VERSION ""

NS_ :

BS_:

BU_: HSCU BCM RINE BRUSA DCDC HVAC DECM BCM_HS HCSU ACCM_HS VICM_HS

BO_ 1120 BCM_Faults: 8 BCM
 SG_ bcm_dtc_081 m41 : 23|24@0+ (1,0) [0|16777215] "DTC ID"  HSCU
 SG_ bcm_dtc_082 m41 : 47|24@0+ (1,0) [0|16777215] "DTC ID"  HSCU
 SG_ bcm_dtc_083 m42 : 23|24@0+ (1,0) [0|16777215] "DTC ID"  HSCU
 SG_ bcm_dtc_084 m42 : 47|24@0+ (1,0) [0|16777215] "DTC ID"  HSCU
 SG_ bcm_dtc_085 m43 : 23|24@0+ (1,0) [0|16777215] "DTC ID"  HSCU
 SG_ bcm_dtc_086 m43 : 47|24@0+ (1,0) [0|16777215] "DTC ID"  HSCU
 SG_ bcm_dtc_087 m44 : 23|24@0+ (1,0) [0|16777215] "DTC ID"  HSCU
 SG_ bcm_dtc_088 m44 : 47|24@0+ (1,0) [0|16777215] "DTC ID"  HSCU
 SG_ bcm_dtc_089 m45 : 23|24@0+ (1,0) [0|16777215] "DTC ID"  HSCU
 SG_ bcm_dtc_090 m45 : 47|24@0+ (1,0) [0|16777215] "DTC ID"  HSCU
 SG_ bcm_dtc_091 m46 : 23|24@0+ (1,0) [0|16777215] "DTC ID"  HSCU
 SG_ bcm_dtc_092 m46 : 47|24@0+ (1,0) [0|16777215] "DTC ID"  HSCU
 SG_ bcm_dtc_093 m47 : 23|24@0+ (1,0) [0|16777215] "DTC ID"  HSCU
 SG_ bcm_dtc_094 m47 : 47|24@0+ (1,0) [0|16777215] "DTC ID"  HSCU
 SG_ bcm_dtc_095 m48 : 23|24@0+ (1,0) [0|16777215] "DTC ID"  HSCU
 SG_ bcm_dtc_096 m48 : 47|24@0+ (1,0) [0|16777215] "DTC ID"  HSCU
 SG_ bcm_dtc_097 m49 : 23|24@0+ (1,0) [0|16777215] "DTC ID"  HSCU
 SG_ bcm_dtc_098 m49 : 47|24@0+ (1,0) [0|16777215] "DTC ID"  HSCU
 SG_ bcm_dtc_099 m50 : 23|24@0+ (1,0) [0|16777215] "DTC ID"  HSCU
 SG_ bcm_dtc_100 m50 : 47|24@0+ (1,0) [0|16777215] "DTC ID"  HSCU
 SG_ bcm_dtc_statusMask m0 : 15|8@0+ (1,0) [0|255] "ISO14229 statusOfDTC"  HSCU
 SG_ bcm_dtc_page M : 7|8@0+ (1,0) [0|255] "page number"  HSCU

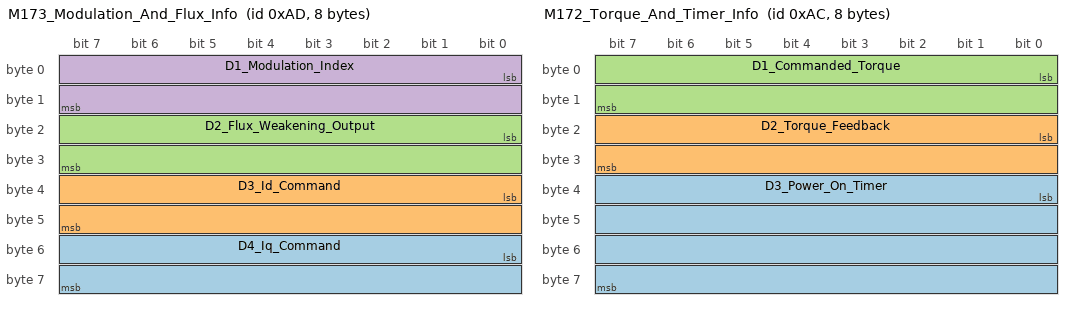
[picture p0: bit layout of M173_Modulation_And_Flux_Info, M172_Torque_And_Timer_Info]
BO_ 173 M173_Modulation_And_Flux_Info: 8 RINE
 SG_ D4_Iq_Command : 48|16@1- (0.1,0) [-3276.8|3276.7] "A" Vector__XXX
 SG_ D3_Id_Command : 32|16@1- (0.1,0) [-3276.8|3276.7] "A" Vector__XXX
 SG_ D2_Flux_Weakening_Output : 16|16@1- (0.1,0) [-3276.8|3276.7] "A" Vector__XXX
 SG_ D1_Modulation_Index : 0|16@1+ (0.01,0) [0|0] "" Vector__XXX

BO_ 172 M172_Torque_And_Timer_Info: 8 RINE
 SG_ D3_Power_On_Timer : 32|32@1+ (0.003,0) [0|4294970000] "Sec" Vector__XXX
 SG_ D2_Torque_Feedback : 16|16@1- (0.1,0) [-3276.8|3276.7] "Nm" Vector__XXX
 SG_ D1_Commanded_Torque : 0|16@1- (0.1,0) [-3276.8|3276.7] "Nm" Vector__XXX

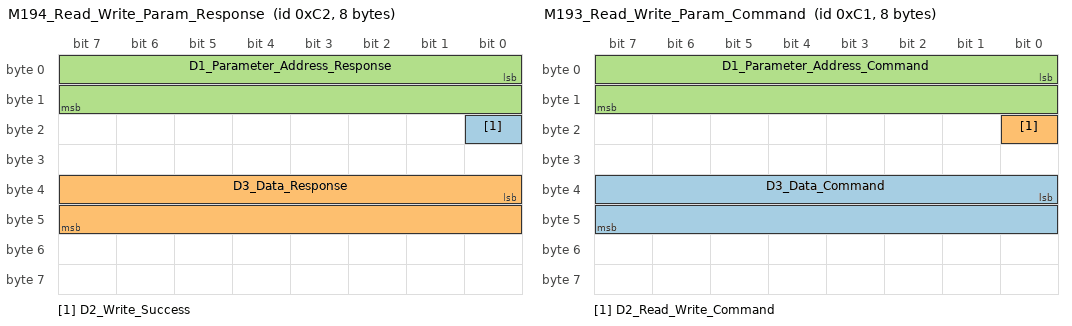
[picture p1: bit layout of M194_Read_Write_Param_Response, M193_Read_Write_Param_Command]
BO_ 194 M194_Read_Write_Param_Response: 8 RINE
 SG_ D2_Write_Success : 16|1@1+ (1,0) [0|1] "" Vector__XXX
 SG_ D3_Data_Response : 32|16@1- (1,0) [-32768|32767] "" Vector__XXX
 SG_ D1_Parameter_Address_Response : 0|16@1+ (1,0) [0|65535] "" Vector__XXX

BO_ 193 M193_Read_Write_Param_Command: 8 HSCU
 SG_ D3_Data_Command : 32|16@1- (1,0) [-32768|32767] "" Vector__XXX
 SG_ D2_Read_Write_Command : 16|1@1+ (1,0) [0|1] "" Vector__XXX
 SG_ D1_Parameter_Address_Command : 0|16@1+ (1,0) [0|65535] "" Vector__XXX

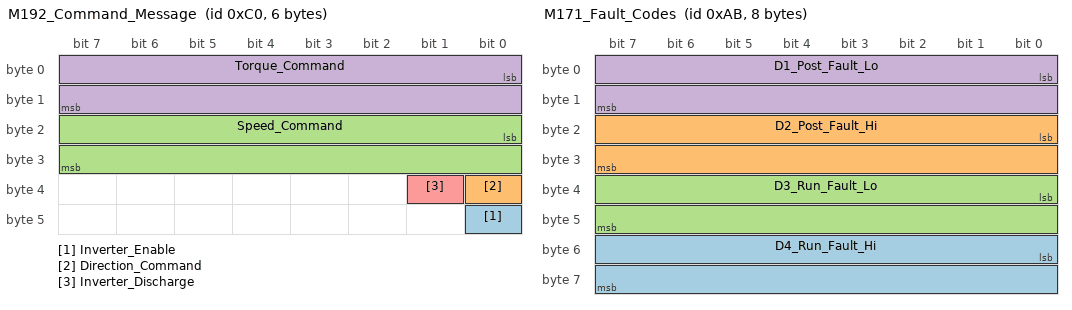
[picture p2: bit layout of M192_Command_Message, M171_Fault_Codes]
BO_ 192 M192_Command_Message: 6 HSCU
 SG_ Inverter_Enable : 40|1@1+ (1,0) [0|1] "Bit" Vector__XXX
 SG_ Direction_Command : 32|1@1+ (1,0) [0|1] "Bit" Vector__XXX
 SG_ Speed_Command : 16|16@1- (1,0) [-32768|32767] "rpm" Vector__XXX
 SG_ Torque_Command : 0|16@1- (0.1,0) [-3276.8|3276.7] "Nm" Vector__XXX
 SG_ Inverter_Discharge : 33|1@1+ (1,0) [0|1] "Bit" Vector__XXX

BO_ 171 M171_Fault_Codes: 8 RINE
 SG_ D4_Run_Fault_Hi : 48|16@1+ (1,0) [0|65535] "" Vector__XXX
 SG_ D2_Post_Fault_Hi : 16|16@1+ (1,0) [0|65535] "" Vector__XXX
 SG_ D3_Run_Fault_Lo : 32|16@1+ (1,0) [0|65535] "" Vector__XXX
 SG_ D1_Post_Fault_Lo : 0|16@1+ (1,0) [0|65535] "" Vector__XXX

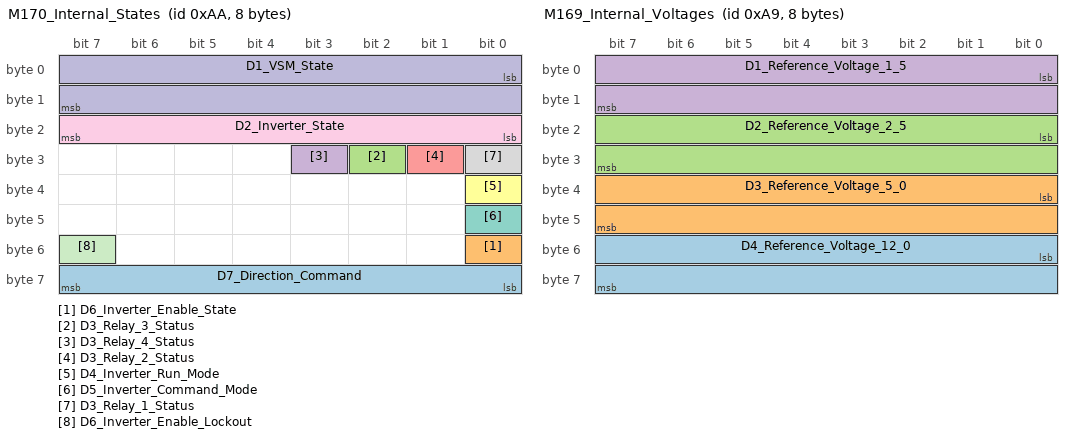
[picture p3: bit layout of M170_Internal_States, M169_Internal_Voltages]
BO_ 170 M170_Internal_States: 8 RINE
 SG_ D7_Direction_Command : 56|8@1+ (1,0) [0|1] "" Vector__XXX
 SG_ D6_Inverter_Enable_State : 48|1@1+ (1,0) [0|1] "" Vector__XXX
 SG_ D3_Relay_3_Status : 26|1@1+ (1,0) [0|1] "" Vector__XXX
 SG_ D3_Relay_4_Status : 27|1@1+ (1,0) [0|1] "" Vector__XXX
 SG_ D3_Relay_2_Status : 25|1@1+ (1,0) [0|1] "" Vector__XXX
 SG_ D4_Inverter_Run_Mode : 32|1@1+ (1,0) [0|1] "" Vector__XXX
 SG_ D5_Inverter_Command_Mode : 40|1@1+ (1,0) [0|1] "" Vector__XXX
 SG_ D3_Relay_1_Status : 24|1@1+ (1,0) [0|1] "" Vector__XXX
 SG_ D2_Inverter_State : 16|8@1+ (1,0) [0|255] "" Vector__XXX
 SG_ D1_VSM_State : 0|16@1+ (1,0) [0|15] "" Vector__XXX
 SG_ D6_Inverter_Enable_Lockout : 55|1@1+ (1,0) [0|1] "" Vector__XXX

BO_ 169 M169_Internal_Voltages: 8 RINE
 SG_ D4_Reference_Voltage_12_0 : 48|16@1- (0.01,0) [-327.68|327.67] "V" Vector__XXX
 SG_ D3_Reference_Voltage_5_0 : 32|16@1- (0.01,0) [-327.68|327.67] "V" Vector__XXX
 SG_ D2_Reference_Voltage_2_5 : 16|16@1- (0.01,0) [-327.68|327.67] "V" Vector__XXX
 SG_ D1_Reference_Voltage_1_5 : 0|16@1- (0.01,0) [-327.68|327.67] "V" Vector__XXX

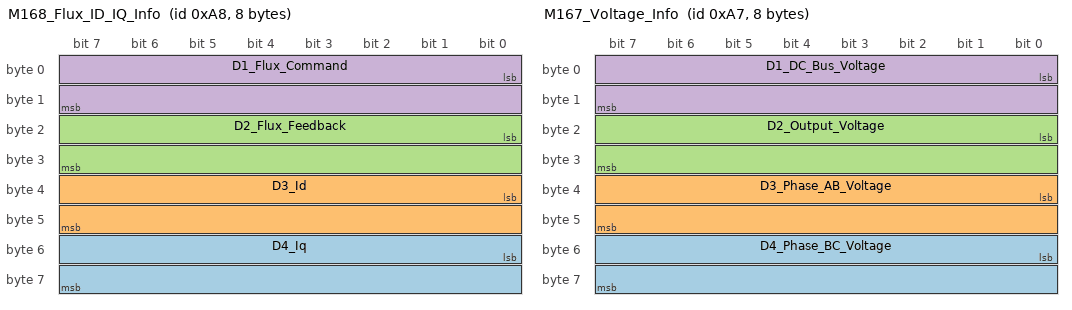
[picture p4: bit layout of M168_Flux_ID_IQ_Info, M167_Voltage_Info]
BO_ 168 M168_Flux_ID_IQ_Info: 8 RINE
 SG_ D4_Iq : 48|16@1- (0.1,0) [-3276.8|3276.7] "A" Vector__XXX
 SG_ D3_Id : 32|16@1- (0.1,0) [-3276.8|3276.7] "A" Vector__XXX
 SG_ D2_Flux_Feedback : 16|16@1- (0.001,0) [-32.768|32.767] "Wb" Vector__XXX
 SG_ D1_Flux_Command : 0|16@1- (0.001,0) [-32.768|32.767] "Wb" Vector__XXX

BO_ 167 M167_Voltage_Info: 8 RINE
 SG_ D4_Phase_BC_Voltage : 48|16@1- (0.1,0) [-3276.8|3276.7] "V" Vector__XXX
 SG_ D3_Phase_AB_Voltage : 32|16@1- (0.1,0) [-3276.8|3276.7] "V" Vector__XXX
 SG_ D2_Output_Voltage : 16|16@1- (0.1,0) [-3276.8|3276.7] "V" Vector__XXX
 SG_ D1_DC_Bus_Voltage : 0|16@1- (0.1,0) [-3276.8|3276.7] "V" Vector__XXX

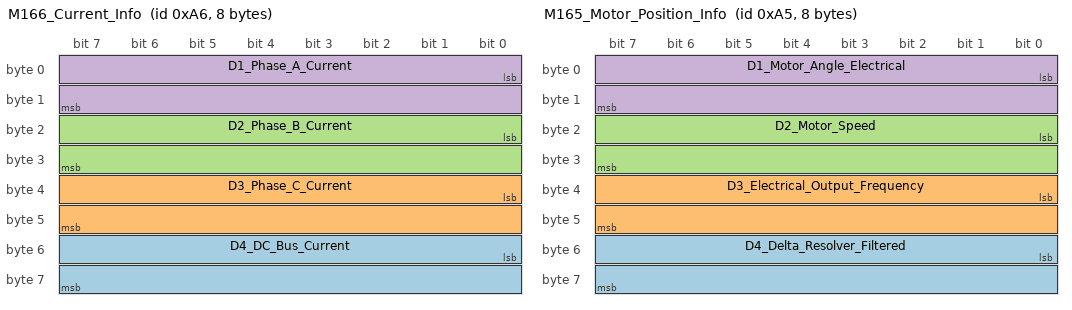
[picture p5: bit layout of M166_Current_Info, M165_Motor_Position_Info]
BO_ 166 M166_Current_Info: 8 RINE
 SG_ D4_DC_Bus_Current : 48|16@1- (0.1,0) [-3276.8|3276.7] "A" Vector__XXX
 SG_ D3_Phase_C_Current : 32|16@1- (0.1,0) [-3276.8|3276.7] "A" Vector__XXX
 SG_ D2_Phase_B_Current : 16|16@1- (0.1,0) [-3276.8|3276.7] "A" Vector__XXX
 SG_ D1_Phase_A_Current : 0|16@1- (0.1,0) [-3276.8|3276.7] "A" Vector__XXX

BO_ 165 M165_Motor_Position_Info: 8 RINE
 SG_ D4_Delta_Resolver_Filtered : 48|16@1- (0.1,0) [-3276.8|3276.7] "deg" Vector__XXX
 SG_ D3_Electrical_Output_Frequency : 32|16@1- (0.1,0) [-3276.8|3276.7] "hz" Vector__XXX
 SG_ D2_Motor_Speed : 16|16@1- (1,0) [-32768|32767] "rpm" Vector__XXX
 SG_ D1_Motor_Angle_Electrical : 0|16@1+ (0.1,0) [0|6553.5] "deg" Vector__XXX

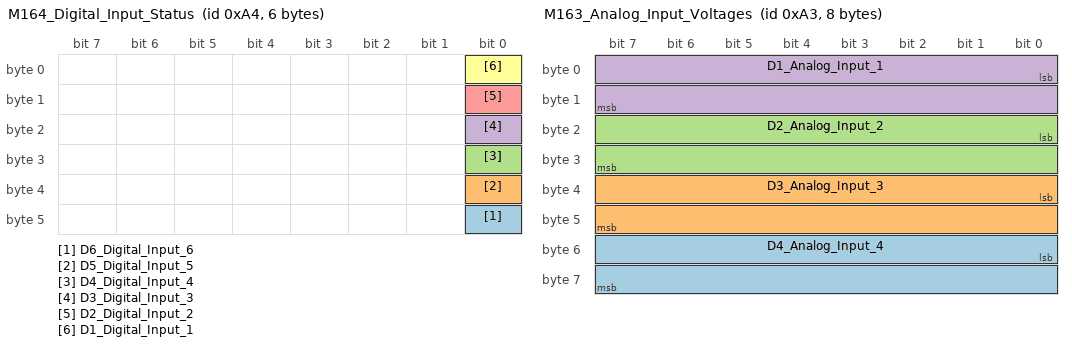
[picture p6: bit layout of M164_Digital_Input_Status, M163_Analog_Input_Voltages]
BO_ 164 M164_Digital_Input_Status: 6 RINE
 SG_ D6_Digital_Input_6 : 40|1@1+ (1,0) [0|1] "boolean" Vector__XXX
 SG_ D5_Digital_Input_5 : 32|1@1+ (1,0) [0|1] "boolean" Vector__XXX
 SG_ D4_Digital_Input_4 : 24|1@1+ (1,0) [0|1] "boolean" Vector__XXX
 SG_ D3_Digital_Input_3 : 16|1@1+ (1,0) [0|1] "boolean" Vector__XXX
 SG_ D2_Digital_Input_2 : 8|1@1+ (1,0) [0|1] "boolean" Vector__XXX
 SG_ D1_Digital_Input_1 : 0|1@1+ (1,0) [0|1] "boolean" Vector__XXX

BO_ 163 M163_Analog_Input_Voltages: 8 RINE
 SG_ D4_Analog_Input_4 : 48|16@1- (0.01,0) [-327.68|327.67] "V" Vector__XXX
 SG_ D3_Analog_Input_3 : 32|16@1- (0.01,0) [-327.68|327.67] "V" Vector__XXX
 SG_ D2_Analog_Input_2 : 16|16@1- (0.01,0) [-327.68|327.67] "V" Vector__XXX
 SG_ D1_Analog_Input_1 : 0|16@1- (0.01,0) [-327.68|327.67] "V" Vector__XXX

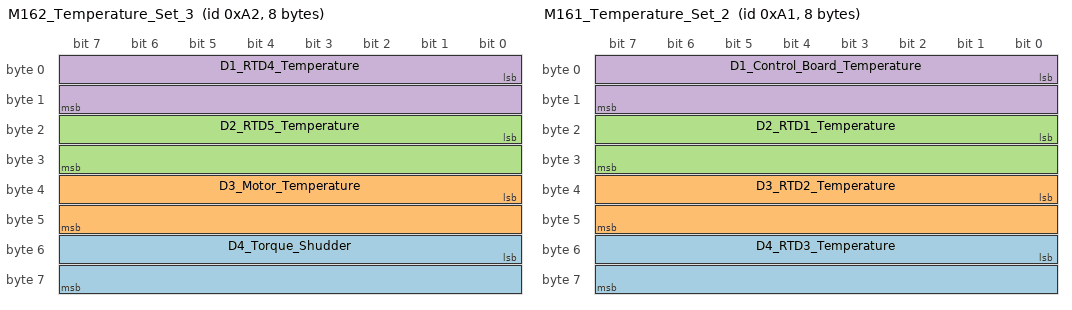
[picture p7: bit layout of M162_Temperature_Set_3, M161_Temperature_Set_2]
BO_ 162 M162_Temperature_Set_3: 8 RINE
 SG_ D4_Torque_Shudder : 48|16@1- (0.1,0) [-3276.8|3276.7] "Nm" Vector__XXX
 SG_ D3_Motor_Temperature : 32|16@1- (0.1,0) [-3276.8|3276.7] "degC" Vector__XXX
 SG_ D2_RTD5_Temperature : 16|16@1- (0.1,0) [-3276.8|3276.7] "degC" Vector__XXX
 SG_ D1_RTD4_Temperature : 0|16@1- (0.1,0) [-3276.8|3276.7] "degC" Vector__XXX

BO_ 161 M161_Temperature_Set_2: 8 RINE
 SG_ D4_RTD3_Temperature : 48|16@1- (0.1,0) [-3276.8|3276.7] "degC" Vector__XXX
 SG_ D3_RTD2_Temperature : 32|16@1- (0.1,0) [-3276.8|3276.7] "degC" Vector__XXX
 SG_ D2_RTD1_Temperature : 16|16@1- (0.1,0) [-3276.8|3276.7] "degC" Vector__XXX
 SG_ D1_Control_Board_Temperature : 0|16@1- (0.1,0) [-3276.8|3276.7] "degC" Vector__XXX

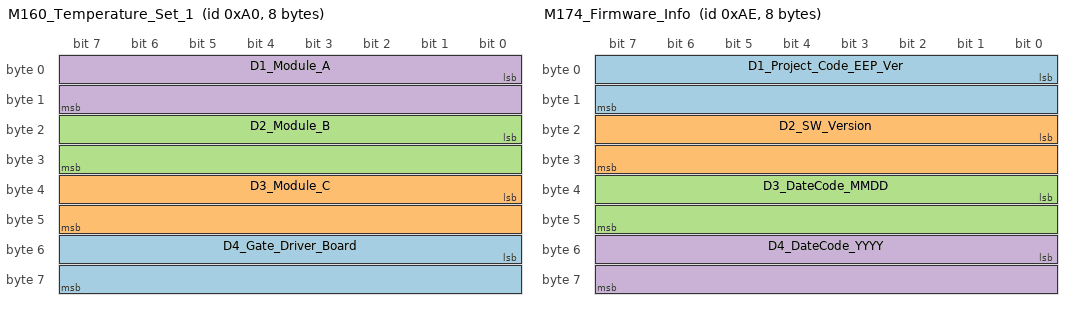
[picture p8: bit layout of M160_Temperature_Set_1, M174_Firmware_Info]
BO_ 160 M160_Temperature_Set_1: 8 RINE
 SG_ D4_Gate_Driver_Board : 48|16@1- (0.1,0) [-3276.8|3276.7] "degC" Vector__XXX
 SG_ D3_Module_C : 32|16@1- (0.1,0) [-3276.8|3276.7] "degC" Vector__XXX
 SG_ D2_Module_B : 16|16@1- (0.1,0) [-3276.8|3276.7] "degC" Vector__XXX
 SG_ D1_Module_A : 0|16@1- (0.1,0) [-3276.8|3276.7] "degC" Vector__XXX

BO_ 174 M174_Firmware_Info: 8 RINE
 SG_ D1_Project_Code_EEP_Ver : 0|16@1+ (1,0) [0|65535] "" Vector__XXX
 SG_ D2_SW_Version : 16|16@1+ (1,0) [0|65535] "" Vector__XXX
 SG_ D3_DateCode_MMDD : 32|16@1+ (1,0) [0|65535] "" Vector__XXX
 SG_ D4_DateCode_YYYY : 48|16@1+ (1,0) [0|65535] "" Vector__XXX

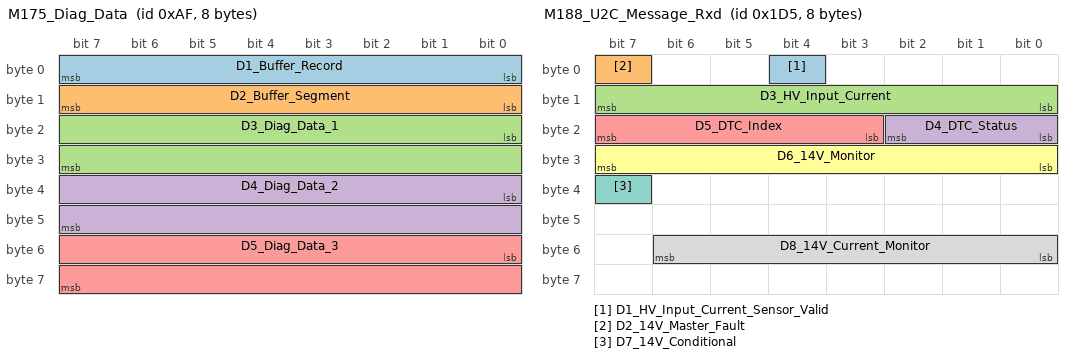
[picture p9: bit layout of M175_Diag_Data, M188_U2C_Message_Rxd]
BO_ 175 M175_Diag_Data: 8 RINE
 SG_ D1_Buffer_Record : 0|8@1+ (1,0) [0|160] "" Vector__XXX
 SG_ D2_Buffer_Segment : 8|8@1+ (1,0) [0|5] "" Vector__XXX
 SG_ D3_Diag_Data_1 : 16|16@1- (1,0) [0|65535] "" Vector__XXX
 SG_ D4_Diag_Data_2 : 32|16@1- (1,0) [0|65535] "" Vector__XXX
 SG_ D5_Diag_Data_3 : 48|16@1- (1,0) [0|65535] "" Vector__XXX

BO_ 471 M187_U2C_Command_Txd: 8 RINE
 SG_ D1_ID_Byte : 0|8@1+ (1,0) [0|255] "" Vector__XXX
 SG_ D2_Setpoint_Calc : 8|8@1+ (1,0) [0|255] "" Vector__XXX

BO_ 469 M188_U2C_Message_Rxd: 8 HSCU
 SG_ D1_HV_Input_Current_Sensor_Valid : 4|1@1+ (1,0) [0|1] "" Vector__XXX
 SG_ D2_14V_Master_Fault : 7|1@1+ (1,0) [0|1] "" Vector__XXX
 SG_ D3_HV_Input_Current : 8|8@1+ (1,0) [0|255] "" Vector__XXX
 SG_ D4_DTC_Status : 16|3@1+ (1,0) [0|7] "" Vector__XXX
 SG_ D5_DTC_Index : 19|5@1+ (1,0) [0|31] "" Vector__XXX
 SG_ D6_14V_Monitor : 24|8@1+ (1,0) [0|255] "" Vector__XXX
 SG_ D7_14V_Conditional : 39|1@1+ (1,0) [0|1] "" Vector__XXX
 SG_ D8_14V_Current_Monitor : 48|7@1+ (1,0) [0|127] "" Vector__XXX

BO_ 1556 NLG5_ERR: 5 BRUSA
 SG_ NLG5_W_PL_MV : 39|1@0+ (1,0) [0|1] ""  HSCU
 SG_ NLG5_W_PL_IT : 37|1@0+ (1,0) [0|1] ""  HSCU
 SG_ NLG5_W_PL_BV : 38|1@0+ (1,0) [0|1] ""  HSCU
 SG_ NLG5_W_C_VOR : 36|1@0+ (1,0) [0|1] ""  HSCU
 SG_ NLG5_E_WDT : 19|1@0+ (1,0) [0|1] ""  HSCU
 SG_ NLG5_E_T_TR : 11|1@0+ (1,0) [0|1] ""  HSCU
 SG_ NLG5_E_T_POW : 13|1@0+ (1,0) [0|1] ""  HSCU
 SG_ NLG5_E_T_EXT3 : 8|1@0+ (1,0) [0|1] ""  HSCU
 SG_ NLG5_E_T_EXT2 : 9|1@0+ (1,0) [0|1] ""  HSCU
 SG_ NLG5_E_T_EXT1 : 10|1@0+ (1,0) [0|1] ""  HSCU
 SG_ NLG5_E_T_DIO : 12|1@0+ (1,0) [0|1] ""  HSCU
 SG_ NLG5_E_T_C : 14|1@0+ (1,0) [0|1] ""  HSCU
 SG_ NLG5_E_SDT_CT : 26|1@0+ (1,0) [0|1] ""  HSCU
 SG_ NLG5_E_SDT_BV : 28|1@0+ (1,0) [0|1] ""  HSCU
 SG_ NLG5_E_SDT_BT : 29|1@0+ (1,0) [0|1] ""  HSCU
 SG_ NLG5_E_SDT_AH : 27|1@0+ (1,0) [0|1] ""  HSCU
 SG_ NLG5_E_SC : 4|1@0+ (1,0) [0|1] ""  HSCU
 SG_ NLG5_E_P_OM : 3|1@0+ (1,0) [0|1] ""  HSCU
 SG_ NLG5_E_P_MV : 2|1@0+ (1,0) [0|1] ""  HSCU
 SG_ NLG5_E_OOV : 7|1@0+ (1,0) [0|1] ""  HSCU
 SG_ NLG5_E_OF : 1|1@0+ (1,0) [0|1] ""  HSCU
 SG_ NLG5_E_NV_CRC : 22|1@0+ (1,0) [0|1] ""  HSCU
 SG_ NLG5_E_MOV_II : 5|1@0+ (1,0) [0|1] ""  HSCU
 SG_ NLG5_E_MOV_I : 6|1@0+ (1,0) [0|1] ""  HSCU
 SG_ NLG5_E_MF : 0|1@0+ (1,0) [0|1] ""  HSCU
 SG_ NLG5_E_INIT : 18|1@0+ (1,0) [0|1] ""  HSCU
 SG_ NLG5_E_F_CRC : 23|1@0+ (1,0) [0|1] ""  HSCU
 SG_ NLG5_E_ES_CRC : 21|1@0+ (1,0) [0|1] ""  HSCU
 SG_ NLG5_E_EP_CRC : 20|1@0+ (1,0) [0|1] ""  HSCU
 SG_ NLG5_E_C_TX : 31|1@0+ (1,0) [0|1] ""  HSCU
 SG_ NLG5_E_C_TO : 17|1@0+ (1,0) [0|1] ""  HSCU
 SG_ NLG5_E_C_RX : 30|1@0+ (1,0) [0|1] ""  HSCU
 SG_ NLG5_E_C_OFF : 16|1@0+ (1,0) [0|1] ""  HSCU
 SG_ NLG5_E_B_P : 15|1@0+ (1,0) [0|1] ""  HSCU

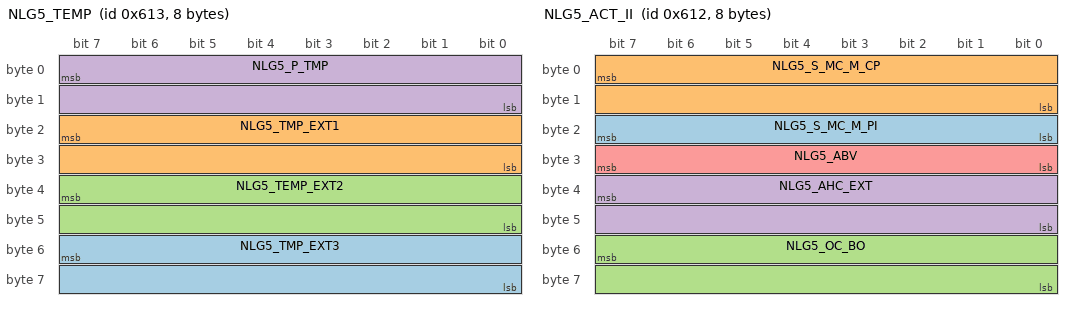
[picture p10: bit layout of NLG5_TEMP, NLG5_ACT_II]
BO_ 1555 NLG5_TEMP: 8 BRUSA
 SG_ NLG5_TMP_EXT3 : 55|16@0- (0.1,0) [-40|300] "°C"  HSCU
 SG_ NLG5_TMP_EXT1 : 23|16@0- (0.1,0) [-40|300] "°C"  HSCU
 SG_ NLG5_TEMP_EXT2 : 39|16@0- (0.1,0) [-40|300] "°C"  HSCU
 SG_ NLG5_P_TMP : 7|16@0- (0.1,0) [-40|300] "°C"  HSCU

BO_ 1554 NLG5_ACT_II: 8 BRUSA
 SG_ NLG5_S_MC_M_PI : 23|8@0+ (0.1,0) [0|20] "A"  HSCU
 SG_ NLG5_S_MC_M_CP : 7|16@0+ (0.1,0) [0|100] "A"  HSCU
 SG_ NLG5_OC_BO : 55|16@0+ (0.01,0) [0|50] "A"  HSCU
 SG_ NLG5_AHC_EXT : 39|16@0- (0.01,0) [-327.68|327.67] "Ah"  HSCU
 SG_ NLG5_ABV : 31|8@0+ (0.1,0) [0|25] "V"  HSCU

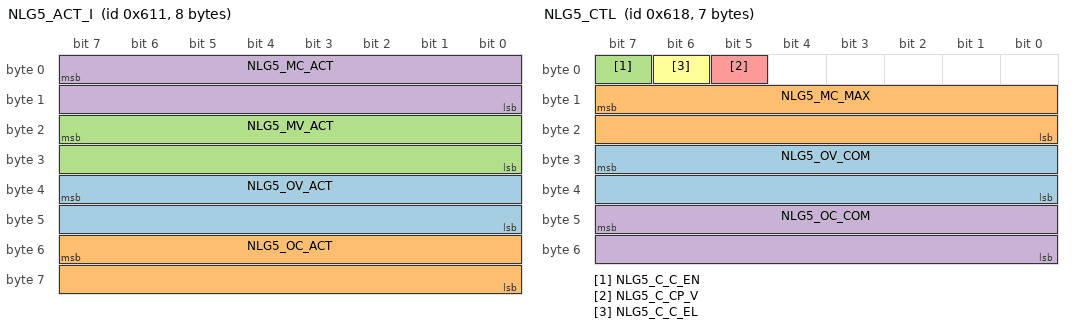
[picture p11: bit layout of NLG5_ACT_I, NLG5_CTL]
BO_ 1553 NLG5_ACT_I: 8 BRUSA
 SG_ NLG5_OV_ACT : 39|16@0+ (0.1,0) [0|1000] "V"  HSCU
 SG_ NLG5_OC_ACT : 55|16@0- (0.01,0) [0|150] "A"  HSCU
 SG_ NLG5_MV_ACT : 23|16@0+ (0.1,0) [0|500] "V"  HSCU
 SG_ NLG5_MC_ACT : 7|16@0+ (0.01,0) [0|50] "A"  HSCU

BO_ 1552 NLG5_ST: 4 BRUSA
 SG_ NLG5_S_WAR : 5|1@0+ (1,0) [0|1] ""  HSCU
 SG_ NLG5_S_UM_II : 1|1@0+ (1,0) [0|1] ""  HSCU
 SG_ NLG5_S_UM_I : 2|1@0+ (1,0) [0|1] ""  HSCU
 SG_ NLG5_S_HE : 7|1@0+ (1,0) [0|1] ""  HSCU
 SG_ NLG5_S_L_T_TR : 17|1@0+ (1,0) [0|1] ""  HSCU
 SG_ NLG5_S_L_T_POW : 19|1@0+ (1,0) [0|1] ""  HSCU
 SG_ NLG5_S_L_T_DIO : 18|1@0+ (1,0) [0|1] ""  HSCU
 SG_ NLG5_S_L_T_CPRIM : 20|1@0+ (1,0) [0|1] ""  HSCU
 SG_ NLG5_S_L_T_BATT : 16|1@0+ (1,0) [0|1] ""  HSCU
 SG_ NLG5_S_L_PMAX : 8|1@0+ (1,0) [0|1] ""  HSCU
 SG_ NLG5_S_L_PI : 10|1@0+ (1,0) [0|1] ""  HSCU
 SG_ NLG5_S_L_OV : 13|1@0+ (1,0) [0|1] ""  HSCU
 SG_ NLG5_S_L_OC_MAX : 22|1@0+ (1,0) [0|1] ""  HSCU
 SG_ NLG5_S_L_OC : 12|1@0+ (1,0) [0|1] ""  HSCU
 SG_ NLG5_S_L_MO_MAX : 21|1@0+ (1,0) [0|1] ""  HSCU
 SG_ NLG5_S_L_MC_MAX : 23|1@0+ (1,0) [0|1] ""  HSCU
 SG_ NLG5_S_L_MC : 11|1@0+ (1,0) [0|1] ""  HSCU
 SG_ NLG5_S_L_CP : 9|1@0+ (1,0) [0|1] ""  HSCU
 SG_ NLG5_S_FAN : 4|1@0+ (1,0) [0|1] ""  HSCU
 SG_ NLG5_S_EUM : 3|1@0+ (1,0) [0|1] ""  HSCU
 SG_ NLG5_S_ERR : 6|1@0+ (1,0) [0|1] ""  HSCU
 SG_ NLG5_S_CP_DT : 0|1@0+ (1,0) [0|1] ""  HSCU
 SG_ NLG5_S_BPD_II : 14|1@0+ (1,0) [0|1] ""  HSCU
 SG_ NLG5_S_BPD_I : 15|1@0+ (1,0) [0|1] ""  HSCU

BO_ 1560 NLG5_CTL: 7 HSCU
 SG_ NLG5_OV_COM : 31|16@0+ (0.1,0) [0|1000] "V"  BRUSA
 SG_ NLG5_MC_MAX : 15|16@0+ (0.1,0) [0|50] "A"  BRUSA
 SG_ NLG5_C_C_EN : 7|1@0+ (1,0) [0|1] ""  BRUSA
 SG_ NLG5_OC_COM : 47|16@0+ (0.1,0) [0|150] "A"  BRUSA
 SG_ NLG5_C_CP_V : 5|1@0+ (1,0) [0|1] ""  BRUSA
 SG_ NLG5_C_C_EL : 6|1@0+ (1,0) [0|1] ""  BRUSA

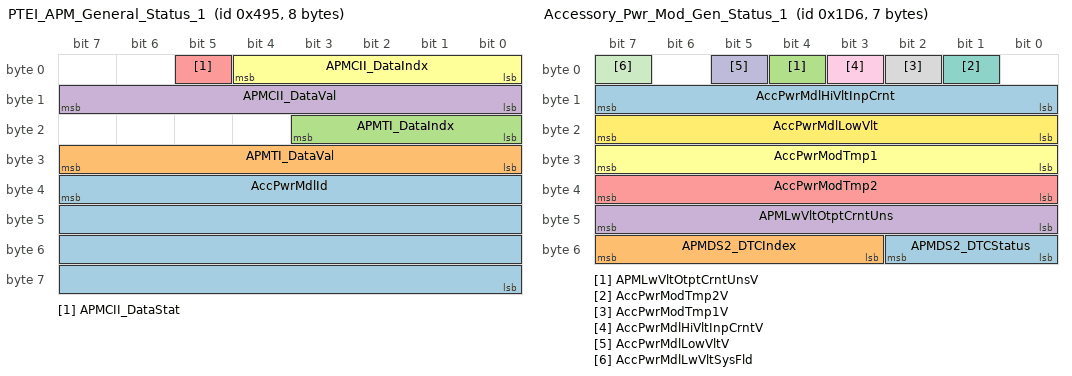
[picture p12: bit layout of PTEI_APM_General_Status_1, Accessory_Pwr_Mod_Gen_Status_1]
BO_ 1173 PTEI_APM_General_Status_1: 8 DCDC
 SG_ AccPwrMdlId : 39|32@0+ (1,0) [0|4294967295] "" Vector__XXX
 SG_ APMTI_DataVal : 31|8@0+ (1,0) [0|1] "" Vector__XXX
 SG_ APMTI_DataIndx : 19|4@0+ (1,0) [0|15] "" Vector__XXX
 SG_ APMCII_DataVal : 15|8@0+ (1,0) [0|255] "" Vector__XXX
 SG_ APMCII_DataStat : 5|1@0+ (1,0) [0|0] "" Vector__XXX
 SG_ APMCII_DataIndx : 4|5@0+ (1,0) [0|0] "" Vector__XXX

BO_ 1351 UUDT_Resp_From_APM_PE: 8 DCDC
 SG_ DgnInf : 7|64@0+ (1,0) [0|1.844674407371E+019] "" Vector__XXX

BO_ 1607 USDT_Resp_From_APM_PE: 8 DCDC
 SG_ DgnInf : 7|64@0+ (1,0) [0|1.844674407371E+019] "" Vector__XXX

BO_ 470 Accessory_Pwr_Mod_Gen_Status_1: 7 DCDC
 SG_ APMDS2_DTCStatus : 50|3@0+ (1,0) [0|7] ""  HSCU
 SG_ APMDS2_DTCIndex : 55|5@0+ (1,0) [0|31] ""  HSCU
 SG_ APMLwVltOtptCrntUnsV : 4|1@0+ (1,0) [0|0] ""  HSCU
 SG_ APMLwVltOtptCrntUns : 47|8@0+ (1,0) [0|255] "A"  HSCU
 SG_ AccPwrModTmp2 : 39|8@0+ (1,-40) [-40|215] "deg C"  HSCU
 SG_ AccPwrModTmp1 : 31|8@0+ (1,-40) [-40|215] "deg C"  HSCU
 SG_ AccPwrModTmp2V : 1|1@0+ (1,0) [0|1] ""  HSCU
 SG_ AccPwrModTmp1V : 2|1@0+ (1,0) [0|1] ""  HSCU
 SG_ AccPwrMdlHiVltInpCrntV : 3|1@0+ (1,0) [0|1] ""  HSCU
 SG_ AccPwrMdlLowVltV : 5|1@0+ (1,0) [0|1] ""  HSCU
 SG_ AccPwrMdlLwVltSysFld : 7|1@0+ (1,0) [0|1] ""  HSCU
 SG_ AccPwrMdlLowVlt : 23|8@0+ (0.0784314,0) [0|20.000007] "volts"  HSCU
 SG_ AccPwrMdlHiVltInpCrnt : 15|8@0+ (0.125,-5) [-5|26.875] "A"  HSCU

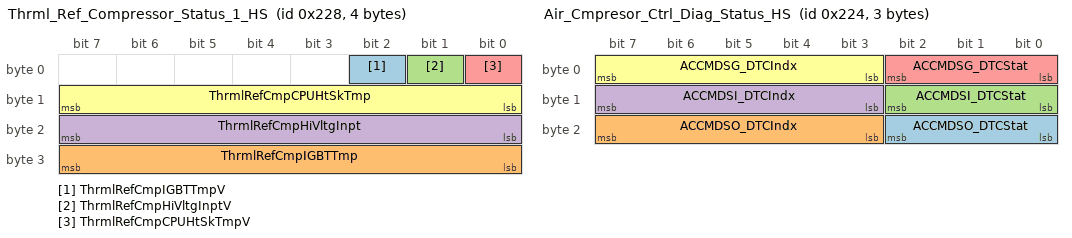
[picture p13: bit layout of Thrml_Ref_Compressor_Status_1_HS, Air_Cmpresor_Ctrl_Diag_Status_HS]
BO_ 552 Thrml_Ref_Compressor_Status_1_HS: 4 HVAC
 SG_ ThrmlRefCmpIGBTTmpV : 2|1@0+ (1,0) [0|0] "" Vector__XXX
 SG_ ThrmlRefCmpIGBTTmp : 31|8@0+ (1,-40) [-40|215] "deg C" Vector__XXX
 SG_ ThrmlRefCmpHiVltgInptV : 1|1@0+ (1,0) [0|0] "" Vector__XXX
 SG_ ThrmlRefCmpHiVltgInpt : 23|8@0+ (4,0) [0|1020] "V" Vector__XXX
 SG_ ThrmlRefCmpCPUHtSkTmpV : 0|1@0+ (1,0) [0|0] "" Vector__XXX
 SG_ ThrmlRefCmpCPUHtSkTmp : 15|8@0+ (1,-40) [-40|215] "deg C" Vector__XXX

BO_ 548 Air_Cmpresor_Ctrl_Diag_Status_HS: 3 HVAC
 SG_ ACCMDSO_DTCStat : 18|3@0+ (1,0) [0|0] "" Vector__XXX
 SG_ ACCMDSO_DTCIndx : 23|5@0+ (1,0) [0|31] "" Vector__XXX
 SG_ ACCMDSI_DTCStat : 10|3@0+ (1,0) [0|0] "" Vector__XXX
 SG_ ACCMDSI_DTCIndx : 15|5@0+ (1,0) [0|31] "" Vector__XXX
 SG_ ACCMDSG_DTCStat : 2|3@0+ (1,0) [0|0] "" Vector__XXX
 SG_ ACCMDSG_DTCIndx : 7|5@0+ (1,0) [0|31] "" Vector__XXX

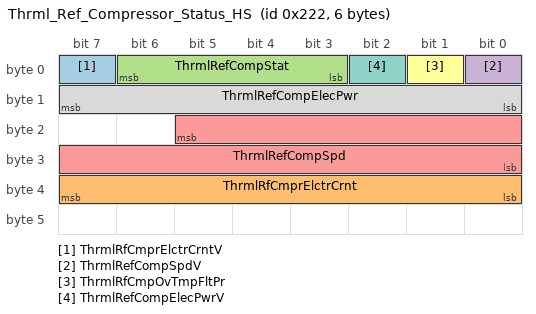
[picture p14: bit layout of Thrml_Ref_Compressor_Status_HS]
BO_ 546 Thrml_Ref_Compressor_Status_HS: 6 HVAC
 SG_ ThrmlRfCmprElctrCrntV : 7|1@0+ (1,0) [0|0] "" Vector__XXX
 SG_ ThrmlRfCmprElctrCrnt : 39|8@0+ (0.2,0) [0|51] "A" Vector__XXX
 SG_ ThrmlRefCompStat : 6|4@0+ (1,0) [0|0] "" Vector__XXX
 SG_ ThrmlRefCompSpdV : 0|1@0+ (1,0) [0|0] "" Vector__XXX
 SG_ ThrmlRefCompSpd : 21|14@0+ (1,0) [0|16383] "rpm" Vector__XXX
 SG_ ThrmlRfCmpOvTmpFltPr : 1|1@0+ (1,0) [0|1] "" Vector__XXX
 SG_ ThrmlRefCompElecPwrV : 2|1@0+ (1,0) [0|0] "" Vector__XXX
 SG_ ThrmlRefCompElecPwr : 15|8@0+ (0.04,0) [0|10.2] "kW" Vector__XXX

BO_ 1372 UUDT_Resp_From_ACCM_HS: 8 HVAC
 SG_ DgnInf_HS55C : 7|64@0+ (1,0) [0|1.844674407371E+019] "" Vector__XXX

BO_ 1628 USDT_Resp_From_ACCM_HS: 8 HVAC
 SG_ DgnInf : 7|64@0+ (1,0) [0|1.844674407371E+019] "" Vector__XXX

CM_ SG_ 173 D4_Iq_Command "The commanded Q-axis current";
CM_ SG_ 173 D3_Id_Command "The commanded D-axis current";
CM_ SG_ 173 D2_Flux_Weakening_Output "This is the current output of the flux regulator.";
CM_ SG_ 173 D1_Modulation_Index "This is the modulation index. The scale factor is x100. To get the actual modulation index divide the value by 100.";
CM_ SG_ 172 D3_Power_On_Timer "Updated every 3 msec. This will roll over in approximately 150 days!";
CM_ SG_ 172 D2_Torque_Feedback "Estimated motor torque feedback";
CM_ SG_ 172 D1_Commanded_Torque "The commanded Torque";
CM_ BO_ 194 "To write a parameter use message 0x0C1 with byte #2 set to 1 (write). 
To read a parameter use message 0x0C1 with byte #2 to set 0 (read). ";
CM_ SG_ 194 D2_Write_Success "0=Write failure, 1=Success";
CM_ SG_ 194 D3_Data_Response "All EEPROM data is 16 bits and is contained in bytes 4 and 5. Bytes 6 and 7 should be ignored.";
CM_ SG_ 194 D1_Parameter_Address_Response "Valid EEPROM Parameter CAN addresses are between 100 and 499.";
CM_ BO_ 193 "To write a parameter use message 0x0C1 with byte #2 set to 1 (write). 
To read a parameter use message 0x0C1 with byte #2 to set 0 (read). ";
CM_ SG_ 193 D3_Data_Command "All EEPROM data is 16 bits and is contained in bytes 4 and 5.";
CM_ SG_ 193 D2_Read_Write_Command "0=Read, 1=Write";
CM_ SG_ 193 D1_Parameter_Address_Command "Valid EEPROM Parameter CAN addresses are between 100 and 499.";
CM_ BO_ 192 "The command message is used to transmit data to the controller. This message is sent from a user supplied external controller to the PMxxx controller.";
CM_ SG_ 192 Inverter_Enable "0=Inverter OFF, 1 = Inverter ON";
CM_ SG_ 192 Direction_Command "0=CW, 1=CCW as veiwed from the shaft end of the motor";
CM_ SG_ 192 Speed_Command "Speed commandused when in speed mode";
CM_ SG_ 192 Torque_Command "Torque command when in torque mode";
CM_ SG_ 192 Inverter_Discharge "0=Discharge Disable,
=Discharge Enable";
CM_ SG_ 171 D4_Run_Fault_Hi "Each bit represents a fault. Please refer to PM100 Users Manual for details.";
CM_ SG_ 171 D2_Post_Fault_Hi "Each bit represents a fault. Please refer to PM100 Users Manual for details.";
CM_ SG_ 171 D3_Run_Fault_Lo "Each bit represents a fault. Please refer to PM100 Users Manual for details.";
CM_ SG_ 171 D1_Post_Fault_Lo "Each bit represents a fault. Please refer to PM100 Users Manual for details.";
CM_ SG_ 170 D7_Direction_Command "1 = Forward
0 = 'Reverse' if inverter enabled  & 'Stopped' if inverter is disabled";
CM_ SG_ 170 D6_Inverter_Enable_State "0=Inverter Disabled, 
1=Inverter Enabled";
CM_ SG_ 170 D3_Relay_3_Status "0=OFF, 1=ON";
CM_ SG_ 170 D3_Relay_4_Status "0=OFF, 1=ON";
CM_ SG_ 170 D3_Relay_2_Status "0=OFF, 1=ON";
CM_ SG_ 170 D4_Inverter_Run_Mode "0=Torque Mode, 1=Speed Mode";
CM_ SG_ 170 D5_Inverter_Command_Mode "0=CAN mode, 1=VSM mode";
CM_ SG_ 170 D3_Relay_1_Status "0=OFF, 1=ON";
CM_ SG_ 170 D2_Inverter_State "Different states for the inverter state machine";
CM_ SG_ 170 D1_VSM_State "Different states for the vehicle state machine";
CM_ SG_ 170 D6_Inverter_Enable_Lockout "0=Lockout Disabled, 1=Lockout Enabled";
CM_ SG_ 168 D2_Flux_Feedback "The estimated flux";
CM_ SG_ 168 D1_Flux_Command "The commanded flux";
CM_ SG_ 167 D4_Phase_BC_Voltage "Measured value of the voltage between Phase B and Phase C";
CM_ SG_ 167 D3_Phase_AB_Voltage "Measured value of the voltage betwen phase A and Phase B";
CM_ SG_ 167 D2_Output_Voltage "The calculated value of the output voltage, in peak line-neutral volts";
CM_ SG_ 167 D1_DC_Bus_Voltage "The actual measured value of the DC bus voltage";
CM_ SG_ 166 D4_DC_Bus_Current "The Calculated DC Bus Current";
CM_ SG_ 166 D3_Phase_C_Current "The measured value of Phase C current";
CM_ SG_ 166 D2_Phase_B_Current "The measured value of Phase B current";
CM_ SG_ 166 D1_Phase_A_Current "The measured value of Phase A current";
CM_ SG_ 165 D4_Delta_Resolver_Filtered "Used in calibration of resolver angle adjustment.";
CM_ SG_ 165 D3_Electrical_Output_Frequency "The actual electrical frequency of the inverter";
CM_ SG_ 165 D2_Motor_Speed "The measured speed of the motor";
CM_ SG_ 165 D1_Motor_Angle_Electrical "The Electrical Angle of the motor as read by the encoder or resolver";
CM_ SG_ 164 D6_Digital_Input_6 "Status of Digital Input #6";
CM_ SG_ 164 D5_Digital_Input_5 "Status of Digital Input #5";
CM_ SG_ 164 D4_Digital_Input_4 "Status of Digital Input #4";
CM_ SG_ 164 D3_Digital_Input_3 "Status of Digital Input #3";
CM_ SG_ 164 D2_Digital_Input_2 "Status of Digital Input #2";
CM_ SG_ 164 D1_Digital_Input_1 "Status of Digital Input #1";
CM_ SG_ 163 D4_Analog_Input_4 "Voltage on Analog Input #4";
CM_ SG_ 163 D3_Analog_Input_3 "Voltage on Analog Input #3";
CM_ SG_ 163 D2_Analog_Input_2 "Voltage on Analog Input #2";
CM_ SG_ 163 D1_Analog_Input_1 "Voltage on Analog Input #1";
CM_ SG_ 162 D4_Torque_Shudder "Shudder compensation value of torque";
CM_ SG_ 162 D3_Motor_Temperature "Motor Temperature Sensor";
CM_ SG_ 162 D2_RTD5_Temperature "RTD 5 (PT1000) Temperature";
CM_ SG_ 162 D1_RTD4_Temperature "RTD 4 (PT1000) Temperature";
CM_ SG_ 161 D4_RTD3_Temperature "RTD input 3 (PT1000) Temperature";
CM_ SG_ 161 D3_RTD2_Temperature "RTD input 2 (PT1000) Temperature";
CM_ SG_ 161 D2_RTD1_Temperature "RTD input 1 (PT1000) Temperature";
CM_ SG_ 161 D1_Control_Board_Temperature "Control Board Temperature";
CM_ SG_ 160 D4_Gate_Driver_Board "Gate Driver Board Temperature";
CM_ SG_ 160 D3_Module_C "IGBT Module C Temperature";
CM_ SG_ 160 D2_Module_B "IGBT Module B Temperature";
CM_ SG_ 160 D1_Module_A "IGBT Module A Temperature";
CM_ SG_ 1556 NLG5_W_PL_MV "Output power limited by low mains voltage";
CM_ SG_ 1556 NLG5_W_PL_IT "Output power limited by charger internal overtemperature";
CM_ SG_ 1556 NLG5_W_PL_BV "Output power limited by low battery voltage";
CM_ SG_ 1556 NLG5_W_C_VOR "Commanded value is out of specified range; max or min applicable value is assumed instead";
CM_ SG_ 1556 NLG5_E_WDT "Internal Watchdog Timeout";
CM_ SG_ 1556 NLG5_E_T_TR "Temperature sensor for transformer defective";
CM_ SG_ 1556 NLG5_E_T_POW "Temperature sensor for prim power stage defective";
CM_ SG_ 1556 NLG5_E_T_EXT3 "Ext. temperature sensor 3 defective (if enabled)";
CM_ SG_ 1556 NLG5_E_T_EXT2 "Ext. temperature sensor 2 defective (if enabled)";
CM_ SG_ 1556 NLG5_E_T_EXT1 "Ext. temperature sensor 1 defective (if enabled)";
CM_ SG_ 1556 NLG5_E_T_DIO "Temperature sensor for diodes defective";
CM_ SG_ 1556 NLG5_E_T_C "Temperature sensor for prim capacitor defective";
CM_ SG_ 1556 NLG5_E_SDT_CT "Emergency Shutdown Threshold 'Charging Time' is exceeded; see ChargeStar help section 'protective features';  error can only be cleared by cycling power ON-OFF-ON";
CM_ SG_ 1556 NLG5_E_SDT_BV "Emergency Shutdown Threshold 'Battery Voltage' is exceeded; see ChargeStar help section 'protective features';  error can only be cleared by cycling power ON-OFF-ON";
CM_ SG_ 1556 NLG5_E_SDT_BT "Emergency Shutdown Threshold 'Battery Temperature' is exceeded; see ChargeStar help section 'protective features';  error can only be cleared by cycling power ON-OFF-ON";
CM_ SG_ 1556 NLG5_E_SDT_AH "Emergency Shutdown Threshold 'Amp Hours' is exceeded; see ChargeStar help section 'protective features';  error can only be cleared by cycling power ON-OFF-ON";
CM_ SG_ 1556 NLG5_E_SC "power stage short circuit condition detected; error can only be cleared by cycling power ON-OFF-ON";
CM_ SG_ 1556 NLG5_E_P_OM "plausibility battery output voltage measurement wrong";
CM_ SG_ 1556 NLG5_E_P_MV "plausibility mains voltage measurement wrong";
CM_ SG_ 1556 NLG5_E_OOV "battery output overvoltage; error can only be cleared by cycling power ON-OFF-ON 
";
CM_ SG_ 1556 NLG5_E_OF "output fuse defective";
CM_ SG_ 1556 NLG5_E_NV_CRC "NVSRAM check sum failure; contains most of the scaling & calibration values, CAN ID's and  charging profile etc.";
CM_ SG_ 1556 NLG5_E_MOV_II "Mains overvoltage 2 detected";
CM_ SG_ 1556 NLG5_E_MOV_I "Mains overvoltage 1 detected";
CM_ SG_ 1556 NLG5_E_MF "Mains fuse defective";
CM_ SG_ 1556 NLG5_E_INIT "Initialization error";
CM_ SG_ 1556 NLG5_E_F_CRC "Flash memory checksum failure";
CM_ SG_ 1556 NLG5_E_ES_CRC "Sys EEPROM checksum failure";
CM_ SG_ 1556 NLG5_E_EP_CRC "Pow EEPROM checksum failure";
CM_ SG_ 1556 NLG5_E_C_TX "CAN transmit buffer >127";
CM_ SG_ 1556 NLG5_E_C_TO "CAN timeout, no control message received for >300ms";
CM_ SG_ 1556 NLG5_E_C_RX "CAN receiver buffer >127";
CM_ SG_ 1556 NLG5_E_C_OFF "CAN off, transmit buffer >255";
CM_ SG_ 1556 NLG5_E_B_P "wrong battery polarity;  error can only be cleared by cycling power ON-OFF-ON";
CM_ SG_ 1555 NLG5_TMP_EXT3 "Value of external battery temperature sensor #3 (if connected and enabled)";
CM_ SG_ 1555 NLG5_TMP_EXT1 "Value of external battery temperature sensor #1 (if connected and enabled)";
CM_ SG_ 1555 NLG5_TEMP_EXT2 "Value of external battery temperature sensor #2 (if connected and enabled)";
CM_ SG_ 1555 NLG5_P_TMP "Power stage temperature";
CM_ SG_ 1554 NLG5_S_MC_M_PI "Value of mains current limit, commanded by the 'power indicator' (PI) analog input signal";
CM_ SG_ 1554 NLG5_S_MC_M_CP "Value of mains current limit, commanded by the control pilot (SAE J1772) signal";
CM_ SG_ 1554 NLG5_OC_BO "output current of the booster (if one is present and active)";
CM_ SG_ 1554 NLG5_AHC_EXT "Charge balance obtained via  Ext. Ah counter connected to DI1 / DI2";
CM_ SG_ 1554 NLG5_ABV "Aux battery voltage";
CM_ SG_ 1553 NLG5_OV_ACT "Actual battery output voltage";
CM_ SG_ 1553 NLG5_OC_ACT "output current to the battery";
CM_ SG_ 1553 NLG5_MV_ACT "Actual mains voltage";
CM_ SG_ 1553 NLG5_MC_ACT "Actual mains current";
CM_ SG_ 1552 NLG5_S_WAR "Warning condition on, i.e. charging power limited due to any limiting condition; red LED is blinking";
CM_ SG_ 1552 NLG5_S_UM_II "US mains level 2 (240VAC / 60Hz) detected";
CM_ SG_ 1552 NLG5_S_UM_I "US mains level 1 (120VAC / 60Hz) detected";
CM_ SG_ 1552 NLG5_S_HE "Indicates if hardware enabled, i.e. a hi or lo signal is fed to the 'Power On' pin (pin3 of control connector)";
CM_ SG_ 1552 NLG5_S_L_T_TR "Output power limited by temperature of transformer";
CM_ SG_ 1552 NLG5_S_L_T_POW "Output power limited by temperature of power stage";
CM_ SG_ 1552 NLG5_S_L_T_DIO "Output power limited by temperature of diodes";
CM_ SG_ 1552 NLG5_S_L_T_CPRIM "Output power limited by temperature of primary capacitors";
CM_ SG_ 1552 NLG5_S_L_T_BATT "Output power limited by battery temperature";
CM_ SG_ 1552 NLG5_S_L_PMAX "Output power limited by maximum power capability of NLG5";
CM_ SG_ 1552 NLG5_S_L_PI "Output power limited by analog input 'power indicator' (PI) limit";
CM_ SG_ 1552 NLG5_S_L_OV "Output power limited by battery output voltage limit";
CM_ SG_ 1552 NLG5_S_L_OC_MAX "Output power limited by maximum output current capability of NLG5";
CM_ SG_ 1552 NLG5_S_L_OC "Output power limited by battery output current limit";
CM_ SG_ 1552 NLG5_S_L_MO_MAX "Output power limited by maximum output voltage capability of NLG5";
CM_ SG_ 1552 NLG5_S_L_MC_MAX "Output power limited by maximum mains current capability of NLG5";
CM_ SG_ 1552 NLG5_S_L_MC "Output power limited by mains current limit";
CM_ SG_ 1552 NLG5_S_L_CP "Output power limited by control pilot signal (SAE J1772)";
CM_ SG_ 1552 NLG5_S_FAN "Charger cooling fan is active";
CM_ SG_ 1552 NLG5_S_EUM "European mains input detected (230V, 50Hz)";
CM_ SG_ 1552 NLG5_S_ERR "An error has been detected, red LED is ON, no power is output";
CM_ SG_ 1552 NLG5_S_CP_DT "Control pilot signal (SAE J1772) detected ";
CM_ SG_ 1552 NLG5_S_BPD_II "Bypass detection bit 2; 00: no bypass, 01: DC bypass detected, 10:AC bypass in phase, 11: AC bypass not in phase";
CM_ SG_ 1552 NLG5_S_BPD_I "Bypass detection bit 1; 00: no bypass, 01: DC bypass detected, 10:AC bypass in phase, 11: AC bypass not in phase";
CM_ SG_ 1560 NLG5_OV_COM "Desired voltage to be output to the battery. Must always contain a valid value in order to keep on charging.";
CM_ SG_ 1560 NLG5_MC_MAX "Maximum current to be drawn from the mains outlet, usually 16A. Must always contain a valid value in order to keep on charging.";
CM_ SG_ 1560 NLG5_C_C_EN "Must be ON to enable power stage of the charger";
CM_ SG_ 1560 NLG5_OC_COM "Desired battery current. Must always contain a valid value in order to keep on charging.";
CM_ SG_ 1560 NLG5_C_CP_V "special signal to tell a charging station equipped with the Control Pilot interface (SAE J1772) to switch on the facility's ventilation (in order to get rid of battery gases like hydrogen, e.g.)";
CM_ SG_ 1560 NLG5_C_C_EL "cycle this value 0-1-0 to clear all latched charger errors ";
BA_DEF_ SG_  "GenSigStartValue" INT 0 0;
BA_DEF_ BO_  "GenMsgCycleTime" INT 0 1000;
BA_DEF_ SG_  "SystemSignalLongSymbol" STRING ;
BA_DEF_DEF_  "GenSigStartValue" 0;
BA_DEF_DEF_  "GenMsgCycleTime" 100;
BA_DEF_DEF_  "SystemSignalLongSymbol" "";
BA_ "GenMsgCycleTime" BO_ 172 10;
BA_ "GenMsgCycleTime" BO_ 194 10;
BA_ "GenMsgCycleTime" BO_ 193 10;
BA_ "GenMsgCycleTime" BO_ 192 5;
BA_ "GenMsgCycleTime" BO_ 168 10;
BA_ "GenMsgCycleTime" BO_ 167 10;
BA_ "GenMsgCycleTime" BO_ 166 10;
BA_ "GenMsgCycleTime" BO_ 165 10;
BA_ "GenMsgCycleTime" BO_ 164 10;
BA_ "GenMsgCycleTime" BO_ 163 10;
BA_ "GenMsgCycleTime" BO_ 1556 1000;
BA_ "GenMsgCycleTime" BO_ 1555 1000;
BA_ "GenMsgCycleTime" BO_ 1173 1000;
BA_ "GenMsgCycleTime" BO_ 1351 0;
BA_ "GenMsgCycleTime" BO_ 1607 0;
BA_ "GenMsgCycleTime" BO_ 470 25;
BA_ "SystemSignalLongSymbol" SG_ 469 D1_HV_Input_Current_Sensor_Valid "D1_HV_Input_Current_Sensor_Validity";
VAL_ 1120 bcm_dtc_081 0 " - " 11276288 "DTC_VEPO" 11276289 "DTC_HSC_MISSING" 11460608 "DTC_NVM_SOC" 11460609 "DTC_NVM_KOT" 11460610 "DTC_NVM_DTC" 11460611 "DTC_NVM_SOC_CORRECTION" 11460612 "DTC_NVM_APP_SCRATCHPAD" 11517962 "DTC_LOOPTIME_TASK_A" 11517963 "DTC_LOOPTIME_TASK_B" 11517964 "DTC_LOOPTIME_TASK_C" 11517965 "DTC_LOOPTIME_TASK_D" 11517966 "DTC_LOOPTIME_TASK_E" 11517967 "DTC_LOOPTIME_TASK_F" 11323904 "DTC_INTERLOCK_A_FAILED_LOW" 11323905 "DTC_INTERLOCK_A_FAILED_HIGH" 11324160 "DTC_INTERLOCK_B_FAILED_LOW" 11324161 "DTC_INTERLOCK_B_FAILED_HIGH" 15728640 "DTC_EPO" 16498688 "DTC_BRUSA_MISSING" 16498689 "DTC_BRUSA_IDC" 16498690 "DTC_BRUSA_REQ_VS_CMD" 16433152 "DTC_AKERWADE_MISSING" 16433153 "DTC_AKERWADE_IDC" 16433154 "DTC_AKERWADE_REQ_VS_CMD" 16564224 "DTC_CHGLEAR_MISSING" 16564225 "DTC_CHGLEAR_IDC" 16564226 "DTC_CHGLEAR_REQ_VS_CMD" 16522240 "DTC_CSM_MISSING" 16522752 "DTC_CSM_VBAT" 16522753 "DTC_CSM_VPOS" 16522754 "DTC_CSM_VNEG" 16522755 "DTC_CSM_CPOS" 16522756 "DTC_CSM_CNEG" 16522757 "DTC_CSM_APOS" 16522758 "DTC_CSM_ANEG" 16522759 "DTC_CSM_FUSE_HI" 16522760 "DTC_CSM_FUSE_LO" 16521728 "DTC_CSM_ASIC" 16521729 "DTC_CSM_AILO" 16521730 "DTC_CSM_AIHI" 16520957 "DTC_LEAKAGE_DETECT_FAULT" 16522444 "DTC_REALTIMECLOCK_FAULT" 16520945 "DTC_CSM_LEAK_FAIL_CALC" 16520946 "DTC_CSM_LEAK_FAIL_HW" 16520947 "DTC_CSM_LEAK_EXT_SHORT" 16520948 "DTC_CSM_LEAK_MID_PACK_SHORT" 16520949 "DTC_CSM_LEAK_ERROR" 16520950 "DTC_CSM_LEAK_UNKNOWN" 16523008 "DTC_CSM_VER_MISMATCH" 16523009 "DTC_CSM_DTC_SET" 16523010 "DTC_CSM_CAL_FAULT" 16560128 "DTC_IBAT_MISMATCH" 16576512 "DTC_DIS_MAX_I2T" 16576513 "DTC_CHG_MAX_I2T" 16576768 "DTC_DIS_WARNING_I2T" 16576769 "DTC_CHG_WARNING_I2T" 11296784 "DTC_SAEJ1772_PROX_DECT_OOR_HI" 11296785 "DTC_SAEJ1772_PROX_DECT_OOR_LO" 11296800 "DTC_SAEJ1772_PILOT_PWM_OOR_HI" 11296801 "DTC_SAEJ1772_PILOT_PWM_OOR_LO" 11296802 "DTC_SAEJ1772_PILOT_PWM_DIG_COMM" 11296803 "DTC_SAEJ1772_PILOT_PWM_IR_ERR" 16175360 "DTC_FGD1_NO_SENSOR" 16175361 "DTC_FGD1_OOR_HI" 16175362 "DTC_FGD1_OOR_LO" 16175363 "DTC_FGD1_FAULT" 16175616 "DTC_FGD2_NO_SENSOR" 16175617 "DTC_FGD2_OOR_HI" 16175618 "DTC_FGD2_OOR_LO" 16175619 "DTC_FGD2_FAULT" 16171008 "DTC_CONT_OPEN" 16171009 "DTC_CONT_CLOSE" 16171010 "DTC_CONT_OPEN_CURRENT" 16171264 "DTC_CONT_CLOSE_ON_RESET" 16171265 "DTC_CONT_CLOSE_SIG_FAILED" 16171520 "DTC_PRECHARGE_TIMEOUT" 16171777 "DTC_CONT_MPOS_WELD_AT_SU" 16171778 "DTC_CONT_MNEG_WELD_AT_SU" 16171780 "DTC_CONT_CPOS_WELD_AT_SU" 16171781 "DTC_CONT_CNEG_WELD_AT_SU" 16171782 "DTC_CONT_ANEG_WELD_AT_SU" 16171783 "DTC_CONT_APOS_WELD_AT_SU" 16172033 "DTC_CONT_MPOS_WELD_AT_SD" 16172034 "DTC_CONT_MNEG_WELD_AT_SD" 16172036 "DTC_CONT_CPOS_WELD_AT_SD" 16172037 "DTC_CONT_CNEG_WELD_AT_SD" 16172038 "DTC_CONT_ANEG_WELD_AT_SD" 16172039 "DTC_CONT_APOS_WELD_AT_SD" 16172289 "DTC_CONT_MPOS_OPEN" 16172290 "DTC_CONT_MNEG_OPEN" 16172291 "DTC_CONT_MPRE_OPEN" 16172292 "DTC_CONT_CPOS_OPEN" 16172293 "DTC_CONT_CNEG_OPEN" 16172294 "DTC_CONT_APOS_OPEN" 16172295 "DTC_CONT_ANEG_OPEN" 16172545 "DTC_CONT_MPOS_VDIF" 16172546 "DTC_CONT_MNEG_VDIF" 16172548 "DTC_CONT_CPOS_VDIF" 16172549 "DTC_CONT_CNEG_VDIF" 16172550 "DTC_CONT_APOS_VDIF" 16172551 "DTC_CONT_ANEG_VDIF" 16174848 "DTC_HVIL" 16174849 "DTC_LVBAT_LO" 16174850 "DTC_LVBAT_HI" 16174851 "DTC_LVBAT_ERR" 16523520 "DTC_LEMLO_OOR_HI" 16523521 "DTC_LEMLO_OOR_LO" 16523522 "DTC_LEMLO_FAULT" 16523776 "DTC_LEMHI_OOR_HI" 16523777 "DTC_LEMHI_OOR_LO" 16523778 "DTC_LEMHI_FAULT" 16496320 "DTC_MBB_TOO_FEW" 16496321 "DTC_MBB_TOO_MANY" 16496352 "DTC_CELL_VMAX_ERR" 16496353 "DTC_CELL_VMIN_ERR" 16496354 "DTC_CELL_VMAX" 16496362 "DTC_CELL_VMAX_SEVERE" 16496355 "DTC_CELL_VMIN" 16496363 "DTC_CELL_VMIN_SEVERE" 16496356 "DTC_MOD_VOLTAGE_COMPARE" 16496336 "DTC_CELL_T_ERR" 16496337 "DTC_CELL_TMAX1" 16496338 "DTC_CELL_TMAX2" 16496339 "DTC_CELL_TMIN" 16497665 "DTC_MBB_01_MISSING" 16497666 "DTC_MBB_02_MISSING" 16497667 "DTC_MBB_03_MISSING" 16497668 "DTC_MBB_04_MISSING" 16497669 "DTC_MBB_05_MISSING" 16497670 "DTC_MBB_06_MISSING" 16497671 "DTC_MBB_07_MISSING" 16497672 "DTC_MBB_08_MISSING" 16497673 "DTC_MBB_09_MISSING" 16497680 "DTC_MBB_10_MISSING" 16497681 "DTC_MBB_11_MISSING" 16497682 "DTC_MBB_12_MISSING" 16497683 "DTC_MBB_13_MISSING" 16497684 "DTC_MBB_14_MISSING" 16497685 "DTC_MBB_15_MISSING" 16497686 "DTC_MBB_16_MISSING" 16497687 "DTC_MBB_17_MISSING" 16497688 "DTC_MBB_18_MISSING" 16497689 "DTC_MBB_19_MISSING" 16497696 "DTC_MBB_20_MISSING" 16497697 "DTC_MBB_21_MISSING" 16497698 "DTC_MBB_22_MISSING" 16497699 "DTC_MBB_23_MISSING" 16497700 "DTC_MBB_24_MISSING" 16498177 "DTC_MBB_01_VFAULT" 16498178 "DTC_MBB_02_VFAULT" 16498179 "DTC_MBB_03_VFAULT" 16498180 "DTC_MBB_04_VFAULT" 16498181 "DTC_MBB_05_VFAULT" 16498182 "DTC_MBB_06_VFAULT" 16498183 "DTC_MBB_07_VFAULT" 16498184 "DTC_MBB_08_VFAULT" 16498185 "DTC_MBB_09_VFAULT" 16498192 "DTC_MBB_10_VFAULT" 16498193 "DTC_MBB_11_VFAULT" 16498194 "DTC_MBB_12_VFAULT" 16498195 "DTC_MBB_13_VFAULT" 16498196 "DTC_MBB_14_VFAULT" 16498197 "DTC_MBB_15_VFAULT" 16498198 "DTC_MBB_16_VFAULT" 16498199 "DTC_MBB_17_VFAULT" 16498200 "DTC_MBB_18_VFAULT" 16498201 "DTC_MBB_19_VFAULT" 16498208 "DTC_MBB_20_VFAULT" 16498209 "DTC_MBB_21_VFAULT" 16498210 "DTC_MBB_22_VFAULT" 16498211 "DTC_MBB_23_VFAULT" 16498212 "DTC_MBB_24_VFAULT" 16497921 "DTC_MBB_01_TFAULT" 16497922 "DTC_MBB_02_TFAULT" 16497923 "DTC_MBB_03_TFAULT" 16497924 "DTC_MBB_04_TFAULT" 16497925 "DTC_MBB_05_TFAULT" 16497926 "DTC_MBB_06_TFAULT" 16497927 "DTC_MBB_07_TFAULT" 16497928 "DTC_MBB_08_TFAULT" 16497929 "DTC_MBB_09_TFAULT" 16497936 "DTC_MBB_10_TFAULT" 16497937 "DTC_MBB_11_TFAULT" 16497938 "DTC_MBB_12_TFAULT" 16497939 "DTC_MBB_13_TFAULT" 16497940 "DTC_MBB_14_TFAULT" 16497941 "DTC_MBB_15_TFAULT" 16497942 "DTC_MBB_16_TFAULT" 16497943 "DTC_MBB_17_TFAULT" 16497944 "DTC_MBB_18_TFAULT" 16497945 "DTC_MBB_19_TFAULT" 16497952 "DTC_MBB_20_TFAULT" 16497953 "DTC_MBB_21_TFAULT" 16497954 "DTC_MBB_22_TFAULT" 16497955 "DTC_MBB_23_TFAULT" 16497956 "DTC_MBB_24_TFAULT" 15785984 "DTC_PRECHARGE_ENERGY" 15785985 "DTC_PRT_FAILED" 15785986 "DTC_PRT_OVERTEMP" 15785987 "DTC_PRT_PROHIBIT" 16556032 "DTC_COOLANT_TEMP_OOR_HI" 16556033 "DTC_COOLANT_TEMP_OOR_LO" 16252928 "DTC_KEY_OFF_TIME_ERROR" 16506880 "DTC_VBAT_MISMATCH" 16506881 "DTC_VBAT_VMAX" 16506882 "DTC_VBAT_VMIN" 16506883 "DTC_PACK_FUSE" 15798544 "DTC_LLS1_OOR_HI" 15798545 "DTC_LLS1_OOR_LO" 15798546 "DTC_LLS1_FAULT" 15798816 "DTC_LLS2_OOR_HI" 15798817 "DTC_LLS2_OOR_LO" 15798818 "DTC_LLS2_FAULT" 14479360 "DTC_CFL_HEARTBEAT" 14479361 "DTC_CFL_FAULT" 14479362 "DTC_CFL_FAULT_LATCH" 13635584 "DTC_CONT_A_FAILED_HI" 13635585 "DTC_CONT_A_FAILED_LO" 13635586 "DTC_CONT_B_FAILED_HI" 13635587 "DTC_CONT_B_FAILED_LO" 13635588 "DTC_CONT_C_FAILED_HI" 13635589 "DTC_CONT_C_FAILED_LO" 13635590 "DTC_CONT_D_FAILED_HI" 13635591 "DTC_CONT_D_FAILED_LO" 13635592 "DTC_CONT_E_FAILED_HI" 13635593 "DTC_CONT_E_FAILED_LO" 13635594 "DTC_CONT_F_FAILED_HI" 13635595 "DTC_CONT_F_FAILED_LO" 13635596 "DTC_CONT_G_FAILED_HI" 13635597 "DTC_CONT_G_FAILED_LO" 13635598 "DTC_LSD_A_FAILED_HI" 13635599 "DTC_LSD_A_FAILED_LO" 13635600 "DTC_LSD_B_FAILED_HI" 13635601 "DTC_LSD_B_FAILED_LO" 13635602 "DTC_LSD_C_FAILED_HI" 13635603 "DTC_LSD_C_FAILED_LO" 13635606 "DTC_CONT_PWR_FAILED_HI" 13635607 "DTC_CONT_PWR_FAILED_LO" 13635608 "DTC_LSD_PUMP_FAILED_HI" 13635609 "DTC_LSD_PUMP_FAILED_LO" 13635610 "DTC_CHG_A_ENABLE_FAILED_HI" 13635611 "DTC_CHG_A_ENABLE_FAILED_LO" 13635612 "DTC_CHG_B_ENABLE_FAILED_HI" 13635613 "DTC_CHG_B_ENABLE_FAILED_LO" 13635614 "DTC_SW14V_PWR_FAILED_HI" 13635615 "DTC_SW14V_PWR_FAILED_LO" 13635620 "DTC_HSD_A_FAILED_HI" 13635621 "DTC_HSD_A_FAILED_LO" 13635622 "DTC_HSD_B_FAILED_HI" 13635623 "DTC_HSD_B_FAILED_LO" 13692968 "DTC_CONT_HPWR_FAILED_HI" 13692969 "DTC_CONT_HPWR_FAILED_LO" 13692970 "DTC_CONT_HPWR_OOR_HI" 13692971 "DTC_CONT_HPWR_OOR_LO" 13635616 "DTC_5V_PWR_OOR_HI" 13635617 "DTC_5V_PWR_OOR_LO" 14606336 "DTC_NVM_WRITE_TO" 14606337 "DTC_NVM_READ_TO" 14614528 "DTC_SPI_DIG_POT_FAULT" ;
VAL_ 1120 bcm_dtc_082 0 " - " 11276288 "DTC_VEPO" 11276289 "DTC_HSC_MISSING" 11460608 "DTC_NVM_SOC" 11460609 "DTC_NVM_KOT" 11460610 "DTC_NVM_DTC" 11460611 "DTC_NVM_SOC_CORRECTION" 11460612 "DTC_NVM_APP_SCRATCHPAD" 11517962 "DTC_LOOPTIME_TASK_A" 11517963 "DTC_LOOPTIME_TASK_B" 11517964 "DTC_LOOPTIME_TASK_C" 11517965 "DTC_LOOPTIME_TASK_D" 11517966 "DTC_LOOPTIME_TASK_E" 11517967 "DTC_LOOPTIME_TASK_F" 11323904 "DTC_INTERLOCK_A_FAILED_LOW" 11323905 "DTC_INTERLOCK_A_FAILED_HIGH" 11324160 "DTC_INTERLOCK_B_FAILED_LOW" 11324161 "DTC_INTERLOCK_B_FAILED_HIGH" 15728640 "DTC_EPO" 16498688 "DTC_BRUSA_MISSING" 16498689 "DTC_BRUSA_IDC" 16498690 "DTC_BRUSA_REQ_VS_CMD" 16433152 "DTC_AKERWADE_MISSING" 16433153 "DTC_AKERWADE_IDC" 16433154 "DTC_AKERWADE_REQ_VS_CMD" 16564224 "DTC_CHGLEAR_MISSING" 16564225 "DTC_CHGLEAR_IDC" 16564226 "DTC_CHGLEAR_REQ_VS_CMD" 16522240 "DTC_CSM_MISSING" 16522752 "DTC_CSM_VBAT" 16522753 "DTC_CSM_VPOS" 16522754 "DTC_CSM_VNEG" 16522755 "DTC_CSM_CPOS" 16522756 "DTC_CSM_CNEG" 16522757 "DTC_CSM_APOS" 16522758 "DTC_CSM_ANEG" 16522759 "DTC_CSM_FUSE_HI" 16522760 "DTC_CSM_FUSE_LO" 16521728 "DTC_CSM_ASIC" 16521729 "DTC_CSM_AILO" 16521730 "DTC_CSM_AIHI" 16520957 "DTC_LEAKAGE_DETECT_FAULT" 16522444 "DTC_REALTIMECLOCK_FAULT" 16520945 "DTC_CSM_LEAK_FAIL_CALC" 16520946 "DTC_CSM_LEAK_FAIL_HW" 16520947 "DTC_CSM_LEAK_EXT_SHORT" 16520948 "DTC_CSM_LEAK_MID_PACK_SHORT" 16520949 "DTC_CSM_LEAK_ERROR" 16520950 "DTC_CSM_LEAK_UNKNOWN" 16523008 "DTC_CSM_VER_MISMATCH" 16523009 "DTC_CSM_DTC_SET" 16523010 "DTC_CSM_CAL_FAULT" 16560128 "DTC_IBAT_MISMATCH" 16576512 "DTC_DIS_MAX_I2T" 16576513 "DTC_CHG_MAX_I2T" 16576768 "DTC_DIS_WARNING_I2T" 16576769 "DTC_CHG_WARNING_I2T" 11296784 "DTC_SAEJ1772_PROX_DECT_OOR_HI" 11296785 "DTC_SAEJ1772_PROX_DECT_OOR_LO" 11296800 "DTC_SAEJ1772_PILOT_PWM_OOR_HI" 11296801 "DTC_SAEJ1772_PILOT_PWM_OOR_LO" 11296802 "DTC_SAEJ1772_PILOT_PWM_DIG_COMM" 11296803 "DTC_SAEJ1772_PILOT_PWM_IR_ERR" 16175360 "DTC_FGD1_NO_SENSOR" 16175361 "DTC_FGD1_OOR_HI" 16175362 "DTC_FGD1_OOR_LO" 16175363 "DTC_FGD1_FAULT" 16175616 "DTC_FGD2_NO_SENSOR" 16175617 "DTC_FGD2_OOR_HI" 16175618 "DTC_FGD2_OOR_LO" 16175619 "DTC_FGD2_FAULT" 16171008 "DTC_CONT_OPEN" 16171009 "DTC_CONT_CLOSE" 16171010 "DTC_CONT_OPEN_CURRENT" 16171264 "DTC_CONT_CLOSE_ON_RESET" 16171265 "DTC_CONT_CLOSE_SIG_FAILED" 16171520 "DTC_PRECHARGE_TIMEOUT" 16171777 "DTC_CONT_MPOS_WELD_AT_SU" 16171778 "DTC_CONT_MNEG_WELD_AT_SU" 16171780 "DTC_CONT_CPOS_WELD_AT_SU" 16171781 "DTC_CONT_CNEG_WELD_AT_SU" 16171782 "DTC_CONT_ANEG_WELD_AT_SU" 16171783 "DTC_CONT_APOS_WELD_AT_SU" 16172033 "DTC_CONT_MPOS_WELD_AT_SD" 16172034 "DTC_CONT_MNEG_WELD_AT_SD" 16172036 "DTC_CONT_CPOS_WELD_AT_SD" 16172037 "DTC_CONT_CNEG_WELD_AT_SD" 16172038 "DTC_CONT_ANEG_WELD_AT_SD" 16172039 "DTC_CONT_APOS_WELD_AT_SD" 16172289 "DTC_CONT_MPOS_OPEN" 16172290 "DTC_CONT_MNEG_OPEN" 16172291 "DTC_CONT_MPRE_OPEN" 16172292 "DTC_CONT_CPOS_OPEN" 16172293 "DTC_CONT_CNEG_OPEN" 16172294 "DTC_CONT_APOS_OPEN" 16172295 "DTC_CONT_ANEG_OPEN" 16172545 "DTC_CONT_MPOS_VDIF" 16172546 "DTC_CONT_MNEG_VDIF" 16172548 "DTC_CONT_CPOS_VDIF" 16172549 "DTC_CONT_CNEG_VDIF" 16172550 "DTC_CONT_APOS_VDIF" 16172551 "DTC_CONT_ANEG_VDIF" 16174848 "DTC_HVIL" 16174849 "DTC_LVBAT_LO" 16174850 "DTC_LVBAT_HI" 16174851 "DTC_LVBAT_ERR" 16523520 "DTC_LEMLO_OOR_HI" 16523521 "DTC_LEMLO_OOR_LO" 16523522 "DTC_LEMLO_FAULT" 16523776 "DTC_LEMHI_OOR_HI" 16523777 "DTC_LEMHI_OOR_LO" 16523778 "DTC_LEMHI_FAULT" 16496320 "DTC_MBB_TOO_FEW" 16496321 "DTC_MBB_TOO_MANY" 16496352 "DTC_CELL_VMAX_ERR" 16496353 "DTC_CELL_VMIN_ERR" 16496354 "DTC_CELL_VMAX" 16496362 "DTC_CELL_VMAX_SEVERE" 16496355 "DTC_CELL_VMIN" 16496363 "DTC_CELL_VMIN_SEVERE" 16496356 "DTC_MOD_VOLTAGE_COMPARE" 16496336 "DTC_CELL_T_ERR" 16496337 "DTC_CELL_TMAX1" 16496338 "DTC_CELL_TMAX2" 16496339 "DTC_CELL_TMIN" 16497665 "DTC_MBB_01_MISSING" 16497666 "DTC_MBB_02_MISSING" 16497667 "DTC_MBB_03_MISSING" 16497668 "DTC_MBB_04_MISSING" 16497669 "DTC_MBB_05_MISSING" 16497670 "DTC_MBB_06_MISSING" 16497671 "DTC_MBB_07_MISSING" 16497672 "DTC_MBB_08_MISSING" 16497673 "DTC_MBB_09_MISSING" 16497680 "DTC_MBB_10_MISSING" 16497681 "DTC_MBB_11_MISSING" 16497682 "DTC_MBB_12_MISSING" 16497683 "DTC_MBB_13_MISSING" 16497684 "DTC_MBB_14_MISSING" 16497685 "DTC_MBB_15_MISSING" 16497686 "DTC_MBB_16_MISSING" 16497687 "DTC_MBB_17_MISSING" 16497688 "DTC_MBB_18_MISSING" 16497689 "DTC_MBB_19_MISSING" 16497696 "DTC_MBB_20_MISSING" 16497697 "DTC_MBB_21_MISSING" 16497698 "DTC_MBB_22_MISSING" 16497699 "DTC_MBB_23_MISSING" 16497700 "DTC_MBB_24_MISSING" 16498177 "DTC_MBB_01_VFAULT" 16498178 "DTC_MBB_02_VFAULT" 16498179 "DTC_MBB_03_VFAULT" 16498180 "DTC_MBB_04_VFAULT" 16498181 "DTC_MBB_05_VFAULT" 16498182 "DTC_MBB_06_VFAULT" 16498183 "DTC_MBB_07_VFAULT" 16498184 "DTC_MBB_08_VFAULT" 16498185 "DTC_MBB_09_VFAULT" 16498192 "DTC_MBB_10_VFAULT" 16498193 "DTC_MBB_11_VFAULT" 16498194 "DTC_MBB_12_VFAULT" 16498195 "DTC_MBB_13_VFAULT" 16498196 "DTC_MBB_14_VFAULT" 16498197 "DTC_MBB_15_VFAULT" 16498198 "DTC_MBB_16_VFAULT" 16498199 "DTC_MBB_17_VFAULT" 16498200 "DTC_MBB_18_VFAULT" 16498201 "DTC_MBB_19_VFAULT" 16498208 "DTC_MBB_20_VFAULT" 16498209 "DTC_MBB_21_VFAULT" 16498210 "DTC_MBB_22_VFAULT" 16498211 "DTC_MBB_23_VFAULT" 16498212 "DTC_MBB_24_VFAULT" 16497921 "DTC_MBB_01_TFAULT" 16497922 "DTC_MBB_02_TFAULT" 16497923 "DTC_MBB_03_TFAULT" 16497924 "DTC_MBB_04_TFAULT" 16497925 "DTC_MBB_05_TFAULT" 16497926 "DTC_MBB_06_TFAULT" 16497927 "DTC_MBB_07_TFAULT" 16497928 "DTC_MBB_08_TFAULT" 16497929 "DTC_MBB_09_TFAULT" 16497936 "DTC_MBB_10_TFAULT" 16497937 "DTC_MBB_11_TFAULT" 16497938 "DTC_MBB_12_TFAULT" 16497939 "DTC_MBB_13_TFAULT" 16497940 "DTC_MBB_14_TFAULT" 16497941 "DTC_MBB_15_TFAULT" 16497942 "DTC_MBB_16_TFAULT" 16497943 "DTC_MBB_17_TFAULT" 16497944 "DTC_MBB_18_TFAULT" 16497945 "DTC_MBB_19_TFAULT" 16497952 "DTC_MBB_20_TFAULT" 16497953 "DTC_MBB_21_TFAULT" 16497954 "DTC_MBB_22_TFAULT" 16497955 "DTC_MBB_23_TFAULT" 16497956 "DTC_MBB_24_TFAULT" 15785984 "DTC_PRECHARGE_ENERGY" 15785985 "DTC_PRT_FAILED" 15785986 "DTC_PRT_OVERTEMP" 15785987 "DTC_PRT_PROHIBIT" 16556032 "DTC_COOLANT_TEMP_OOR_HI" 16556033 "DTC_COOLANT_TEMP_OOR_LO" 16252928 "DTC_KEY_OFF_TIME_ERROR" 16506880 "DTC_VBAT_MISMATCH" 16506881 "DTC_VBAT_VMAX" 16506882 "DTC_VBAT_VMIN" 16506883 "DTC_PACK_FUSE" 15798544 "DTC_LLS1_OOR_HI" 15798545 "DTC_LLS1_OOR_LO" 15798546 "DTC_LLS1_FAULT" 15798816 "DTC_LLS2_OOR_HI" 15798817 "DTC_LLS2_OOR_LO" 15798818 "DTC_LLS2_FAULT" 14479360 "DTC_CFL_HEARTBEAT" 14479361 "DTC_CFL_FAULT" 14479362 "DTC_CFL_FAULT_LATCH" 13635584 "DTC_CONT_A_FAILED_HI" 13635585 "DTC_CONT_A_FAILED_LO" 13635586 "DTC_CONT_B_FAILED_HI" 13635587 "DTC_CONT_B_FAILED_LO" 13635588 "DTC_CONT_C_FAILED_HI" 13635589 "DTC_CONT_C_FAILED_LO" 13635590 "DTC_CONT_D_FAILED_HI" 13635591 "DTC_CONT_D_FAILED_LO" 13635592 "DTC_CONT_E_FAILED_HI" 13635593 "DTC_CONT_E_FAILED_LO" 13635594 "DTC_CONT_F_FAILED_HI" 13635595 "DTC_CONT_F_FAILED_LO" 13635596 "DTC_CONT_G_FAILED_HI" 13635597 "DTC_CONT_G_FAILED_LO" 13635598 "DTC_LSD_A_FAILED_HI" 13635599 "DTC_LSD_A_FAILED_LO" 13635600 "DTC_LSD_B_FAILED_HI" 13635601 "DTC_LSD_B_FAILED_LO" 13635602 "DTC_LSD_C_FAILED_HI" 13635603 "DTC_LSD_C_FAILED_LO" 13635606 "DTC_CONT_PWR_FAILED_HI" 13635607 "DTC_CONT_PWR_FAILED_LO" 13635608 "DTC_LSD_PUMP_FAILED_HI" 13635609 "DTC_LSD_PUMP_FAILED_LO" 13635610 "DTC_CHG_A_ENABLE_FAILED_HI" 13635611 "DTC_CHG_A_ENABLE_FAILED_LO" 13635612 "DTC_CHG_B_ENABLE_FAILED_HI" 13635613 "DTC_CHG_B_ENABLE_FAILED_LO" 13635614 "DTC_SW14V_PWR_FAILED_HI" 13635615 "DTC_SW14V_PWR_FAILED_LO" 13635620 "DTC_HSD_A_FAILED_HI" 13635621 "DTC_HSD_A_FAILED_LO" 13635622 "DTC_HSD_B_FAILED_HI" 13635623 "DTC_HSD_B_FAILED_LO" 13692968 "DTC_CONT_HPWR_FAILED_HI" 13692969 "DTC_CONT_HPWR_FAILED_LO" 13692970 "DTC_CONT_HPWR_OOR_HI" 13692971 "DTC_CONT_HPWR_OOR_LO" 13635616 "DTC_5V_PWR_OOR_HI" 13635617 "DTC_5V_PWR_OOR_LO" 14606336 "DTC_NVM_WRITE_TO" 14606337 "DTC_NVM_READ_TO" 14614528 "DTC_SPI_DIG_POT_FAULT" ;
VAL_ 1120 bcm_dtc_083 0 " - " 11276288 "DTC_VEPO" 11276289 "DTC_HSC_MISSING" 11460608 "DTC_NVM_SOC" 11460609 "DTC_NVM_KOT" 11460610 "DTC_NVM_DTC" 11460611 "DTC_NVM_SOC_CORRECTION" 11460612 "DTC_NVM_APP_SCRATCHPAD" 11517962 "DTC_LOOPTIME_TASK_A" 11517963 "DTC_LOOPTIME_TASK_B" 11517964 "DTC_LOOPTIME_TASK_C" 11517965 "DTC_LOOPTIME_TASK_D" 11517966 "DTC_LOOPTIME_TASK_E" 11517967 "DTC_LOOPTIME_TASK_F" 11323904 "DTC_INTERLOCK_A_FAILED_LOW" 11323905 "DTC_INTERLOCK_A_FAILED_HIGH" 11324160 "DTC_INTERLOCK_B_FAILED_LOW" 11324161 "DTC_INTERLOCK_B_FAILED_HIGH" 15728640 "DTC_EPO" 16498688 "DTC_BRUSA_MISSING" 16498689 "DTC_BRUSA_IDC" 16498690 "DTC_BRUSA_REQ_VS_CMD" 16433152 "DTC_AKERWADE_MISSING" 16433153 "DTC_AKERWADE_IDC" 16433154 "DTC_AKERWADE_REQ_VS_CMD" 16564224 "DTC_CHGLEAR_MISSING" 16564225 "DTC_CHGLEAR_IDC" 16564226 "DTC_CHGLEAR_REQ_VS_CMD" 16522240 "DTC_CSM_MISSING" 16522752 "DTC_CSM_VBAT" 16522753 "DTC_CSM_VPOS" 16522754 "DTC_CSM_VNEG" 16522755 "DTC_CSM_CPOS" 16522756 "DTC_CSM_CNEG" 16522757 "DTC_CSM_APOS" 16522758 "DTC_CSM_ANEG" 16522759 "DTC_CSM_FUSE_HI" 16522760 "DTC_CSM_FUSE_LO" 16521728 "DTC_CSM_ASIC" 16521729 "DTC_CSM_AILO" 16521730 "DTC_CSM_AIHI" 16520957 "DTC_LEAKAGE_DETECT_FAULT" 16522444 "DTC_REALTIMECLOCK_FAULT" 16520945 "DTC_CSM_LEAK_FAIL_CALC" 16520946 "DTC_CSM_LEAK_FAIL_HW" 16520947 "DTC_CSM_LEAK_EXT_SHORT" 16520948 "DTC_CSM_LEAK_MID_PACK_SHORT" 16520949 "DTC_CSM_LEAK_ERROR" 16520950 "DTC_CSM_LEAK_UNKNOWN" 16523008 "DTC_CSM_VER_MISMATCH" 16523009 "DTC_CSM_DTC_SET" 16523010 "DTC_CSM_CAL_FAULT" 16560128 "DTC_IBAT_MISMATCH" 16576512 "DTC_DIS_MAX_I2T" 16576513 "DTC_CHG_MAX_I2T" 16576768 "DTC_DIS_WARNING_I2T" 16576769 "DTC_CHG_WARNING_I2T" 11296784 "DTC_SAEJ1772_PROX_DECT_OOR_HI" 11296785 "DTC_SAEJ1772_PROX_DECT_OOR_LO" 11296800 "DTC_SAEJ1772_PILOT_PWM_OOR_HI" 11296801 "DTC_SAEJ1772_PILOT_PWM_OOR_LO" 11296802 "DTC_SAEJ1772_PILOT_PWM_DIG_COMM" 11296803 "DTC_SAEJ1772_PILOT_PWM_IR_ERR" 16175360 "DTC_FGD1_NO_SENSOR" 16175361 "DTC_FGD1_OOR_HI" 16175362 "DTC_FGD1_OOR_LO" 16175363 "DTC_FGD1_FAULT" 16175616 "DTC_FGD2_NO_SENSOR" 16175617 "DTC_FGD2_OOR_HI" 16175618 "DTC_FGD2_OOR_LO" 16175619 "DTC_FGD2_FAULT" 16171008 "DTC_CONT_OPEN" 16171009 "DTC_CONT_CLOSE" 16171010 "DTC_CONT_OPEN_CURRENT" 16171264 "DTC_CONT_CLOSE_ON_RESET" 16171265 "DTC_CONT_CLOSE_SIG_FAILED" 16171520 "DTC_PRECHARGE_TIMEOUT" 16171777 "DTC_CONT_MPOS_WELD_AT_SU" 16171778 "DTC_CONT_MNEG_WELD_AT_SU" 16171780 "DTC_CONT_CPOS_WELD_AT_SU" 16171781 "DTC_CONT_CNEG_WELD_AT_SU" 16171782 "DTC_CONT_ANEG_WELD_AT_SU" 16171783 "DTC_CONT_APOS_WELD_AT_SU" 16172033 "DTC_CONT_MPOS_WELD_AT_SD" 16172034 "DTC_CONT_MNEG_WELD_AT_SD" 16172036 "DTC_CONT_CPOS_WELD_AT_SD" 16172037 "DTC_CONT_CNEG_WELD_AT_SD" 16172038 "DTC_CONT_ANEG_WELD_AT_SD" 16172039 "DTC_CONT_APOS_WELD_AT_SD" 16172289 "DTC_CONT_MPOS_OPEN" 16172290 "DTC_CONT_MNEG_OPEN" 16172291 "DTC_CONT_MPRE_OPEN" 16172292 "DTC_CONT_CPOS_OPEN" 16172293 "DTC_CONT_CNEG_OPEN" 16172294 "DTC_CONT_APOS_OPEN" 16172295 "DTC_CONT_ANEG_OPEN" 16172545 "DTC_CONT_MPOS_VDIF" 16172546 "DTC_CONT_MNEG_VDIF" 16172548 "DTC_CONT_CPOS_VDIF" 16172549 "DTC_CONT_CNEG_VDIF" 16172550 "DTC_CONT_APOS_VDIF" 16172551 "DTC_CONT_ANEG_VDIF" 16174848 "DTC_HVIL" 16174849 "DTC_LVBAT_LO" 16174850 "DTC_LVBAT_HI" 16174851 "DTC_LVBAT_ERR" 16523520 "DTC_LEMLO_OOR_HI" 16523521 "DTC_LEMLO_OOR_LO" 16523522 "DTC_LEMLO_FAULT" 16523776 "DTC_LEMHI_OOR_HI" 16523777 "DTC_LEMHI_OOR_LO" 16523778 "DTC_LEMHI_FAULT" 16496320 "DTC_MBB_TOO_FEW" 16496321 "DTC_MBB_TOO_MANY" 16496352 "DTC_CELL_VMAX_ERR" 16496353 "DTC_CELL_VMIN_ERR" 16496354 "DTC_CELL_VMAX" 16496362 "DTC_CELL_VMAX_SEVERE" 16496355 "DTC_CELL_VMIN" 16496363 "DTC_CELL_VMIN_SEVERE" 16496356 "DTC_MOD_VOLTAGE_COMPARE" 16496336 "DTC_CELL_T_ERR" 16496337 "DTC_CELL_TMAX1" 16496338 "DTC_CELL_TMAX2" 16496339 "DTC_CELL_TMIN" 16497665 "DTC_MBB_01_MISSING" 16497666 "DTC_MBB_02_MISSING" 16497667 "DTC_MBB_03_MISSING" 16497668 "DTC_MBB_04_MISSING" 16497669 "DTC_MBB_05_MISSING" 16497670 "DTC_MBB_06_MISSING" 16497671 "DTC_MBB_07_MISSING" 16497672 "DTC_MBB_08_MISSING" 16497673 "DTC_MBB_09_MISSING" 16497680 "DTC_MBB_10_MISSING" 16497681 "DTC_MBB_11_MISSING" 16497682 "DTC_MBB_12_MISSING" 16497683 "DTC_MBB_13_MISSING" 16497684 "DTC_MBB_14_MISSING" 16497685 "DTC_MBB_15_MISSING" 16497686 "DTC_MBB_16_MISSING" 16497687 "DTC_MBB_17_MISSING" 16497688 "DTC_MBB_18_MISSING" 16497689 "DTC_MBB_19_MISSING" 16497696 "DTC_MBB_20_MISSING" 16497697 "DTC_MBB_21_MISSING" 16497698 "DTC_MBB_22_MISSING" 16497699 "DTC_MBB_23_MISSING" 16497700 "DTC_MBB_24_MISSING" 16498177 "DTC_MBB_01_VFAULT" 16498178 "DTC_MBB_02_VFAULT" 16498179 "DTC_MBB_03_VFAULT" 16498180 "DTC_MBB_04_VFAULT" 16498181 "DTC_MBB_05_VFAULT" 16498182 "DTC_MBB_06_VFAULT" 16498183 "DTC_MBB_07_VFAULT" 16498184 "DTC_MBB_08_VFAULT" 16498185 "DTC_MBB_09_VFAULT" 16498192 "DTC_MBB_10_VFAULT" 16498193 "DTC_MBB_11_VFAULT" 16498194 "DTC_MBB_12_VFAULT" 16498195 "DTC_MBB_13_VFAULT" 16498196 "DTC_MBB_14_VFAULT" 16498197 "DTC_MBB_15_VFAULT" 16498198 "DTC_MBB_16_VFAULT" 16498199 "DTC_MBB_17_VFAULT" 16498200 "DTC_MBB_18_VFAULT" 16498201 "DTC_MBB_19_VFAULT" 16498208 "DTC_MBB_20_VFAULT" 16498209 "DTC_MBB_21_VFAULT" 16498210 "DTC_MBB_22_VFAULT" 16498211 "DTC_MBB_23_VFAULT" 16498212 "DTC_MBB_24_VFAULT" 16497921 "DTC_MBB_01_TFAULT" 16497922 "DTC_MBB_02_TFAULT" 16497923 "DTC_MBB_03_TFAULT" 16497924 "DTC_MBB_04_TFAULT" 16497925 "DTC_MBB_05_TFAULT" 16497926 "DTC_MBB_06_TFAULT" 16497927 "DTC_MBB_07_TFAULT" 16497928 "DTC_MBB_08_TFAULT" 16497929 "DTC_MBB_09_TFAULT" 16497936 "DTC_MBB_10_TFAULT" 16497937 "DTC_MBB_11_TFAULT" 16497938 "DTC_MBB_12_TFAULT" 16497939 "DTC_MBB_13_TFAULT" 16497940 "DTC_MBB_14_TFAULT" 16497941 "DTC_MBB_15_TFAULT" 16497942 "DTC_MBB_16_TFAULT" 16497943 "DTC_MBB_17_TFAULT" 16497944 "DTC_MBB_18_TFAULT" 16497945 "DTC_MBB_19_TFAULT" 16497952 "DTC_MBB_20_TFAULT" 16497953 "DTC_MBB_21_TFAULT" 16497954 "DTC_MBB_22_TFAULT" 16497955 "DTC_MBB_23_TFAULT" 16497956 "DTC_MBB_24_TFAULT" 15785984 "DTC_PRECHARGE_ENERGY" 15785985 "DTC_PRT_FAILED" 15785986 "DTC_PRT_OVERTEMP" 15785987 "DTC_PRT_PROHIBIT" 16556032 "DTC_COOLANT_TEMP_OOR_HI" 16556033 "DTC_COOLANT_TEMP_OOR_LO" 16252928 "DTC_KEY_OFF_TIME_ERROR" 16506880 "DTC_VBAT_MISMATCH" 16506881 "DTC_VBAT_VMAX" 16506882 "DTC_VBAT_VMIN" 16506883 "DTC_PACK_FUSE" 15798544 "DTC_LLS1_OOR_HI" 15798545 "DTC_LLS1_OOR_LO" 15798546 "DTC_LLS1_FAULT" 15798816 "DTC_LLS2_OOR_HI" 15798817 "DTC_LLS2_OOR_LO" 15798818 "DTC_LLS2_FAULT" 14479360 "DTC_CFL_HEARTBEAT" 14479361 "DTC_CFL_FAULT" 14479362 "DTC_CFL_FAULT_LATCH" 13635584 "DTC_CONT_A_FAILED_HI" 13635585 "DTC_CONT_A_FAILED_LO" 13635586 "DTC_CONT_B_FAILED_HI" 13635587 "DTC_CONT_B_FAILED_LO" 13635588 "DTC_CONT_C_FAILED_HI" 13635589 "DTC_CONT_C_FAILED_LO" 13635590 "DTC_CONT_D_FAILED_HI" 13635591 "DTC_CONT_D_FAILED_LO" 13635592 "DTC_CONT_E_FAILED_HI" 13635593 "DTC_CONT_E_FAILED_LO" 13635594 "DTC_CONT_F_FAILED_HI" 13635595 "DTC_CONT_F_FAILED_LO" 13635596 "DTC_CONT_G_FAILED_HI" 13635597 "DTC_CONT_G_FAILED_LO" 13635598 "DTC_LSD_A_FAILED_HI" 13635599 "DTC_LSD_A_FAILED_LO" 13635600 "DTC_LSD_B_FAILED_HI" 13635601 "DTC_LSD_B_FAILED_LO" 13635602 "DTC_LSD_C_FAILED_HI" 13635603 "DTC_LSD_C_FAILED_LO" 13635606 "DTC_CONT_PWR_FAILED_HI" 13635607 "DTC_CONT_PWR_FAILED_LO" 13635608 "DTC_LSD_PUMP_FAILED_HI" 13635609 "DTC_LSD_PUMP_FAILED_LO" 13635610 "DTC_CHG_A_ENABLE_FAILED_HI" 13635611 "DTC_CHG_A_ENABLE_FAILED_LO" 13635612 "DTC_CHG_B_ENABLE_FAILED_HI" 13635613 "DTC_CHG_B_ENABLE_FAILED_LO" 13635614 "DTC_SW14V_PWR_FAILED_HI" 13635615 "DTC_SW14V_PWR_FAILED_LO" 13635620 "DTC_HSD_A_FAILED_HI" 13635621 "DTC_HSD_A_FAILED_LO" 13635622 "DTC_HSD_B_FAILED_HI" 13635623 "DTC_HSD_B_FAILED_LO" 13692968 "DTC_CONT_HPWR_FAILED_HI" 13692969 "DTC_CONT_HPWR_FAILED_LO" 13692970 "DTC_CONT_HPWR_OOR_HI" 13692971 "DTC_CONT_HPWR_OOR_LO" 13635616 "DTC_5V_PWR_OOR_HI" 13635617 "DTC_5V_PWR_OOR_LO" 14606336 "DTC_NVM_WRITE_TO" 14606337 "DTC_NVM_READ_TO" 14614528 "DTC_SPI_DIG_POT_FAULT" ;
VAL_ 1120 bcm_dtc_084 0 " - " 11276288 "DTC_VEPO" 11276289 "DTC_HSC_MISSING" 11460608 "DTC_NVM_SOC" 11460609 "DTC_NVM_KOT" 11460610 "DTC_NVM_DTC" 11460611 "DTC_NVM_SOC_CORRECTION" 11460612 "DTC_NVM_APP_SCRATCHPAD" 11517962 "DTC_LOOPTIME_TASK_A" 11517963 "DTC_LOOPTIME_TASK_B" 11517964 "DTC_LOOPTIME_TASK_C" 11517965 "DTC_LOOPTIME_TASK_D" 11517966 "DTC_LOOPTIME_TASK_E" 11517967 "DTC_LOOPTIME_TASK_F" 11323904 "DTC_INTERLOCK_A_FAILED_LOW" 11323905 "DTC_INTERLOCK_A_FAILED_HIGH" 11324160 "DTC_INTERLOCK_B_FAILED_LOW" 11324161 "DTC_INTERLOCK_B_FAILED_HIGH" 15728640 "DTC_EPO" 16498688 "DTC_BRUSA_MISSING" 16498689 "DTC_BRUSA_IDC" 16498690 "DTC_BRUSA_REQ_VS_CMD" 16433152 "DTC_AKERWADE_MISSING" 16433153 "DTC_AKERWADE_IDC" 16433154 "DTC_AKERWADE_REQ_VS_CMD" 16564224 "DTC_CHGLEAR_MISSING" 16564225 "DTC_CHGLEAR_IDC" 16564226 "DTC_CHGLEAR_REQ_VS_CMD" 16522240 "DTC_CSM_MISSING" 16522752 "DTC_CSM_VBAT" 16522753 "DTC_CSM_VPOS" 16522754 "DTC_CSM_VNEG" 16522755 "DTC_CSM_CPOS" 16522756 "DTC_CSM_CNEG" 16522757 "DTC_CSM_APOS" 16522758 "DTC_CSM_ANEG" 16522759 "DTC_CSM_FUSE_HI" 16522760 "DTC_CSM_FUSE_LO" 16521728 "DTC_CSM_ASIC" 16521729 "DTC_CSM_AILO" 16521730 "DTC_CSM_AIHI" 16520957 "DTC_LEAKAGE_DETECT_FAULT" 16522444 "DTC_REALTIMECLOCK_FAULT" 16520945 "DTC_CSM_LEAK_FAIL_CALC" 16520946 "DTC_CSM_LEAK_FAIL_HW" 16520947 "DTC_CSM_LEAK_EXT_SHORT" 16520948 "DTC_CSM_LEAK_MID_PACK_SHORT" 16520949 "DTC_CSM_LEAK_ERROR" 16520950 "DTC_CSM_LEAK_UNKNOWN" 16523008 "DTC_CSM_VER_MISMATCH" 16523009 "DTC_CSM_DTC_SET" 16523010 "DTC_CSM_CAL_FAULT" 16560128 "DTC_IBAT_MISMATCH" 16576512 "DTC_DIS_MAX_I2T" 16576513 "DTC_CHG_MAX_I2T" 16576768 "DTC_DIS_WARNING_I2T" 16576769 "DTC_CHG_WARNING_I2T" 11296784 "DTC_SAEJ1772_PROX_DECT_OOR_HI" 11296785 "DTC_SAEJ1772_PROX_DECT_OOR_LO" 11296800 "DTC_SAEJ1772_PILOT_PWM_OOR_HI" 11296801 "DTC_SAEJ1772_PILOT_PWM_OOR_LO" 11296802 "DTC_SAEJ1772_PILOT_PWM_DIG_COMM" 11296803 "DTC_SAEJ1772_PILOT_PWM_IR_ERR" 16175360 "DTC_FGD1_NO_SENSOR" 16175361 "DTC_FGD1_OOR_HI" 16175362 "DTC_FGD1_OOR_LO" 16175363 "DTC_FGD1_FAULT" 16175616 "DTC_FGD2_NO_SENSOR" 16175617 "DTC_FGD2_OOR_HI" 16175618 "DTC_FGD2_OOR_LO" 16175619 "DTC_FGD2_FAULT" 16171008 "DTC_CONT_OPEN" 16171009 "DTC_CONT_CLOSE" 16171010 "DTC_CONT_OPEN_CURRENT" 16171264 "DTC_CONT_CLOSE_ON_RESET" 16171265 "DTC_CONT_CLOSE_SIG_FAILED" 16171520 "DTC_PRECHARGE_TIMEOUT" 16171777 "DTC_CONT_MPOS_WELD_AT_SU" 16171778 "DTC_CONT_MNEG_WELD_AT_SU" 16171780 "DTC_CONT_CPOS_WELD_AT_SU" 16171781 "DTC_CONT_CNEG_WELD_AT_SU" 16171782 "DTC_CONT_ANEG_WELD_AT_SU" 16171783 "DTC_CONT_APOS_WELD_AT_SU" 16172033 "DTC_CONT_MPOS_WELD_AT_SD" 16172034 "DTC_CONT_MNEG_WELD_AT_SD" 16172036 "DTC_CONT_CPOS_WELD_AT_SD" 16172037 "DTC_CONT_CNEG_WELD_AT_SD" 16172038 "DTC_CONT_ANEG_WELD_AT_SD" 16172039 "DTC_CONT_APOS_WELD_AT_SD" 16172289 "DTC_CONT_MPOS_OPEN" 16172290 "DTC_CONT_MNEG_OPEN" 16172291 "DTC_CONT_MPRE_OPEN" 16172292 "DTC_CONT_CPOS_OPEN" 16172293 "DTC_CONT_CNEG_OPEN" 16172294 "DTC_CONT_APOS_OPEN" 16172295 "DTC_CONT_ANEG_OPEN" 16172545 "DTC_CONT_MPOS_VDIF" 16172546 "DTC_CONT_MNEG_VDIF" 16172548 "DTC_CONT_CPOS_VDIF" 16172549 "DTC_CONT_CNEG_VDIF" 16172550 "DTC_CONT_APOS_VDIF" 16172551 "DTC_CONT_ANEG_VDIF" 16174848 "DTC_HVIL" 16174849 "DTC_LVBAT_LO" 16174850 "DTC_LVBAT_HI" 16174851 "DTC_LVBAT_ERR" 16523520 "DTC_LEMLO_OOR_HI" 16523521 "DTC_LEMLO_OOR_LO" 16523522 "DTC_LEMLO_FAULT" 16523776 "DTC_LEMHI_OOR_HI" 16523777 "DTC_LEMHI_OOR_LO" 16523778 "DTC_LEMHI_FAULT" 16496320 "DTC_MBB_TOO_FEW" 16496321 "DTC_MBB_TOO_MANY" 16496352 "DTC_CELL_VMAX_ERR" 16496353 "DTC_CELL_VMIN_ERR" 16496354 "DTC_CELL_VMAX" 16496362 "DTC_CELL_VMAX_SEVERE" 16496355 "DTC_CELL_VMIN" 16496363 "DTC_CELL_VMIN_SEVERE" 16496356 "DTC_MOD_VOLTAGE_COMPARE" 16496336 "DTC_CELL_T_ERR" 16496337 "DTC_CELL_TMAX1" 16496338 "DTC_CELL_TMAX2" 16496339 "DTC_CELL_TMIN" 16497665 "DTC_MBB_01_MISSING" 16497666 "DTC_MBB_02_MISSING" 16497667 "DTC_MBB_03_MISSING" 16497668 "DTC_MBB_04_MISSING" 16497669 "DTC_MBB_05_MISSING" 16497670 "DTC_MBB_06_MISSING" 16497671 "DTC_MBB_07_MISSING" 16497672 "DTC_MBB_08_MISSING" 16497673 "DTC_MBB_09_MISSING" 16497680 "DTC_MBB_10_MISSING" 16497681 "DTC_MBB_11_MISSING" 16497682 "DTC_MBB_12_MISSING" 16497683 "DTC_MBB_13_MISSING" 16497684 "DTC_MBB_14_MISSING" 16497685 "DTC_MBB_15_MISSING" 16497686 "DTC_MBB_16_MISSING" 16497687 "DTC_MBB_17_MISSING" 16497688 "DTC_MBB_18_MISSING" 16497689 "DTC_MBB_19_MISSING" 16497696 "DTC_MBB_20_MISSING" 16497697 "DTC_MBB_21_MISSING" 16497698 "DTC_MBB_22_MISSING" 16497699 "DTC_MBB_23_MISSING" 16497700 "DTC_MBB_24_MISSING" 16498177 "DTC_MBB_01_VFAULT" 16498178 "DTC_MBB_02_VFAULT" 16498179 "DTC_MBB_03_VFAULT" 16498180 "DTC_MBB_04_VFAULT" 16498181 "DTC_MBB_05_VFAULT" 16498182 "DTC_MBB_06_VFAULT" 16498183 "DTC_MBB_07_VFAULT" 16498184 "DTC_MBB_08_VFAULT" 16498185 "DTC_MBB_09_VFAULT" 16498192 "DTC_MBB_10_VFAULT" 16498193 "DTC_MBB_11_VFAULT" 16498194 "DTC_MBB_12_VFAULT" 16498195 "DTC_MBB_13_VFAULT" 16498196 "DTC_MBB_14_VFAULT" 16498197 "DTC_MBB_15_VFAULT" 16498198 "DTC_MBB_16_VFAULT" 16498199 "DTC_MBB_17_VFAULT" 16498200 "DTC_MBB_18_VFAULT" 16498201 "DTC_MBB_19_VFAULT" 16498208 "DTC_MBB_20_VFAULT" 16498209 "DTC_MBB_21_VFAULT" 16498210 "DTC_MBB_22_VFAULT" 16498211 "DTC_MBB_23_VFAULT" 16498212 "DTC_MBB_24_VFAULT" 16497921 "DTC_MBB_01_TFAULT" 16497922 "DTC_MBB_02_TFAULT" 16497923 "DTC_MBB_03_TFAULT" 16497924 "DTC_MBB_04_TFAULT" 16497925 "DTC_MBB_05_TFAULT" 16497926 "DTC_MBB_06_TFAULT" 16497927 "DTC_MBB_07_TFAULT" 16497928 "DTC_MBB_08_TFAULT" 16497929 "DTC_MBB_09_TFAULT" 16497936 "DTC_MBB_10_TFAULT" 16497937 "DTC_MBB_11_TFAULT" 16497938 "DTC_MBB_12_TFAULT" 16497939 "DTC_MBB_13_TFAULT" 16497940 "DTC_MBB_14_TFAULT" 16497941 "DTC_MBB_15_TFAULT" 16497942 "DTC_MBB_16_TFAULT" 16497943 "DTC_MBB_17_TFAULT" 16497944 "DTC_MBB_18_TFAULT" 16497945 "DTC_MBB_19_TFAULT" 16497952 "DTC_MBB_20_TFAULT" 16497953 "DTC_MBB_21_TFAULT" 16497954 "DTC_MBB_22_TFAULT" 16497955 "DTC_MBB_23_TFAULT" 16497956 "DTC_MBB_24_TFAULT" 15785984 "DTC_PRECHARGE_ENERGY" 15785985 "DTC_PRT_FAILED" 15785986 "DTC_PRT_OVERTEMP" 15785987 "DTC_PRT_PROHIBIT" 16556032 "DTC_COOLANT_TEMP_OOR_HI" 16556033 "DTC_COOLANT_TEMP_OOR_LO" 16252928 "DTC_KEY_OFF_TIME_ERROR" 16506880 "DTC_VBAT_MISMATCH" 16506881 "DTC_VBAT_VMAX" 16506882 "DTC_VBAT_VMIN" 16506883 "DTC_PACK_FUSE" 15798544 "DTC_LLS1_OOR_HI" 15798545 "DTC_LLS1_OOR_LO" 15798546 "DTC_LLS1_FAULT" 15798816 "DTC_LLS2_OOR_HI" 15798817 "DTC_LLS2_OOR_LO" 15798818 "DTC_LLS2_FAULT" 14479360 "DTC_CFL_HEARTBEAT" 14479361 "DTC_CFL_FAULT" 14479362 "DTC_CFL_FAULT_LATCH" 13635584 "DTC_CONT_A_FAILED_HI" 13635585 "DTC_CONT_A_FAILED_LO" 13635586 "DTC_CONT_B_FAILED_HI" 13635587 "DTC_CONT_B_FAILED_LO" 13635588 "DTC_CONT_C_FAILED_HI" 13635589 "DTC_CONT_C_FAILED_LO" 13635590 "DTC_CONT_D_FAILED_HI" 13635591 "DTC_CONT_D_FAILED_LO" 13635592 "DTC_CONT_E_FAILED_HI" 13635593 "DTC_CONT_E_FAILED_LO" 13635594 "DTC_CONT_F_FAILED_HI" 13635595 "DTC_CONT_F_FAILED_LO" 13635596 "DTC_CONT_G_FAILED_HI" 13635597 "DTC_CONT_G_FAILED_LO" 13635598 "DTC_LSD_A_FAILED_HI" 13635599 "DTC_LSD_A_FAILED_LO" 13635600 "DTC_LSD_B_FAILED_HI" 13635601 "DTC_LSD_B_FAILED_LO" 13635602 "DTC_LSD_C_FAILED_HI" 13635603 "DTC_LSD_C_FAILED_LO" 13635606 "DTC_CONT_PWR_FAILED_HI" 13635607 "DTC_CONT_PWR_FAILED_LO" 13635608 "DTC_LSD_PUMP_FAILED_HI" 13635609 "DTC_LSD_PUMP_FAILED_LO" 13635610 "DTC_CHG_A_ENABLE_FAILED_HI" 13635611 "DTC_CHG_A_ENABLE_FAILED_LO" 13635612 "DTC_CHG_B_ENABLE_FAILED_HI" 13635613 "DTC_CHG_B_ENABLE_FAILED_LO" 13635614 "DTC_SW14V_PWR_FAILED_HI" 13635615 "DTC_SW14V_PWR_FAILED_LO" 13635620 "DTC_HSD_A_FAILED_HI" 13635621 "DTC_HSD_A_FAILED_LO" 13635622 "DTC_HSD_B_FAILED_HI" 13635623 "DTC_HSD_B_FAILED_LO" 13692968 "DTC_CONT_HPWR_FAILED_HI" 13692969 "DTC_CONT_HPWR_FAILED_LO" 13692970 "DTC_CONT_HPWR_OOR_HI" 13692971 "DTC_CONT_HPWR_OOR_LO" 13635616 "DTC_5V_PWR_OOR_HI" 13635617 "DTC_5V_PWR_OOR_LO" 14606336 "DTC_NVM_WRITE_TO" 14606337 "DTC_NVM_READ_TO" 14614528 "DTC_SPI_DIG_POT_FAULT" ;
VAL_ 1120 bcm_dtc_085 0 " - " 11276288 "DTC_VEPO" 11276289 "DTC_HSC_MISSING" 11460608 "DTC_NVM_SOC" 11460609 "DTC_NVM_KOT" 11460610 "DTC_NVM_DTC" 11460611 "DTC_NVM_SOC_CORRECTION" 11460612 "DTC_NVM_APP_SCRATCHPAD" 11517962 "DTC_LOOPTIME_TASK_A" 11517963 "DTC_LOOPTIME_TASK_B" 11517964 "DTC_LOOPTIME_TASK_C" 11517965 "DTC_LOOPTIME_TASK_D" 11517966 "DTC_LOOPTIME_TASK_E" 11517967 "DTC_LOOPTIME_TASK_F" 11323904 "DTC_INTERLOCK_A_FAILED_LOW" 11323905 "DTC_INTERLOCK_A_FAILED_HIGH" 11324160 "DTC_INTERLOCK_B_FAILED_LOW" 11324161 "DTC_INTERLOCK_B_FAILED_HIGH" 15728640 "DTC_EPO" 16498688 "DTC_BRUSA_MISSING" 16498689 "DTC_BRUSA_IDC" 16498690 "DTC_BRUSA_REQ_VS_CMD" 16433152 "DTC_AKERWADE_MISSING" 16433153 "DTC_AKERWADE_IDC" 16433154 "DTC_AKERWADE_REQ_VS_CMD" 16564224 "DTC_CHGLEAR_MISSING" 16564225 "DTC_CHGLEAR_IDC" 16564226 "DTC_CHGLEAR_REQ_VS_CMD" 16522240 "DTC_CSM_MISSING" 16522752 "DTC_CSM_VBAT" 16522753 "DTC_CSM_VPOS" 16522754 "DTC_CSM_VNEG" 16522755 "DTC_CSM_CPOS" 16522756 "DTC_CSM_CNEG" 16522757 "DTC_CSM_APOS" 16522758 "DTC_CSM_ANEG" 16522759 "DTC_CSM_FUSE_HI" 16522760 "DTC_CSM_FUSE_LO" 16521728 "DTC_CSM_ASIC" 16521729 "DTC_CSM_AILO" 16521730 "DTC_CSM_AIHI" 16520957 "DTC_LEAKAGE_DETECT_FAULT" 16522444 "DTC_REALTIMECLOCK_FAULT" 16520945 "DTC_CSM_LEAK_FAIL_CALC" 16520946 "DTC_CSM_LEAK_FAIL_HW" 16520947 "DTC_CSM_LEAK_EXT_SHORT" 16520948 "DTC_CSM_LEAK_MID_PACK_SHORT" 16520949 "DTC_CSM_LEAK_ERROR" 16520950 "DTC_CSM_LEAK_UNKNOWN" 16523008 "DTC_CSM_VER_MISMATCH" 16523009 "DTC_CSM_DTC_SET" 16523010 "DTC_CSM_CAL_FAULT" 16560128 "DTC_IBAT_MISMATCH" 16576512 "DTC_DIS_MAX_I2T" 16576513 "DTC_CHG_MAX_I2T" 16576768 "DTC_DIS_WARNING_I2T" 16576769 "DTC_CHG_WARNING_I2T" 11296784 "DTC_SAEJ1772_PROX_DECT_OOR_HI" 11296785 "DTC_SAEJ1772_PROX_DECT_OOR_LO" 11296800 "DTC_SAEJ1772_PILOT_PWM_OOR_HI" 11296801 "DTC_SAEJ1772_PILOT_PWM_OOR_LO" 11296802 "DTC_SAEJ1772_PILOT_PWM_DIG_COMM" 11296803 "DTC_SAEJ1772_PILOT_PWM_IR_ERR" 16175360 "DTC_FGD1_NO_SENSOR" 16175361 "DTC_FGD1_OOR_HI" 16175362 "DTC_FGD1_OOR_LO" 16175363 "DTC_FGD1_FAULT" 16175616 "DTC_FGD2_NO_SENSOR" 16175617 "DTC_FGD2_OOR_HI" 16175618 "DTC_FGD2_OOR_LO" 16175619 "DTC_FGD2_FAULT" 16171008 "DTC_CONT_OPEN" 16171009 "DTC_CONT_CLOSE" 16171010 "DTC_CONT_OPEN_CURRENT" 16171264 "DTC_CONT_CLOSE_ON_RESET" 16171265 "DTC_CONT_CLOSE_SIG_FAILED" 16171520 "DTC_PRECHARGE_TIMEOUT" 16171777 "DTC_CONT_MPOS_WELD_AT_SU" 16171778 "DTC_CONT_MNEG_WELD_AT_SU" 16171780 "DTC_CONT_CPOS_WELD_AT_SU" 16171781 "DTC_CONT_CNEG_WELD_AT_SU" 16171782 "DTC_CONT_ANEG_WELD_AT_SU" 16171783 "DTC_CONT_APOS_WELD_AT_SU" 16172033 "DTC_CONT_MPOS_WELD_AT_SD" 16172034 "DTC_CONT_MNEG_WELD_AT_SD" 16172036 "DTC_CONT_CPOS_WELD_AT_SD" 16172037 "DTC_CONT_CNEG_WELD_AT_SD" 16172038 "DTC_CONT_ANEG_WELD_AT_SD" 16172039 "DTC_CONT_APOS_WELD_AT_SD" 16172289 "DTC_CONT_MPOS_OPEN" 16172290 "DTC_CONT_MNEG_OPEN" 16172291 "DTC_CONT_MPRE_OPEN" 16172292 "DTC_CONT_CPOS_OPEN" 16172293 "DTC_CONT_CNEG_OPEN" 16172294 "DTC_CONT_APOS_OPEN" 16172295 "DTC_CONT_ANEG_OPEN" 16172545 "DTC_CONT_MPOS_VDIF" 16172546 "DTC_CONT_MNEG_VDIF" 16172548 "DTC_CONT_CPOS_VDIF" 16172549 "DTC_CONT_CNEG_VDIF" 16172550 "DTC_CONT_APOS_VDIF" 16172551 "DTC_CONT_ANEG_VDIF" 16174848 "DTC_HVIL" 16174849 "DTC_LVBAT_LO" 16174850 "DTC_LVBAT_HI" 16174851 "DTC_LVBAT_ERR" 16523520 "DTC_LEMLO_OOR_HI" 16523521 "DTC_LEMLO_OOR_LO" 16523522 "DTC_LEMLO_FAULT" 16523776 "DTC_LEMHI_OOR_HI" 16523777 "DTC_LEMHI_OOR_LO" 16523778 "DTC_LEMHI_FAULT" 16496320 "DTC_MBB_TOO_FEW" 16496321 "DTC_MBB_TOO_MANY" 16496352 "DTC_CELL_VMAX_ERR" 16496353 "DTC_CELL_VMIN_ERR" 16496354 "DTC_CELL_VMAX" 16496362 "DTC_CELL_VMAX_SEVERE" 16496355 "DTC_CELL_VMIN" 16496363 "DTC_CELL_VMIN_SEVERE" 16496356 "DTC_MOD_VOLTAGE_COMPARE" 16496336 "DTC_CELL_T_ERR" 16496337 "DTC_CELL_TMAX1" 16496338 "DTC_CELL_TMAX2" 16496339 "DTC_CELL_TMIN" 16497665 "DTC_MBB_01_MISSING" 16497666 "DTC_MBB_02_MISSING" 16497667 "DTC_MBB_03_MISSING" 16497668 "DTC_MBB_04_MISSING" 16497669 "DTC_MBB_05_MISSING" 16497670 "DTC_MBB_06_MISSING" 16497671 "DTC_MBB_07_MISSING" 16497672 "DTC_MBB_08_MISSING" 16497673 "DTC_MBB_09_MISSING" 16497680 "DTC_MBB_10_MISSING" 16497681 "DTC_MBB_11_MISSING" 16497682 "DTC_MBB_12_MISSING" 16497683 "DTC_MBB_13_MISSING" 16497684 "DTC_MBB_14_MISSING" 16497685 "DTC_MBB_15_MISSING" 16497686 "DTC_MBB_16_MISSING" 16497687 "DTC_MBB_17_MISSING" 16497688 "DTC_MBB_18_MISSING" 16497689 "DTC_MBB_19_MISSING" 16497696 "DTC_MBB_20_MISSING" 16497697 "DTC_MBB_21_MISSING" 16497698 "DTC_MBB_22_MISSING" 16497699 "DTC_MBB_23_MISSING" 16497700 "DTC_MBB_24_MISSING" 16498177 "DTC_MBB_01_VFAULT" 16498178 "DTC_MBB_02_VFAULT" 16498179 "DTC_MBB_03_VFAULT" 16498180 "DTC_MBB_04_VFAULT" 16498181 "DTC_MBB_05_VFAULT" 16498182 "DTC_MBB_06_VFAULT" 16498183 "DTC_MBB_07_VFAULT" 16498184 "DTC_MBB_08_VFAULT" 16498185 "DTC_MBB_09_VFAULT" 16498192 "DTC_MBB_10_VFAULT" 16498193 "DTC_MBB_11_VFAULT" 16498194 "DTC_MBB_12_VFAULT" 16498195 "DTC_MBB_13_VFAULT" 16498196 "DTC_MBB_14_VFAULT" 16498197 "DTC_MBB_15_VFAULT" 16498198 "DTC_MBB_16_VFAULT" 16498199 "DTC_MBB_17_VFAULT" 16498200 "DTC_MBB_18_VFAULT" 16498201 "DTC_MBB_19_VFAULT" 16498208 "DTC_MBB_20_VFAULT" 16498209 "DTC_MBB_21_VFAULT" 16498210 "DTC_MBB_22_VFAULT" 16498211 "DTC_MBB_23_VFAULT" 16498212 "DTC_MBB_24_VFAULT" 16497921 "DTC_MBB_01_TFAULT" 16497922 "DTC_MBB_02_TFAULT" 16497923 "DTC_MBB_03_TFAULT" 16497924 "DTC_MBB_04_TFAULT" 16497925 "DTC_MBB_05_TFAULT" 16497926 "DTC_MBB_06_TFAULT" 16497927 "DTC_MBB_07_TFAULT" 16497928 "DTC_MBB_08_TFAULT" 16497929 "DTC_MBB_09_TFAULT" 16497936 "DTC_MBB_10_TFAULT" 16497937 "DTC_MBB_11_TFAULT" 16497938 "DTC_MBB_12_TFAULT" 16497939 "DTC_MBB_13_TFAULT" 16497940 "DTC_MBB_14_TFAULT" 16497941 "DTC_MBB_15_TFAULT" 16497942 "DTC_MBB_16_TFAULT" 16497943 "DTC_MBB_17_TFAULT" 16497944 "DTC_MBB_18_TFAULT" 16497945 "DTC_MBB_19_TFAULT" 16497952 "DTC_MBB_20_TFAULT" 16497953 "DTC_MBB_21_TFAULT" 16497954 "DTC_MBB_22_TFAULT" 16497955 "DTC_MBB_23_TFAULT" 16497956 "DTC_MBB_24_TFAULT" 15785984 "DTC_PRECHARGE_ENERGY" 15785985 "DTC_PRT_FAILED" 15785986 "DTC_PRT_OVERTEMP" 15785987 "DTC_PRT_PROHIBIT" 16556032 "DTC_COOLANT_TEMP_OOR_HI" 16556033 "DTC_COOLANT_TEMP_OOR_LO" 16252928 "DTC_KEY_OFF_TIME_ERROR" 16506880 "DTC_VBAT_MISMATCH" 16506881 "DTC_VBAT_VMAX" 16506882 "DTC_VBAT_VMIN" 16506883 "DTC_PACK_FUSE" 15798544 "DTC_LLS1_OOR_HI" 15798545 "DTC_LLS1_OOR_LO" 15798546 "DTC_LLS1_FAULT" 15798816 "DTC_LLS2_OOR_HI" 15798817 "DTC_LLS2_OOR_LO" 15798818 "DTC_LLS2_FAULT" 14479360 "DTC_CFL_HEARTBEAT" 14479361 "DTC_CFL_FAULT" 14479362 "DTC_CFL_FAULT_LATCH" 13635584 "DTC_CONT_A_FAILED_HI" 13635585 "DTC_CONT_A_FAILED_LO" 13635586 "DTC_CONT_B_FAILED_HI" 13635587 "DTC_CONT_B_FAILED_LO" 13635588 "DTC_CONT_C_FAILED_HI" 13635589 "DTC_CONT_C_FAILED_LO" 13635590 "DTC_CONT_D_FAILED_HI" 13635591 "DTC_CONT_D_FAILED_LO" 13635592 "DTC_CONT_E_FAILED_HI" 13635593 "DTC_CONT_E_FAILED_LO" 13635594 "DTC_CONT_F_FAILED_HI" 13635595 "DTC_CONT_F_FAILED_LO" 13635596 "DTC_CONT_G_FAILED_HI" 13635597 "DTC_CONT_G_FAILED_LO" 13635598 "DTC_LSD_A_FAILED_HI" 13635599 "DTC_LSD_A_FAILED_LO" 13635600 "DTC_LSD_B_FAILED_HI" 13635601 "DTC_LSD_B_FAILED_LO" 13635602 "DTC_LSD_C_FAILED_HI" 13635603 "DTC_LSD_C_FAILED_LO" 13635606 "DTC_CONT_PWR_FAILED_HI" 13635607 "DTC_CONT_PWR_FAILED_LO" 13635608 "DTC_LSD_PUMP_FAILED_HI" 13635609 "DTC_LSD_PUMP_FAILED_LO" 13635610 "DTC_CHG_A_ENABLE_FAILED_HI" 13635611 "DTC_CHG_A_ENABLE_FAILED_LO" 13635612 "DTC_CHG_B_ENABLE_FAILED_HI" 13635613 "DTC_CHG_B_ENABLE_FAILED_LO" 13635614 "DTC_SW14V_PWR_FAILED_HI" 13635615 "DTC_SW14V_PWR_FAILED_LO" 13635620 "DTC_HSD_A_FAILED_HI" 13635621 "DTC_HSD_A_FAILED_LO" 13635622 "DTC_HSD_B_FAILED_HI" 13635623 "DTC_HSD_B_FAILED_LO" 13692968 "DTC_CONT_HPWR_FAILED_HI" 13692969 "DTC_CONT_HPWR_FAILED_LO" 13692970 "DTC_CONT_HPWR_OOR_HI" 13692971 "DTC_CONT_HPWR_OOR_LO" 13635616 "DTC_5V_PWR_OOR_HI" 13635617 "DTC_5V_PWR_OOR_LO" 14606336 "DTC_NVM_WRITE_TO" 14606337 "DTC_NVM_READ_TO" 14614528 "DTC_SPI_DIG_POT_FAULT" ;
VAL_ 1120 bcm_dtc_086 0 " - " 11276288 "DTC_VEPO" 11276289 "DTC_HSC_MISSING" 11460608 "DTC_NVM_SOC" 11460609 "DTC_NVM_KOT" 11460610 "DTC_NVM_DTC" 11460611 "DTC_NVM_SOC_CORRECTION" 11460612 "DTC_NVM_APP_SCRATCHPAD" 11517962 "DTC_LOOPTIME_TASK_A" 11517963 "DTC_LOOPTIME_TASK_B" 11517964 "DTC_LOOPTIME_TASK_C" 11517965 "DTC_LOOPTIME_TASK_D" 11517966 "DTC_LOOPTIME_TASK_E" 11517967 "DTC_LOOPTIME_TASK_F" 11323904 "DTC_INTERLOCK_A_FAILED_LOW" 11323905 "DTC_INTERLOCK_A_FAILED_HIGH" 11324160 "DTC_INTERLOCK_B_FAILED_LOW" 11324161 "DTC_INTERLOCK_B_FAILED_HIGH" 15728640 "DTC_EPO" 16498688 "DTC_BRUSA_MISSING" 16498689 "DTC_BRUSA_IDC" 16498690 "DTC_BRUSA_REQ_VS_CMD" 16433152 "DTC_AKERWADE_MISSING" 16433153 "DTC_AKERWADE_IDC" 16433154 "DTC_AKERWADE_REQ_VS_CMD" 16564224 "DTC_CHGLEAR_MISSING" 16564225 "DTC_CHGLEAR_IDC" 16564226 "DTC_CHGLEAR_REQ_VS_CMD" 16522240 "DTC_CSM_MISSING" 16522752 "DTC_CSM_VBAT" 16522753 "DTC_CSM_VPOS" 16522754 "DTC_CSM_VNEG" 16522755 "DTC_CSM_CPOS" 16522756 "DTC_CSM_CNEG" 16522757 "DTC_CSM_APOS" 16522758 "DTC_CSM_ANEG" 16522759 "DTC_CSM_FUSE_HI" 16522760 "DTC_CSM_FUSE_LO" 16521728 "DTC_CSM_ASIC" 16521729 "DTC_CSM_AILO" 16521730 "DTC_CSM_AIHI" 16520957 "DTC_LEAKAGE_DETECT_FAULT" 16522444 "DTC_REALTIMECLOCK_FAULT" 16520945 "DTC_CSM_LEAK_FAIL_CALC" 16520946 "DTC_CSM_LEAK_FAIL_HW" 16520947 "DTC_CSM_LEAK_EXT_SHORT" 16520948 "DTC_CSM_LEAK_MID_PACK_SHORT" 16520949 "DTC_CSM_LEAK_ERROR" 16520950 "DTC_CSM_LEAK_UNKNOWN" 16523008 "DTC_CSM_VER_MISMATCH" 16523009 "DTC_CSM_DTC_SET" 16523010 "DTC_CSM_CAL_FAULT" 16560128 "DTC_IBAT_MISMATCH" 16576512 "DTC_DIS_MAX_I2T" 16576513 "DTC_CHG_MAX_I2T" 16576768 "DTC_DIS_WARNING_I2T" 16576769 "DTC_CHG_WARNING_I2T" 11296784 "DTC_SAEJ1772_PROX_DECT_OOR_HI" 11296785 "DTC_SAEJ1772_PROX_DECT_OOR_LO" 11296800 "DTC_SAEJ1772_PILOT_PWM_OOR_HI" 11296801 "DTC_SAEJ1772_PILOT_PWM_OOR_LO" 11296802 "DTC_SAEJ1772_PILOT_PWM_DIG_COMM" 11296803 "DTC_SAEJ1772_PILOT_PWM_IR_ERR" 16175360 "DTC_FGD1_NO_SENSOR" 16175361 "DTC_FGD1_OOR_HI" 16175362 "DTC_FGD1_OOR_LO" 16175363 "DTC_FGD1_FAULT" 16175616 "DTC_FGD2_NO_SENSOR" 16175617 "DTC_FGD2_OOR_HI" 16175618 "DTC_FGD2_OOR_LO" 16175619 "DTC_FGD2_FAULT" 16171008 "DTC_CONT_OPEN" 16171009 "DTC_CONT_CLOSE" 16171010 "DTC_CONT_OPEN_CURRENT" 16171264 "DTC_CONT_CLOSE_ON_RESET" 16171265 "DTC_CONT_CLOSE_SIG_FAILED" 16171520 "DTC_PRECHARGE_TIMEOUT" 16171777 "DTC_CONT_MPOS_WELD_AT_SU" 16171778 "DTC_CONT_MNEG_WELD_AT_SU" 16171780 "DTC_CONT_CPOS_WELD_AT_SU" 16171781 "DTC_CONT_CNEG_WELD_AT_SU" 16171782 "DTC_CONT_ANEG_WELD_AT_SU" 16171783 "DTC_CONT_APOS_WELD_AT_SU" 16172033 "DTC_CONT_MPOS_WELD_AT_SD" 16172034 "DTC_CONT_MNEG_WELD_AT_SD" 16172036 "DTC_CONT_CPOS_WELD_AT_SD" 16172037 "DTC_CONT_CNEG_WELD_AT_SD" 16172038 "DTC_CONT_ANEG_WELD_AT_SD" 16172039 "DTC_CONT_APOS_WELD_AT_SD" 16172289 "DTC_CONT_MPOS_OPEN" 16172290 "DTC_CONT_MNEG_OPEN" 16172291 "DTC_CONT_MPRE_OPEN" 16172292 "DTC_CONT_CPOS_OPEN" 16172293 "DTC_CONT_CNEG_OPEN" 16172294 "DTC_CONT_APOS_OPEN" 16172295 "DTC_CONT_ANEG_OPEN" 16172545 "DTC_CONT_MPOS_VDIF" 16172546 "DTC_CONT_MNEG_VDIF" 16172548 "DTC_CONT_CPOS_VDIF" 16172549 "DTC_CONT_CNEG_VDIF" 16172550 "DTC_CONT_APOS_VDIF" 16172551 "DTC_CONT_ANEG_VDIF" 16174848 "DTC_HVIL" 16174849 "DTC_LVBAT_LO" 16174850 "DTC_LVBAT_HI" 16174851 "DTC_LVBAT_ERR" 16523520 "DTC_LEMLO_OOR_HI" 16523521 "DTC_LEMLO_OOR_LO" 16523522 "DTC_LEMLO_FAULT" 16523776 "DTC_LEMHI_OOR_HI" 16523777 "DTC_LEMHI_OOR_LO" 16523778 "DTC_LEMHI_FAULT" 16496320 "DTC_MBB_TOO_FEW" 16496321 "DTC_MBB_TOO_MANY" 16496352 "DTC_CELL_VMAX_ERR" 16496353 "DTC_CELL_VMIN_ERR" 16496354 "DTC_CELL_VMAX" 16496362 "DTC_CELL_VMAX_SEVERE" 16496355 "DTC_CELL_VMIN" 16496363 "DTC_CELL_VMIN_SEVERE" 16496356 "DTC_MOD_VOLTAGE_COMPARE" 16496336 "DTC_CELL_T_ERR" 16496337 "DTC_CELL_TMAX1" 16496338 "DTC_CELL_TMAX2" 16496339 "DTC_CELL_TMIN" 16497665 "DTC_MBB_01_MISSING" 16497666 "DTC_MBB_02_MISSING" 16497667 "DTC_MBB_03_MISSING" 16497668 "DTC_MBB_04_MISSING" 16497669 "DTC_MBB_05_MISSING" 16497670 "DTC_MBB_06_MISSING" 16497671 "DTC_MBB_07_MISSING" 16497672 "DTC_MBB_08_MISSING" 16497673 "DTC_MBB_09_MISSING" 16497680 "DTC_MBB_10_MISSING" 16497681 "DTC_MBB_11_MISSING" 16497682 "DTC_MBB_12_MISSING" 16497683 "DTC_MBB_13_MISSING" 16497684 "DTC_MBB_14_MISSING" 16497685 "DTC_MBB_15_MISSING" 16497686 "DTC_MBB_16_MISSING" 16497687 "DTC_MBB_17_MISSING" 16497688 "DTC_MBB_18_MISSING" 16497689 "DTC_MBB_19_MISSING" 16497696 "DTC_MBB_20_MISSING" 16497697 "DTC_MBB_21_MISSING" 16497698 "DTC_MBB_22_MISSING" 16497699 "DTC_MBB_23_MISSING" 16497700 "DTC_MBB_24_MISSING" 16498177 "DTC_MBB_01_VFAULT" 16498178 "DTC_MBB_02_VFAULT" 16498179 "DTC_MBB_03_VFAULT" 16498180 "DTC_MBB_04_VFAULT" 16498181 "DTC_MBB_05_VFAULT" 16498182 "DTC_MBB_06_VFAULT" 16498183 "DTC_MBB_07_VFAULT" 16498184 "DTC_MBB_08_VFAULT" 16498185 "DTC_MBB_09_VFAULT" 16498192 "DTC_MBB_10_VFAULT" 16498193 "DTC_MBB_11_VFAULT" 16498194 "DTC_MBB_12_VFAULT" 16498195 "DTC_MBB_13_VFAULT" 16498196 "DTC_MBB_14_VFAULT" 16498197 "DTC_MBB_15_VFAULT" 16498198 "DTC_MBB_16_VFAULT" 16498199 "DTC_MBB_17_VFAULT" 16498200 "DTC_MBB_18_VFAULT" 16498201 "DTC_MBB_19_VFAULT" 16498208 "DTC_MBB_20_VFAULT" 16498209 "DTC_MBB_21_VFAULT" 16498210 "DTC_MBB_22_VFAULT" 16498211 "DTC_MBB_23_VFAULT" 16498212 "DTC_MBB_24_VFAULT" 16497921 "DTC_MBB_01_TFAULT" 16497922 "DTC_MBB_02_TFAULT" 16497923 "DTC_MBB_03_TFAULT" 16497924 "DTC_MBB_04_TFAULT" 16497925 "DTC_MBB_05_TFAULT" 16497926 "DTC_MBB_06_TFAULT" 16497927 "DTC_MBB_07_TFAULT" 16497928 "DTC_MBB_08_TFAULT" 16497929 "DTC_MBB_09_TFAULT" 16497936 "DTC_MBB_10_TFAULT" 16497937 "DTC_MBB_11_TFAULT" 16497938 "DTC_MBB_12_TFAULT" 16497939 "DTC_MBB_13_TFAULT" 16497940 "DTC_MBB_14_TFAULT" 16497941 "DTC_MBB_15_TFAULT" 16497942 "DTC_MBB_16_TFAULT" 16497943 "DTC_MBB_17_TFAULT" 16497944 "DTC_MBB_18_TFAULT" 16497945 "DTC_MBB_19_TFAULT" 16497952 "DTC_MBB_20_TFAULT" 16497953 "DTC_MBB_21_TFAULT" 16497954 "DTC_MBB_22_TFAULT" 16497955 "DTC_MBB_23_TFAULT" 16497956 "DTC_MBB_24_TFAULT" 15785984 "DTC_PRECHARGE_ENERGY" 15785985 "DTC_PRT_FAILED" 15785986 "DTC_PRT_OVERTEMP" 15785987 "DTC_PRT_PROHIBIT" 16556032 "DTC_COOLANT_TEMP_OOR_HI" 16556033 "DTC_COOLANT_TEMP_OOR_LO" 16252928 "DTC_KEY_OFF_TIME_ERROR" 16506880 "DTC_VBAT_MISMATCH" 16506881 "DTC_VBAT_VMAX" 16506882 "DTC_VBAT_VMIN" 16506883 "DTC_PACK_FUSE" 15798544 "DTC_LLS1_OOR_HI" 15798545 "DTC_LLS1_OOR_LO" 15798546 "DTC_LLS1_FAULT" 15798816 "DTC_LLS2_OOR_HI" 15798817 "DTC_LLS2_OOR_LO" 15798818 "DTC_LLS2_FAULT" 14479360 "DTC_CFL_HEARTBEAT" 14479361 "DTC_CFL_FAULT" 14479362 "DTC_CFL_FAULT_LATCH" 13635584 "DTC_CONT_A_FAILED_HI" 13635585 "DTC_CONT_A_FAILED_LO" 13635586 "DTC_CONT_B_FAILED_HI" 13635587 "DTC_CONT_B_FAILED_LO" 13635588 "DTC_CONT_C_FAILED_HI" 13635589 "DTC_CONT_C_FAILED_LO" 13635590 "DTC_CONT_D_FAILED_HI" 13635591 "DTC_CONT_D_FAILED_LO" 13635592 "DTC_CONT_E_FAILED_HI" 13635593 "DTC_CONT_E_FAILED_LO" 13635594 "DTC_CONT_F_FAILED_HI" 13635595 "DTC_CONT_F_FAILED_LO" 13635596 "DTC_CONT_G_FAILED_HI" 13635597 "DTC_CONT_G_FAILED_LO" 13635598 "DTC_LSD_A_FAILED_HI" 13635599 "DTC_LSD_A_FAILED_LO" 13635600 "DTC_LSD_B_FAILED_HI" 13635601 "DTC_LSD_B_FAILED_LO" 13635602 "DTC_LSD_C_FAILED_HI" 13635603 "DTC_LSD_C_FAILED_LO" 13635606 "DTC_CONT_PWR_FAILED_HI" 13635607 "DTC_CONT_PWR_FAILED_LO" 13635608 "DTC_LSD_PUMP_FAILED_HI" 13635609 "DTC_LSD_PUMP_FAILED_LO" 13635610 "DTC_CHG_A_ENABLE_FAILED_HI" 13635611 "DTC_CHG_A_ENABLE_FAILED_LO" 13635612 "DTC_CHG_B_ENABLE_FAILED_HI" 13635613 "DTC_CHG_B_ENABLE_FAILED_LO" 13635614 "DTC_SW14V_PWR_FAILED_HI" 13635615 "DTC_SW14V_PWR_FAILED_LO" 13635620 "DTC_HSD_A_FAILED_HI" 13635621 "DTC_HSD_A_FAILED_LO" 13635622 "DTC_HSD_B_FAILED_HI" 13635623 "DTC_HSD_B_FAILED_LO" 13692968 "DTC_CONT_HPWR_FAILED_HI" 13692969 "DTC_CONT_HPWR_FAILED_LO" 13692970 "DTC_CONT_HPWR_OOR_HI" 13692971 "DTC_CONT_HPWR_OOR_LO" 13635616 "DTC_5V_PWR_OOR_HI" 13635617 "DTC_5V_PWR_OOR_LO" 14606336 "DTC_NVM_WRITE_TO" 14606337 "DTC_NVM_READ_TO" 14614528 "DTC_SPI_DIG_POT_FAULT" ;
VAL_ 1120 bcm_dtc_087 0 " - " 11276288 "DTC_VEPO" 11276289 "DTC_HSC_MISSING" 11460608 "DTC_NVM_SOC" 11460609 "DTC_NVM_KOT" 11460610 "DTC_NVM_DTC" 11460611 "DTC_NVM_SOC_CORRECTION" 11460612 "DTC_NVM_APP_SCRATCHPAD" 11517962 "DTC_LOOPTIME_TASK_A" 11517963 "DTC_LOOPTIME_TASK_B" 11517964 "DTC_LOOPTIME_TASK_C" 11517965 "DTC_LOOPTIME_TASK_D" 11517966 "DTC_LOOPTIME_TASK_E" 11517967 "DTC_LOOPTIME_TASK_F" 11323904 "DTC_INTERLOCK_A_FAILED_LOW" 11323905 "DTC_INTERLOCK_A_FAILED_HIGH" 11324160 "DTC_INTERLOCK_B_FAILED_LOW" 11324161 "DTC_INTERLOCK_B_FAILED_HIGH" 15728640 "DTC_EPO" 16498688 "DTC_BRUSA_MISSING" 16498689 "DTC_BRUSA_IDC" 16498690 "DTC_BRUSA_REQ_VS_CMD" 16433152 "DTC_AKERWADE_MISSING" 16433153 "DTC_AKERWADE_IDC" 16433154 "DTC_AKERWADE_REQ_VS_CMD" 16564224 "DTC_CHGLEAR_MISSING" 16564225 "DTC_CHGLEAR_IDC" 16564226 "DTC_CHGLEAR_REQ_VS_CMD" 16522240 "DTC_CSM_MISSING" 16522752 "DTC_CSM_VBAT" 16522753 "DTC_CSM_VPOS" 16522754 "DTC_CSM_VNEG" 16522755 "DTC_CSM_CPOS" 16522756 "DTC_CSM_CNEG" 16522757 "DTC_CSM_APOS" 16522758 "DTC_CSM_ANEG" 16522759 "DTC_CSM_FUSE_HI" 16522760 "DTC_CSM_FUSE_LO" 16521728 "DTC_CSM_ASIC" 16521729 "DTC_CSM_AILO" 16521730 "DTC_CSM_AIHI" 16520957 "DTC_LEAKAGE_DETECT_FAULT" 16522444 "DTC_REALTIMECLOCK_FAULT" 16520945 "DTC_CSM_LEAK_FAIL_CALC" 16520946 "DTC_CSM_LEAK_FAIL_HW" 16520947 "DTC_CSM_LEAK_EXT_SHORT" 16520948 "DTC_CSM_LEAK_MID_PACK_SHORT" 16520949 "DTC_CSM_LEAK_ERROR" 16520950 "DTC_CSM_LEAK_UNKNOWN" 16523008 "DTC_CSM_VER_MISMATCH" 16523009 "DTC_CSM_DTC_SET" 16523010 "DTC_CSM_CAL_FAULT" 16560128 "DTC_IBAT_MISMATCH" 16576512 "DTC_DIS_MAX_I2T" 16576513 "DTC_CHG_MAX_I2T" 16576768 "DTC_DIS_WARNING_I2T" 16576769 "DTC_CHG_WARNING_I2T" 11296784 "DTC_SAEJ1772_PROX_DECT_OOR_HI" 11296785 "DTC_SAEJ1772_PROX_DECT_OOR_LO" 11296800 "DTC_SAEJ1772_PILOT_PWM_OOR_HI" 11296801 "DTC_SAEJ1772_PILOT_PWM_OOR_LO" 11296802 "DTC_SAEJ1772_PILOT_PWM_DIG_COMM" 11296803 "DTC_SAEJ1772_PILOT_PWM_IR_ERR" 16175360 "DTC_FGD1_NO_SENSOR" 16175361 "DTC_FGD1_OOR_HI" 16175362 "DTC_FGD1_OOR_LO" 16175363 "DTC_FGD1_FAULT" 16175616 "DTC_FGD2_NO_SENSOR" 16175617 "DTC_FGD2_OOR_HI" 16175618 "DTC_FGD2_OOR_LO" 16175619 "DTC_FGD2_FAULT" 16171008 "DTC_CONT_OPEN" 16171009 "DTC_CONT_CLOSE" 16171010 "DTC_CONT_OPEN_CURRENT" 16171264 "DTC_CONT_CLOSE_ON_RESET" 16171265 "DTC_CONT_CLOSE_SIG_FAILED" 16171520 "DTC_PRECHARGE_TIMEOUT" 16171777 "DTC_CONT_MPOS_WELD_AT_SU" 16171778 "DTC_CONT_MNEG_WELD_AT_SU" 16171780 "DTC_CONT_CPOS_WELD_AT_SU" 16171781 "DTC_CONT_CNEG_WELD_AT_SU" 16171782 "DTC_CONT_ANEG_WELD_AT_SU" 16171783 "DTC_CONT_APOS_WELD_AT_SU" 16172033 "DTC_CONT_MPOS_WELD_AT_SD" 16172034 "DTC_CONT_MNEG_WELD_AT_SD" 16172036 "DTC_CONT_CPOS_WELD_AT_SD" 16172037 "DTC_CONT_CNEG_WELD_AT_SD" 16172038 "DTC_CONT_ANEG_WELD_AT_SD" 16172039 "DTC_CONT_APOS_WELD_AT_SD" 16172289 "DTC_CONT_MPOS_OPEN" 16172290 "DTC_CONT_MNEG_OPEN" 16172291 "DTC_CONT_MPRE_OPEN" 16172292 "DTC_CONT_CPOS_OPEN" 16172293 "DTC_CONT_CNEG_OPEN" 16172294 "DTC_CONT_APOS_OPEN" 16172295 "DTC_CONT_ANEG_OPEN" 16172545 "DTC_CONT_MPOS_VDIF" 16172546 "DTC_CONT_MNEG_VDIF" 16172548 "DTC_CONT_CPOS_VDIF" 16172549 "DTC_CONT_CNEG_VDIF" 16172550 "DTC_CONT_APOS_VDIF" 16172551 "DTC_CONT_ANEG_VDIF" 16174848 "DTC_HVIL" 16174849 "DTC_LVBAT_LO" 16174850 "DTC_LVBAT_HI" 16174851 "DTC_LVBAT_ERR" 16523520 "DTC_LEMLO_OOR_HI" 16523521 "DTC_LEMLO_OOR_LO" 16523522 "DTC_LEMLO_FAULT" 16523776 "DTC_LEMHI_OOR_HI" 16523777 "DTC_LEMHI_OOR_LO" 16523778 "DTC_LEMHI_FAULT" 16496320 "DTC_MBB_TOO_FEW" 16496321 "DTC_MBB_TOO_MANY" 16496352 "DTC_CELL_VMAX_ERR" 16496353 "DTC_CELL_VMIN_ERR" 16496354 "DTC_CELL_VMAX" 16496362 "DTC_CELL_VMAX_SEVERE" 16496355 "DTC_CELL_VMIN" 16496363 "DTC_CELL_VMIN_SEVERE" 16496356 "DTC_MOD_VOLTAGE_COMPARE" 16496336 "DTC_CELL_T_ERR" 16496337 "DTC_CELL_TMAX1" 16496338 "DTC_CELL_TMAX2" 16496339 "DTC_CELL_TMIN" 16497665 "DTC_MBB_01_MISSING" 16497666 "DTC_MBB_02_MISSING" 16497667 "DTC_MBB_03_MISSING" 16497668 "DTC_MBB_04_MISSING" 16497669 "DTC_MBB_05_MISSING" 16497670 "DTC_MBB_06_MISSING" 16497671 "DTC_MBB_07_MISSING" 16497672 "DTC_MBB_08_MISSING" 16497673 "DTC_MBB_09_MISSING" 16497680 "DTC_MBB_10_MISSING" 16497681 "DTC_MBB_11_MISSING" 16497682 "DTC_MBB_12_MISSING" 16497683 "DTC_MBB_13_MISSING" 16497684 "DTC_MBB_14_MISSING" 16497685 "DTC_MBB_15_MISSING" 16497686 "DTC_MBB_16_MISSING" 16497687 "DTC_MBB_17_MISSING" 16497688 "DTC_MBB_18_MISSING" 16497689 "DTC_MBB_19_MISSING" 16497696 "DTC_MBB_20_MISSING" 16497697 "DTC_MBB_21_MISSING" 16497698 "DTC_MBB_22_MISSING" 16497699 "DTC_MBB_23_MISSING" 16497700 "DTC_MBB_24_MISSING" 16498177 "DTC_MBB_01_VFAULT" 16498178 "DTC_MBB_02_VFAULT" 16498179 "DTC_MBB_03_VFAULT" 16498180 "DTC_MBB_04_VFAULT" 16498181 "DTC_MBB_05_VFAULT" 16498182 "DTC_MBB_06_VFAULT" 16498183 "DTC_MBB_07_VFAULT" 16498184 "DTC_MBB_08_VFAULT" 16498185 "DTC_MBB_09_VFAULT" 16498192 "DTC_MBB_10_VFAULT" 16498193 "DTC_MBB_11_VFAULT" 16498194 "DTC_MBB_12_VFAULT" 16498195 "DTC_MBB_13_VFAULT" 16498196 "DTC_MBB_14_VFAULT" 16498197 "DTC_MBB_15_VFAULT" 16498198 "DTC_MBB_16_VFAULT" 16498199 "DTC_MBB_17_VFAULT" 16498200 "DTC_MBB_18_VFAULT" 16498201 "DTC_MBB_19_VFAULT" 16498208 "DTC_MBB_20_VFAULT" 16498209 "DTC_MBB_21_VFAULT" 16498210 "DTC_MBB_22_VFAULT" 16498211 "DTC_MBB_23_VFAULT" 16498212 "DTC_MBB_24_VFAULT" 16497921 "DTC_MBB_01_TFAULT" 16497922 "DTC_MBB_02_TFAULT" 16497923 "DTC_MBB_03_TFAULT" 16497924 "DTC_MBB_04_TFAULT" 16497925 "DTC_MBB_05_TFAULT" 16497926 "DTC_MBB_06_TFAULT" 16497927 "DTC_MBB_07_TFAULT" 16497928 "DTC_MBB_08_TFAULT" 16497929 "DTC_MBB_09_TFAULT" 16497936 "DTC_MBB_10_TFAULT" 16497937 "DTC_MBB_11_TFAULT" 16497938 "DTC_MBB_12_TFAULT" 16497939 "DTC_MBB_13_TFAULT" 16497940 "DTC_MBB_14_TFAULT" 16497941 "DTC_MBB_15_TFAULT" 16497942 "DTC_MBB_16_TFAULT" 16497943 "DTC_MBB_17_TFAULT" 16497944 "DTC_MBB_18_TFAULT" 16497945 "DTC_MBB_19_TFAULT" 16497952 "DTC_MBB_20_TFAULT" 16497953 "DTC_MBB_21_TFAULT" 16497954 "DTC_MBB_22_TFAULT" 16497955 "DTC_MBB_23_TFAULT" 16497956 "DTC_MBB_24_TFAULT" 15785984 "DTC_PRECHARGE_ENERGY" 15785985 "DTC_PRT_FAILED" 15785986 "DTC_PRT_OVERTEMP" 15785987 "DTC_PRT_PROHIBIT" 16556032 "DTC_COOLANT_TEMP_OOR_HI" 16556033 "DTC_COOLANT_TEMP_OOR_LO" 16252928 "DTC_KEY_OFF_TIME_ERROR" 16506880 "DTC_VBAT_MISMATCH" 16506881 "DTC_VBAT_VMAX" 16506882 "DTC_VBAT_VMIN" 16506883 "DTC_PACK_FUSE" 15798544 "DTC_LLS1_OOR_HI" 15798545 "DTC_LLS1_OOR_LO" 15798546 "DTC_LLS1_FAULT" 15798816 "DTC_LLS2_OOR_HI" 15798817 "DTC_LLS2_OOR_LO" 15798818 "DTC_LLS2_FAULT" 14479360 "DTC_CFL_HEARTBEAT" 14479361 "DTC_CFL_FAULT" 14479362 "DTC_CFL_FAULT_LATCH" 13635584 "DTC_CONT_A_FAILED_HI" 13635585 "DTC_CONT_A_FAILED_LO" 13635586 "DTC_CONT_B_FAILED_HI" 13635587 "DTC_CONT_B_FAILED_LO" 13635588 "DTC_CONT_C_FAILED_HI" 13635589 "DTC_CONT_C_FAILED_LO" 13635590 "DTC_CONT_D_FAILED_HI" 13635591 "DTC_CONT_D_FAILED_LO" 13635592 "DTC_CONT_E_FAILED_HI" 13635593 "DTC_CONT_E_FAILED_LO" 13635594 "DTC_CONT_F_FAILED_HI" 13635595 "DTC_CONT_F_FAILED_LO" 13635596 "DTC_CONT_G_FAILED_HI" 13635597 "DTC_CONT_G_FAILED_LO" 13635598 "DTC_LSD_A_FAILED_HI" 13635599 "DTC_LSD_A_FAILED_LO" 13635600 "DTC_LSD_B_FAILED_HI" 13635601 "DTC_LSD_B_FAILED_LO" 13635602 "DTC_LSD_C_FAILED_HI" 13635603 "DTC_LSD_C_FAILED_LO" 13635606 "DTC_CONT_PWR_FAILED_HI" 13635607 "DTC_CONT_PWR_FAILED_LO" 13635608 "DTC_LSD_PUMP_FAILED_HI" 13635609 "DTC_LSD_PUMP_FAILED_LO" 13635610 "DTC_CHG_A_ENABLE_FAILED_HI" 13635611 "DTC_CHG_A_ENABLE_FAILED_LO" 13635612 "DTC_CHG_B_ENABLE_FAILED_HI" 13635613 "DTC_CHG_B_ENABLE_FAILED_LO" 13635614 "DTC_SW14V_PWR_FAILED_HI" 13635615 "DTC_SW14V_PWR_FAILED_LO" 13635620 "DTC_HSD_A_FAILED_HI" 13635621 "DTC_HSD_A_FAILED_LO" 13635622 "DTC_HSD_B_FAILED_HI" 13635623 "DTC_HSD_B_FAILED_LO" 13692968 "DTC_CONT_HPWR_FAILED_HI" 13692969 "DTC_CONT_HPWR_FAILED_LO" 13692970 "DTC_CONT_HPWR_OOR_HI" 13692971 "DTC_CONT_HPWR_OOR_LO" 13635616 "DTC_5V_PWR_OOR_HI" 13635617 "DTC_5V_PWR_OOR_LO" 14606336 "DTC_NVM_WRITE_TO" 14606337 "DTC_NVM_READ_TO" 14614528 "DTC_SPI_DIG_POT_FAULT" ;
VAL_ 1120 bcm_dtc_088 0 " - " 11276288 "DTC_VEPO" 11276289 "DTC_HSC_MISSING" 11460608 "DTC_NVM_SOC" 11460609 "DTC_NVM_KOT" 11460610 "DTC_NVM_DTC" 11460611 "DTC_NVM_SOC_CORRECTION" 11460612 "DTC_NVM_APP_SCRATCHPAD" 11517962 "DTC_LOOPTIME_TASK_A" 11517963 "DTC_LOOPTIME_TASK_B" 11517964 "DTC_LOOPTIME_TASK_C" 11517965 "DTC_LOOPTIME_TASK_D" 11517966 "DTC_LOOPTIME_TASK_E" 11517967 "DTC_LOOPTIME_TASK_F" 11323904 "DTC_INTERLOCK_A_FAILED_LOW" 11323905 "DTC_INTERLOCK_A_FAILED_HIGH" 11324160 "DTC_INTERLOCK_B_FAILED_LOW" 11324161 "DTC_INTERLOCK_B_FAILED_HIGH" 15728640 "DTC_EPO" 16498688 "DTC_BRUSA_MISSING" 16498689 "DTC_BRUSA_IDC" 16498690 "DTC_BRUSA_REQ_VS_CMD" 16433152 "DTC_AKERWADE_MISSING" 16433153 "DTC_AKERWADE_IDC" 16433154 "DTC_AKERWADE_REQ_VS_CMD" 16564224 "DTC_CHGLEAR_MISSING" 16564225 "DTC_CHGLEAR_IDC" 16564226 "DTC_CHGLEAR_REQ_VS_CMD" 16522240 "DTC_CSM_MISSING" 16522752 "DTC_CSM_VBAT" 16522753 "DTC_CSM_VPOS" 16522754 "DTC_CSM_VNEG" 16522755 "DTC_CSM_CPOS" 16522756 "DTC_CSM_CNEG" 16522757 "DTC_CSM_APOS" 16522758 "DTC_CSM_ANEG" 16522759 "DTC_CSM_FUSE_HI" 16522760 "DTC_CSM_FUSE_LO" 16521728 "DTC_CSM_ASIC" 16521729 "DTC_CSM_AILO" 16521730 "DTC_CSM_AIHI" 16520957 "DTC_LEAKAGE_DETECT_FAULT" 16522444 "DTC_REALTIMECLOCK_FAULT" 16520945 "DTC_CSM_LEAK_FAIL_CALC" 16520946 "DTC_CSM_LEAK_FAIL_HW" 16520947 "DTC_CSM_LEAK_EXT_SHORT" 16520948 "DTC_CSM_LEAK_MID_PACK_SHORT" 16520949 "DTC_CSM_LEAK_ERROR" 16520950 "DTC_CSM_LEAK_UNKNOWN" 16523008 "DTC_CSM_VER_MISMATCH" 16523009 "DTC_CSM_DTC_SET" 16523010 "DTC_CSM_CAL_FAULT" 16560128 "DTC_IBAT_MISMATCH" 16576512 "DTC_DIS_MAX_I2T" 16576513 "DTC_CHG_MAX_I2T" 16576768 "DTC_DIS_WARNING_I2T" 16576769 "DTC_CHG_WARNING_I2T" 11296784 "DTC_SAEJ1772_PROX_DECT_OOR_HI" 11296785 "DTC_SAEJ1772_PROX_DECT_OOR_LO" 11296800 "DTC_SAEJ1772_PILOT_PWM_OOR_HI" 11296801 "DTC_SAEJ1772_PILOT_PWM_OOR_LO" 11296802 "DTC_SAEJ1772_PILOT_PWM_DIG_COMM" 11296803 "DTC_SAEJ1772_PILOT_PWM_IR_ERR" 16175360 "DTC_FGD1_NO_SENSOR" 16175361 "DTC_FGD1_OOR_HI" 16175362 "DTC_FGD1_OOR_LO" 16175363 "DTC_FGD1_FAULT" 16175616 "DTC_FGD2_NO_SENSOR" 16175617 "DTC_FGD2_OOR_HI" 16175618 "DTC_FGD2_OOR_LO" 16175619 "DTC_FGD2_FAULT" 16171008 "DTC_CONT_OPEN" 16171009 "DTC_CONT_CLOSE" 16171010 "DTC_CONT_OPEN_CURRENT" 16171264 "DTC_CONT_CLOSE_ON_RESET" 16171265 "DTC_CONT_CLOSE_SIG_FAILED" 16171520 "DTC_PRECHARGE_TIMEOUT" 16171777 "DTC_CONT_MPOS_WELD_AT_SU" 16171778 "DTC_CONT_MNEG_WELD_AT_SU" 16171780 "DTC_CONT_CPOS_WELD_AT_SU" 16171781 "DTC_CONT_CNEG_WELD_AT_SU" 16171782 "DTC_CONT_ANEG_WELD_AT_SU" 16171783 "DTC_CONT_APOS_WELD_AT_SU" 16172033 "DTC_CONT_MPOS_WELD_AT_SD" 16172034 "DTC_CONT_MNEG_WELD_AT_SD" 16172036 "DTC_CONT_CPOS_WELD_AT_SD" 16172037 "DTC_CONT_CNEG_WELD_AT_SD" 16172038 "DTC_CONT_ANEG_WELD_AT_SD" 16172039 "DTC_CONT_APOS_WELD_AT_SD" 16172289 "DTC_CONT_MPOS_OPEN" 16172290 "DTC_CONT_MNEG_OPEN" 16172291 "DTC_CONT_MPRE_OPEN" 16172292 "DTC_CONT_CPOS_OPEN" 16172293 "DTC_CONT_CNEG_OPEN" 16172294 "DTC_CONT_APOS_OPEN" 16172295 "DTC_CONT_ANEG_OPEN" 16172545 "DTC_CONT_MPOS_VDIF" 16172546 "DTC_CONT_MNEG_VDIF" 16172548 "DTC_CONT_CPOS_VDIF" 16172549 "DTC_CONT_CNEG_VDIF" 16172550 "DTC_CONT_APOS_VDIF" 16172551 "DTC_CONT_ANEG_VDIF" 16174848 "DTC_HVIL" 16174849 "DTC_LVBAT_LO" 16174850 "DTC_LVBAT_HI" 16174851 "DTC_LVBAT_ERR" 16523520 "DTC_LEMLO_OOR_HI" 16523521 "DTC_LEMLO_OOR_LO" 16523522 "DTC_LEMLO_FAULT" 16523776 "DTC_LEMHI_OOR_HI" 16523777 "DTC_LEMHI_OOR_LO" 16523778 "DTC_LEMHI_FAULT" 16496320 "DTC_MBB_TOO_FEW" 16496321 "DTC_MBB_TOO_MANY" 16496352 "DTC_CELL_VMAX_ERR" 16496353 "DTC_CELL_VMIN_ERR" 16496354 "DTC_CELL_VMAX" 16496362 "DTC_CELL_VMAX_SEVERE" 16496355 "DTC_CELL_VMIN" 16496363 "DTC_CELL_VMIN_SEVERE" 16496356 "DTC_MOD_VOLTAGE_COMPARE" 16496336 "DTC_CELL_T_ERR" 16496337 "DTC_CELL_TMAX1" 16496338 "DTC_CELL_TMAX2" 16496339 "DTC_CELL_TMIN" 16497665 "DTC_MBB_01_MISSING" 16497666 "DTC_MBB_02_MISSING" 16497667 "DTC_MBB_03_MISSING" 16497668 "DTC_MBB_04_MISSING" 16497669 "DTC_MBB_05_MISSING" 16497670 "DTC_MBB_06_MISSING" 16497671 "DTC_MBB_07_MISSING" 16497672 "DTC_MBB_08_MISSING" 16497673 "DTC_MBB_09_MISSING" 16497680 "DTC_MBB_10_MISSING" 16497681 "DTC_MBB_11_MISSING" 16497682 "DTC_MBB_12_MISSING" 16497683 "DTC_MBB_13_MISSING" 16497684 "DTC_MBB_14_MISSING" 16497685 "DTC_MBB_15_MISSING" 16497686 "DTC_MBB_16_MISSING" 16497687 "DTC_MBB_17_MISSING" 16497688 "DTC_MBB_18_MISSING" 16497689 "DTC_MBB_19_MISSING" 16497696 "DTC_MBB_20_MISSING" 16497697 "DTC_MBB_21_MISSING" 16497698 "DTC_MBB_22_MISSING" 16497699 "DTC_MBB_23_MISSING" 16497700 "DTC_MBB_24_MISSING" 16498177 "DTC_MBB_01_VFAULT" 16498178 "DTC_MBB_02_VFAULT" 16498179 "DTC_MBB_03_VFAULT" 16498180 "DTC_MBB_04_VFAULT" 16498181 "DTC_MBB_05_VFAULT" 16498182 "DTC_MBB_06_VFAULT" 16498183 "DTC_MBB_07_VFAULT" 16498184 "DTC_MBB_08_VFAULT" 16498185 "DTC_MBB_09_VFAULT" 16498192 "DTC_MBB_10_VFAULT" 16498193 "DTC_MBB_11_VFAULT" 16498194 "DTC_MBB_12_VFAULT" 16498195 "DTC_MBB_13_VFAULT" 16498196 "DTC_MBB_14_VFAULT" 16498197 "DTC_MBB_15_VFAULT" 16498198 "DTC_MBB_16_VFAULT" 16498199 "DTC_MBB_17_VFAULT" 16498200 "DTC_MBB_18_VFAULT" 16498201 "DTC_MBB_19_VFAULT" 16498208 "DTC_MBB_20_VFAULT" 16498209 "DTC_MBB_21_VFAULT" 16498210 "DTC_MBB_22_VFAULT" 16498211 "DTC_MBB_23_VFAULT" 16498212 "DTC_MBB_24_VFAULT" 16497921 "DTC_MBB_01_TFAULT" 16497922 "DTC_MBB_02_TFAULT" 16497923 "DTC_MBB_03_TFAULT" 16497924 "DTC_MBB_04_TFAULT" 16497925 "DTC_MBB_05_TFAULT" 16497926 "DTC_MBB_06_TFAULT" 16497927 "DTC_MBB_07_TFAULT" 16497928 "DTC_MBB_08_TFAULT" 16497929 "DTC_MBB_09_TFAULT" 16497936 "DTC_MBB_10_TFAULT" 16497937 "DTC_MBB_11_TFAULT" 16497938 "DTC_MBB_12_TFAULT" 16497939 "DTC_MBB_13_TFAULT" 16497940 "DTC_MBB_14_TFAULT" 16497941 "DTC_MBB_15_TFAULT" 16497942 "DTC_MBB_16_TFAULT" 16497943 "DTC_MBB_17_TFAULT" 16497944 "DTC_MBB_18_TFAULT" 16497945 "DTC_MBB_19_TFAULT" 16497952 "DTC_MBB_20_TFAULT" 16497953 "DTC_MBB_21_TFAULT" 16497954 "DTC_MBB_22_TFAULT" 16497955 "DTC_MBB_23_TFAULT" 16497956 "DTC_MBB_24_TFAULT" 15785984 "DTC_PRECHARGE_ENERGY" 15785985 "DTC_PRT_FAILED" 15785986 "DTC_PRT_OVERTEMP" 15785987 "DTC_PRT_PROHIBIT" 16556032 "DTC_COOLANT_TEMP_OOR_HI" 16556033 "DTC_COOLANT_TEMP_OOR_LO" 16252928 "DTC_KEY_OFF_TIME_ERROR" 16506880 "DTC_VBAT_MISMATCH" 16506881 "DTC_VBAT_VMAX" 16506882 "DTC_VBAT_VMIN" 16506883 "DTC_PACK_FUSE" 15798544 "DTC_LLS1_OOR_HI" 15798545 "DTC_LLS1_OOR_LO" 15798546 "DTC_LLS1_FAULT" 15798816 "DTC_LLS2_OOR_HI" 15798817 "DTC_LLS2_OOR_LO" 15798818 "DTC_LLS2_FAULT" 14479360 "DTC_CFL_HEARTBEAT" 14479361 "DTC_CFL_FAULT" 14479362 "DTC_CFL_FAULT_LATCH" 13635584 "DTC_CONT_A_FAILED_HI" 13635585 "DTC_CONT_A_FAILED_LO" 13635586 "DTC_CONT_B_FAILED_HI" 13635587 "DTC_CONT_B_FAILED_LO" 13635588 "DTC_CONT_C_FAILED_HI" 13635589 "DTC_CONT_C_FAILED_LO" 13635590 "DTC_CONT_D_FAILED_HI" 13635591 "DTC_CONT_D_FAILED_LO" 13635592 "DTC_CONT_E_FAILED_HI" 13635593 "DTC_CONT_E_FAILED_LO" 13635594 "DTC_CONT_F_FAILED_HI" 13635595 "DTC_CONT_F_FAILED_LO" 13635596 "DTC_CONT_G_FAILED_HI" 13635597 "DTC_CONT_G_FAILED_LO" 13635598 "DTC_LSD_A_FAILED_HI" 13635599 "DTC_LSD_A_FAILED_LO" 13635600 "DTC_LSD_B_FAILED_HI" 13635601 "DTC_LSD_B_FAILED_LO" 13635602 "DTC_LSD_C_FAILED_HI" 13635603 "DTC_LSD_C_FAILED_LO" 13635606 "DTC_CONT_PWR_FAILED_HI" 13635607 "DTC_CONT_PWR_FAILED_LO" 13635608 "DTC_LSD_PUMP_FAILED_HI" 13635609 "DTC_LSD_PUMP_FAILED_LO" 13635610 "DTC_CHG_A_ENABLE_FAILED_HI" 13635611 "DTC_CHG_A_ENABLE_FAILED_LO" 13635612 "DTC_CHG_B_ENABLE_FAILED_HI" 13635613 "DTC_CHG_B_ENABLE_FAILED_LO" 13635614 "DTC_SW14V_PWR_FAILED_HI" 13635615 "DTC_SW14V_PWR_FAILED_LO" 13635620 "DTC_HSD_A_FAILED_HI" 13635621 "DTC_HSD_A_FAILED_LO" 13635622 "DTC_HSD_B_FAILED_HI" 13635623 "DTC_HSD_B_FAILED_LO" 13692968 "DTC_CONT_HPWR_FAILED_HI" 13692969 "DTC_CONT_HPWR_FAILED_LO" 13692970 "DTC_CONT_HPWR_OOR_HI" 13692971 "DTC_CONT_HPWR_OOR_LO" 13635616 "DTC_5V_PWR_OOR_HI" 13635617 "DTC_5V_PWR_OOR_LO" 14606336 "DTC_NVM_WRITE_TO" 14606337 "DTC_NVM_READ_TO" 14614528 "DTC_SPI_DIG_POT_FAULT" ;
VAL_ 1120 bcm_dtc_089 0 " - " 11276288 "DTC_VEPO" 11276289 "DTC_HSC_MISSING" 11460608 "DTC_NVM_SOC" 11460609 "DTC_NVM_KOT" 11460610 "DTC_NVM_DTC" 11460611 "DTC_NVM_SOC_CORRECTION" 11460612 "DTC_NVM_APP_SCRATCHPAD" 11517962 "DTC_LOOPTIME_TASK_A" 11517963 "DTC_LOOPTIME_TASK_B" 11517964 "DTC_LOOPTIME_TASK_C" 11517965 "DTC_LOOPTIME_TASK_D" 11517966 "DTC_LOOPTIME_TASK_E" 11517967 "DTC_LOOPTIME_TASK_F" 11323904 "DTC_INTERLOCK_A_FAILED_LOW" 11323905 "DTC_INTERLOCK_A_FAILED_HIGH" 11324160 "DTC_INTERLOCK_B_FAILED_LOW" 11324161 "DTC_INTERLOCK_B_FAILED_HIGH" 15728640 "DTC_EPO" 16498688 "DTC_BRUSA_MISSING" 16498689 "DTC_BRUSA_IDC" 16498690 "DTC_BRUSA_REQ_VS_CMD" 16433152 "DTC_AKERWADE_MISSING" 16433153 "DTC_AKERWADE_IDC" 16433154 "DTC_AKERWADE_REQ_VS_CMD" 16564224 "DTC_CHGLEAR_MISSING" 16564225 "DTC_CHGLEAR_IDC" 16564226 "DTC_CHGLEAR_REQ_VS_CMD" 16522240 "DTC_CSM_MISSING" 16522752 "DTC_CSM_VBAT" 16522753 "DTC_CSM_VPOS" 16522754 "DTC_CSM_VNEG" 16522755 "DTC_CSM_CPOS" 16522756 "DTC_CSM_CNEG" 16522757 "DTC_CSM_APOS" 16522758 "DTC_CSM_ANEG" 16522759 "DTC_CSM_FUSE_HI" 16522760 "DTC_CSM_FUSE_LO" 16521728 "DTC_CSM_ASIC" 16521729 "DTC_CSM_AILO" 16521730 "DTC_CSM_AIHI" 16520957 "DTC_LEAKAGE_DETECT_FAULT" 16522444 "DTC_REALTIMECLOCK_FAULT" 16520945 "DTC_CSM_LEAK_FAIL_CALC" 16520946 "DTC_CSM_LEAK_FAIL_HW" 16520947 "DTC_CSM_LEAK_EXT_SHORT" 16520948 "DTC_CSM_LEAK_MID_PACK_SHORT" 16520949 "DTC_CSM_LEAK_ERROR" 16520950 "DTC_CSM_LEAK_UNKNOWN" 16523008 "DTC_CSM_VER_MISMATCH" 16523009 "DTC_CSM_DTC_SET" 16523010 "DTC_CSM_CAL_FAULT" 16560128 "DTC_IBAT_MISMATCH" 16576512 "DTC_DIS_MAX_I2T" 16576513 "DTC_CHG_MAX_I2T" 16576768 "DTC_DIS_WARNING_I2T" 16576769 "DTC_CHG_WARNING_I2T" 11296784 "DTC_SAEJ1772_PROX_DECT_OOR_HI" 11296785 "DTC_SAEJ1772_PROX_DECT_OOR_LO" 11296800 "DTC_SAEJ1772_PILOT_PWM_OOR_HI" 11296801 "DTC_SAEJ1772_PILOT_PWM_OOR_LO" 11296802 "DTC_SAEJ1772_PILOT_PWM_DIG_COMM" 11296803 "DTC_SAEJ1772_PILOT_PWM_IR_ERR" 16175360 "DTC_FGD1_NO_SENSOR" 16175361 "DTC_FGD1_OOR_HI" 16175362 "DTC_FGD1_OOR_LO" 16175363 "DTC_FGD1_FAULT" 16175616 "DTC_FGD2_NO_SENSOR" 16175617 "DTC_FGD2_OOR_HI" 16175618 "DTC_FGD2_OOR_LO" 16175619 "DTC_FGD2_FAULT" 16171008 "DTC_CONT_OPEN" 16171009 "DTC_CONT_CLOSE" 16171010 "DTC_CONT_OPEN_CURRENT" 16171264 "DTC_CONT_CLOSE_ON_RESET" 16171265 "DTC_CONT_CLOSE_SIG_FAILED" 16171520 "DTC_PRECHARGE_TIMEOUT" 16171777 "DTC_CONT_MPOS_WELD_AT_SU" 16171778 "DTC_CONT_MNEG_WELD_AT_SU" 16171780 "DTC_CONT_CPOS_WELD_AT_SU" 16171781 "DTC_CONT_CNEG_WELD_AT_SU" 16171782 "DTC_CONT_ANEG_WELD_AT_SU" 16171783 "DTC_CONT_APOS_WELD_AT_SU" 16172033 "DTC_CONT_MPOS_WELD_AT_SD" 16172034 "DTC_CONT_MNEG_WELD_AT_SD" 16172036 "DTC_CONT_CPOS_WELD_AT_SD" 16172037 "DTC_CONT_CNEG_WELD_AT_SD" 16172038 "DTC_CONT_ANEG_WELD_AT_SD" 16172039 "DTC_CONT_APOS_WELD_AT_SD" 16172289 "DTC_CONT_MPOS_OPEN" 16172290 "DTC_CONT_MNEG_OPEN" 16172291 "DTC_CONT_MPRE_OPEN" 16172292 "DTC_CONT_CPOS_OPEN" 16172293 "DTC_CONT_CNEG_OPEN" 16172294 "DTC_CONT_APOS_OPEN" 16172295 "DTC_CONT_ANEG_OPEN" 16172545 "DTC_CONT_MPOS_VDIF" 16172546 "DTC_CONT_MNEG_VDIF" 16172548 "DTC_CONT_CPOS_VDIF" 16172549 "DTC_CONT_CNEG_VDIF" 16172550 "DTC_CONT_APOS_VDIF" 16172551 "DTC_CONT_ANEG_VDIF" 16174848 "DTC_HVIL" 16174849 "DTC_LVBAT_LO" 16174850 "DTC_LVBAT_HI" 16174851 "DTC_LVBAT_ERR" 16523520 "DTC_LEMLO_OOR_HI" 16523521 "DTC_LEMLO_OOR_LO" 16523522 "DTC_LEMLO_FAULT" 16523776 "DTC_LEMHI_OOR_HI" 16523777 "DTC_LEMHI_OOR_LO" 16523778 "DTC_LEMHI_FAULT" 16496320 "DTC_MBB_TOO_FEW" 16496321 "DTC_MBB_TOO_MANY" 16496352 "DTC_CELL_VMAX_ERR" 16496353 "DTC_CELL_VMIN_ERR" 16496354 "DTC_CELL_VMAX" 16496362 "DTC_CELL_VMAX_SEVERE" 16496355 "DTC_CELL_VMIN" 16496363 "DTC_CELL_VMIN_SEVERE" 16496356 "DTC_MOD_VOLTAGE_COMPARE" 16496336 "DTC_CELL_T_ERR" 16496337 "DTC_CELL_TMAX1" 16496338 "DTC_CELL_TMAX2" 16496339 "DTC_CELL_TMIN" 16497665 "DTC_MBB_01_MISSING" 16497666 "DTC_MBB_02_MISSING" 16497667 "DTC_MBB_03_MISSING" 16497668 "DTC_MBB_04_MISSING" 16497669 "DTC_MBB_05_MISSING" 16497670 "DTC_MBB_06_MISSING" 16497671 "DTC_MBB_07_MISSING" 16497672 "DTC_MBB_08_MISSING" 16497673 "DTC_MBB_09_MISSING" 16497680 "DTC_MBB_10_MISSING" 16497681 "DTC_MBB_11_MISSING" 16497682 "DTC_MBB_12_MISSING" 16497683 "DTC_MBB_13_MISSING" 16497684 "DTC_MBB_14_MISSING" 16497685 "DTC_MBB_15_MISSING" 16497686 "DTC_MBB_16_MISSING" 16497687 "DTC_MBB_17_MISSING" 16497688 "DTC_MBB_18_MISSING" 16497689 "DTC_MBB_19_MISSING" 16497696 "DTC_MBB_20_MISSING" 16497697 "DTC_MBB_21_MISSING" 16497698 "DTC_MBB_22_MISSING" 16497699 "DTC_MBB_23_MISSING" 16497700 "DTC_MBB_24_MISSING" 16498177 "DTC_MBB_01_VFAULT" 16498178 "DTC_MBB_02_VFAULT" 16498179 "DTC_MBB_03_VFAULT" 16498180 "DTC_MBB_04_VFAULT" 16498181 "DTC_MBB_05_VFAULT" 16498182 "DTC_MBB_06_VFAULT" 16498183 "DTC_MBB_07_VFAULT" 16498184 "DTC_MBB_08_VFAULT" 16498185 "DTC_MBB_09_VFAULT" 16498192 "DTC_MBB_10_VFAULT" 16498193 "DTC_MBB_11_VFAULT" 16498194 "DTC_MBB_12_VFAULT" 16498195 "DTC_MBB_13_VFAULT" 16498196 "DTC_MBB_14_VFAULT" 16498197 "DTC_MBB_15_VFAULT" 16498198 "DTC_MBB_16_VFAULT" 16498199 "DTC_MBB_17_VFAULT" 16498200 "DTC_MBB_18_VFAULT" 16498201 "DTC_MBB_19_VFAULT" 16498208 "DTC_MBB_20_VFAULT" 16498209 "DTC_MBB_21_VFAULT" 16498210 "DTC_MBB_22_VFAULT" 16498211 "DTC_MBB_23_VFAULT" 16498212 "DTC_MBB_24_VFAULT" 16497921 "DTC_MBB_01_TFAULT" 16497922 "DTC_MBB_02_TFAULT" 16497923 "DTC_MBB_03_TFAULT" 16497924 "DTC_MBB_04_TFAULT" 16497925 "DTC_MBB_05_TFAULT" 16497926 "DTC_MBB_06_TFAULT" 16497927 "DTC_MBB_07_TFAULT" 16497928 "DTC_MBB_08_TFAULT" 16497929 "DTC_MBB_09_TFAULT" 16497936 "DTC_MBB_10_TFAULT" 16497937 "DTC_MBB_11_TFAULT" 16497938 "DTC_MBB_12_TFAULT" 16497939 "DTC_MBB_13_TFAULT" 16497940 "DTC_MBB_14_TFAULT" 16497941 "DTC_MBB_15_TFAULT" 16497942 "DTC_MBB_16_TFAULT" 16497943 "DTC_MBB_17_TFAULT" 16497944 "DTC_MBB_18_TFAULT" 16497945 "DTC_MBB_19_TFAULT" 16497952 "DTC_MBB_20_TFAULT" 16497953 "DTC_MBB_21_TFAULT" 16497954 "DTC_MBB_22_TFAULT" 16497955 "DTC_MBB_23_TFAULT" 16497956 "DTC_MBB_24_TFAULT" 15785984 "DTC_PRECHARGE_ENERGY" 15785985 "DTC_PRT_FAILED" 15785986 "DTC_PRT_OVERTEMP" 15785987 "DTC_PRT_PROHIBIT" 16556032 "DTC_COOLANT_TEMP_OOR_HI" 16556033 "DTC_COOLANT_TEMP_OOR_LO" 16252928 "DTC_KEY_OFF_TIME_ERROR" 16506880 "DTC_VBAT_MISMATCH" 16506881 "DTC_VBAT_VMAX" 16506882 "DTC_VBAT_VMIN" 16506883 "DTC_PACK_FUSE" 15798544 "DTC_LLS1_OOR_HI" 15798545 "DTC_LLS1_OOR_LO" 15798546 "DTC_LLS1_FAULT" 15798816 "DTC_LLS2_OOR_HI" 15798817 "DTC_LLS2_OOR_LO" 15798818 "DTC_LLS2_FAULT" 14479360 "DTC_CFL_HEARTBEAT" 14479361 "DTC_CFL_FAULT" 14479362 "DTC_CFL_FAULT_LATCH" 13635584 "DTC_CONT_A_FAILED_HI" 13635585 "DTC_CONT_A_FAILED_LO" 13635586 "DTC_CONT_B_FAILED_HI" 13635587 "DTC_CONT_B_FAILED_LO" 13635588 "DTC_CONT_C_FAILED_HI" 13635589 "DTC_CONT_C_FAILED_LO" 13635590 "DTC_CONT_D_FAILED_HI" 13635591 "DTC_CONT_D_FAILED_LO" 13635592 "DTC_CONT_E_FAILED_HI" 13635593 "DTC_CONT_E_FAILED_LO" 13635594 "DTC_CONT_F_FAILED_HI" 13635595 "DTC_CONT_F_FAILED_LO" 13635596 "DTC_CONT_G_FAILED_HI" 13635597 "DTC_CONT_G_FAILED_LO" 13635598 "DTC_LSD_A_FAILED_HI" 13635599 "DTC_LSD_A_FAILED_LO" 13635600 "DTC_LSD_B_FAILED_HI" 13635601 "DTC_LSD_B_FAILED_LO" 13635602 "DTC_LSD_C_FAILED_HI" 13635603 "DTC_LSD_C_FAILED_LO" 13635606 "DTC_CONT_PWR_FAILED_HI" 13635607 "DTC_CONT_PWR_FAILED_LO" 13635608 "DTC_LSD_PUMP_FAILED_HI" 13635609 "DTC_LSD_PUMP_FAILED_LO" 13635610 "DTC_CHG_A_ENABLE_FAILED_HI" 13635611 "DTC_CHG_A_ENABLE_FAILED_LO" 13635612 "DTC_CHG_B_ENABLE_FAILED_HI" 13635613 "DTC_CHG_B_ENABLE_FAILED_LO" 13635614 "DTC_SW14V_PWR_FAILED_HI" 13635615 "DTC_SW14V_PWR_FAILED_LO" 13635620 "DTC_HSD_A_FAILED_HI" 13635621 "DTC_HSD_A_FAILED_LO" 13635622 "DTC_HSD_B_FAILED_HI" 13635623 "DTC_HSD_B_FAILED_LO" 13692968 "DTC_CONT_HPWR_FAILED_HI" 13692969 "DTC_CONT_HPWR_FAILED_LO" 13692970 "DTC_CONT_HPWR_OOR_HI" 13692971 "DTC_CONT_HPWR_OOR_LO" 13635616 "DTC_5V_PWR_OOR_HI" 13635617 "DTC_5V_PWR_OOR_LO" 14606336 "DTC_NVM_WRITE_TO" 14606337 "DTC_NVM_READ_TO" 14614528 "DTC_SPI_DIG_POT_FAULT" ;
VAL_ 1120 bcm_dtc_090 0 " - " 11276288 "DTC_VEPO" 11276289 "DTC_HSC_MISSING" 11460608 "DTC_NVM_SOC" 11460609 "DTC_NVM_KOT" 11460610 "DTC_NVM_DTC" 11460611 "DTC_NVM_SOC_CORRECTION" 11460612 "DTC_NVM_APP_SCRATCHPAD" 11517962 "DTC_LOOPTIME_TASK_A" 11517963 "DTC_LOOPTIME_TASK_B" 11517964 "DTC_LOOPTIME_TASK_C" 11517965 "DTC_LOOPTIME_TASK_D" 11517966 "DTC_LOOPTIME_TASK_E" 11517967 "DTC_LOOPTIME_TASK_F" 11323904 "DTC_INTERLOCK_A_FAILED_LOW" 11323905 "DTC_INTERLOCK_A_FAILED_HIGH" 11324160 "DTC_INTERLOCK_B_FAILED_LOW" 11324161 "DTC_INTERLOCK_B_FAILED_HIGH" 15728640 "DTC_EPO" 16498688 "DTC_BRUSA_MISSING" 16498689 "DTC_BRUSA_IDC" 16498690 "DTC_BRUSA_REQ_VS_CMD" 16433152 "DTC_AKERWADE_MISSING" 16433153 "DTC_AKERWADE_IDC" 16433154 "DTC_AKERWADE_REQ_VS_CMD" 16564224 "DTC_CHGLEAR_MISSING" 16564225 "DTC_CHGLEAR_IDC" 16564226 "DTC_CHGLEAR_REQ_VS_CMD" 16522240 "DTC_CSM_MISSING" 16522752 "DTC_CSM_VBAT" 16522753 "DTC_CSM_VPOS" 16522754 "DTC_CSM_VNEG" 16522755 "DTC_CSM_CPOS" 16522756 "DTC_CSM_CNEG" 16522757 "DTC_CSM_APOS" 16522758 "DTC_CSM_ANEG" 16522759 "DTC_CSM_FUSE_HI" 16522760 "DTC_CSM_FUSE_LO" 16521728 "DTC_CSM_ASIC" 16521729 "DTC_CSM_AILO" 16521730 "DTC_CSM_AIHI" 16520957 "DTC_LEAKAGE_DETECT_FAULT" 16522444 "DTC_REALTIMECLOCK_FAULT" 16520945 "DTC_CSM_LEAK_FAIL_CALC" 16520946 "DTC_CSM_LEAK_FAIL_HW" 16520947 "DTC_CSM_LEAK_EXT_SHORT" 16520948 "DTC_CSM_LEAK_MID_PACK_SHORT" 16520949 "DTC_CSM_LEAK_ERROR" 16520950 "DTC_CSM_LEAK_UNKNOWN" 16523008 "DTC_CSM_VER_MISMATCH" 16523009 "DTC_CSM_DTC_SET" 16523010 "DTC_CSM_CAL_FAULT" 16560128 "DTC_IBAT_MISMATCH" 16576512 "DTC_DIS_MAX_I2T" 16576513 "DTC_CHG_MAX_I2T" 16576768 "DTC_DIS_WARNING_I2T" 16576769 "DTC_CHG_WARNING_I2T" 11296784 "DTC_SAEJ1772_PROX_DECT_OOR_HI" 11296785 "DTC_SAEJ1772_PROX_DECT_OOR_LO" 11296800 "DTC_SAEJ1772_PILOT_PWM_OOR_HI" 11296801 "DTC_SAEJ1772_PILOT_PWM_OOR_LO" 11296802 "DTC_SAEJ1772_PILOT_PWM_DIG_COMM" 11296803 "DTC_SAEJ1772_PILOT_PWM_IR_ERR" 16175360 "DTC_FGD1_NO_SENSOR" 16175361 "DTC_FGD1_OOR_HI" 16175362 "DTC_FGD1_OOR_LO" 16175363 "DTC_FGD1_FAULT" 16175616 "DTC_FGD2_NO_SENSOR" 16175617 "DTC_FGD2_OOR_HI" 16175618 "DTC_FGD2_OOR_LO" 16175619 "DTC_FGD2_FAULT" 16171008 "DTC_CONT_OPEN" 16171009 "DTC_CONT_CLOSE" 16171010 "DTC_CONT_OPEN_CURRENT" 16171264 "DTC_CONT_CLOSE_ON_RESET" 16171265 "DTC_CONT_CLOSE_SIG_FAILED" 16171520 "DTC_PRECHARGE_TIMEOUT" 16171777 "DTC_CONT_MPOS_WELD_AT_SU" 16171778 "DTC_CONT_MNEG_WELD_AT_SU" 16171780 "DTC_CONT_CPOS_WELD_AT_SU" 16171781 "DTC_CONT_CNEG_WELD_AT_SU" 16171782 "DTC_CONT_ANEG_WELD_AT_SU" 16171783 "DTC_CONT_APOS_WELD_AT_SU" 16172033 "DTC_CONT_MPOS_WELD_AT_SD" 16172034 "DTC_CONT_MNEG_WELD_AT_SD" 16172036 "DTC_CONT_CPOS_WELD_AT_SD" 16172037 "DTC_CONT_CNEG_WELD_AT_SD" 16172038 "DTC_CONT_ANEG_WELD_AT_SD" 16172039 "DTC_CONT_APOS_WELD_AT_SD" 16172289 "DTC_CONT_MPOS_OPEN" 16172290 "DTC_CONT_MNEG_OPEN" 16172291 "DTC_CONT_MPRE_OPEN" 16172292 "DTC_CONT_CPOS_OPEN" 16172293 "DTC_CONT_CNEG_OPEN" 16172294 "DTC_CONT_APOS_OPEN" 16172295 "DTC_CONT_ANEG_OPEN" 16172545 "DTC_CONT_MPOS_VDIF" 16172546 "DTC_CONT_MNEG_VDIF" 16172548 "DTC_CONT_CPOS_VDIF" 16172549 "DTC_CONT_CNEG_VDIF" 16172550 "DTC_CONT_APOS_VDIF" 16172551 "DTC_CONT_ANEG_VDIF" 16174848 "DTC_HVIL" 16174849 "DTC_LVBAT_LO" 16174850 "DTC_LVBAT_HI" 16174851 "DTC_LVBAT_ERR" 16523520 "DTC_LEMLO_OOR_HI" 16523521 "DTC_LEMLO_OOR_LO" 16523522 "DTC_LEMLO_FAULT" 16523776 "DTC_LEMHI_OOR_HI" 16523777 "DTC_LEMHI_OOR_LO" 16523778 "DTC_LEMHI_FAULT" 16496320 "DTC_MBB_TOO_FEW" 16496321 "DTC_MBB_TOO_MANY" 16496352 "DTC_CELL_VMAX_ERR" 16496353 "DTC_CELL_VMIN_ERR" 16496354 "DTC_CELL_VMAX" 16496362 "DTC_CELL_VMAX_SEVERE" 16496355 "DTC_CELL_VMIN" 16496363 "DTC_CELL_VMIN_SEVERE" 16496356 "DTC_MOD_VOLTAGE_COMPARE" 16496336 "DTC_CELL_T_ERR" 16496337 "DTC_CELL_TMAX1" 16496338 "DTC_CELL_TMAX2" 16496339 "DTC_CELL_TMIN" 16497665 "DTC_MBB_01_MISSING" 16497666 "DTC_MBB_02_MISSING" 16497667 "DTC_MBB_03_MISSING" 16497668 "DTC_MBB_04_MISSING" 16497669 "DTC_MBB_05_MISSING" 16497670 "DTC_MBB_06_MISSING" 16497671 "DTC_MBB_07_MISSING" 16497672 "DTC_MBB_08_MISSING" 16497673 "DTC_MBB_09_MISSING" 16497680 "DTC_MBB_10_MISSING" 16497681 "DTC_MBB_11_MISSING" 16497682 "DTC_MBB_12_MISSING" 16497683 "DTC_MBB_13_MISSING" 16497684 "DTC_MBB_14_MISSING" 16497685 "DTC_MBB_15_MISSING" 16497686 "DTC_MBB_16_MISSING" 16497687 "DTC_MBB_17_MISSING" 16497688 "DTC_MBB_18_MISSING" 16497689 "DTC_MBB_19_MISSING" 16497696 "DTC_MBB_20_MISSING" 16497697 "DTC_MBB_21_MISSING" 16497698 "DTC_MBB_22_MISSING" 16497699 "DTC_MBB_23_MISSING" 16497700 "DTC_MBB_24_MISSING" 16498177 "DTC_MBB_01_VFAULT" 16498178 "DTC_MBB_02_VFAULT" 16498179 "DTC_MBB_03_VFAULT" 16498180 "DTC_MBB_04_VFAULT" 16498181 "DTC_MBB_05_VFAULT" 16498182 "DTC_MBB_06_VFAULT" 16498183 "DTC_MBB_07_VFAULT" 16498184 "DTC_MBB_08_VFAULT" 16498185 "DTC_MBB_09_VFAULT" 16498192 "DTC_MBB_10_VFAULT" 16498193 "DTC_MBB_11_VFAULT" 16498194 "DTC_MBB_12_VFAULT" 16498195 "DTC_MBB_13_VFAULT" 16498196 "DTC_MBB_14_VFAULT" 16498197 "DTC_MBB_15_VFAULT" 16498198 "DTC_MBB_16_VFAULT" 16498199 "DTC_MBB_17_VFAULT" 16498200 "DTC_MBB_18_VFAULT" 16498201 "DTC_MBB_19_VFAULT" 16498208 "DTC_MBB_20_VFAULT" 16498209 "DTC_MBB_21_VFAULT" 16498210 "DTC_MBB_22_VFAULT" 16498211 "DTC_MBB_23_VFAULT" 16498212 "DTC_MBB_24_VFAULT" 16497921 "DTC_MBB_01_TFAULT" 16497922 "DTC_MBB_02_TFAULT" 16497923 "DTC_MBB_03_TFAULT" 16497924 "DTC_MBB_04_TFAULT" 16497925 "DTC_MBB_05_TFAULT" 16497926 "DTC_MBB_06_TFAULT" 16497927 "DTC_MBB_07_TFAULT" 16497928 "DTC_MBB_08_TFAULT" 16497929 "DTC_MBB_09_TFAULT" 16497936 "DTC_MBB_10_TFAULT" 16497937 "DTC_MBB_11_TFAULT" 16497938 "DTC_MBB_12_TFAULT" 16497939 "DTC_MBB_13_TFAULT" 16497940 "DTC_MBB_14_TFAULT" 16497941 "DTC_MBB_15_TFAULT" 16497942 "DTC_MBB_16_TFAULT" 16497943 "DTC_MBB_17_TFAULT" 16497944 "DTC_MBB_18_TFAULT" 16497945 "DTC_MBB_19_TFAULT" 16497952 "DTC_MBB_20_TFAULT" 16497953 "DTC_MBB_21_TFAULT" 16497954 "DTC_MBB_22_TFAULT" 16497955 "DTC_MBB_23_TFAULT" 16497956 "DTC_MBB_24_TFAULT" 15785984 "DTC_PRECHARGE_ENERGY" 15785985 "DTC_PRT_FAILED" 15785986 "DTC_PRT_OVERTEMP" 15785987 "DTC_PRT_PROHIBIT" 16556032 "DTC_COOLANT_TEMP_OOR_HI" 16556033 "DTC_COOLANT_TEMP_OOR_LO" 16252928 "DTC_KEY_OFF_TIME_ERROR" 16506880 "DTC_VBAT_MISMATCH" 16506881 "DTC_VBAT_VMAX" 16506882 "DTC_VBAT_VMIN" 16506883 "DTC_PACK_FUSE" 15798544 "DTC_LLS1_OOR_HI" 15798545 "DTC_LLS1_OOR_LO" 15798546 "DTC_LLS1_FAULT" 15798816 "DTC_LLS2_OOR_HI" 15798817 "DTC_LLS2_OOR_LO" 15798818 "DTC_LLS2_FAULT" 14479360 "DTC_CFL_HEARTBEAT" 14479361 "DTC_CFL_FAULT" 14479362 "DTC_CFL_FAULT_LATCH" 13635584 "DTC_CONT_A_FAILED_HI" 13635585 "DTC_CONT_A_FAILED_LO" 13635586 "DTC_CONT_B_FAILED_HI" 13635587 "DTC_CONT_B_FAILED_LO" 13635588 "DTC_CONT_C_FAILED_HI" 13635589 "DTC_CONT_C_FAILED_LO" 13635590 "DTC_CONT_D_FAILED_HI" 13635591 "DTC_CONT_D_FAILED_LO" 13635592 "DTC_CONT_E_FAILED_HI" 13635593 "DTC_CONT_E_FAILED_LO" 13635594 "DTC_CONT_F_FAILED_HI" 13635595 "DTC_CONT_F_FAILED_LO" 13635596 "DTC_CONT_G_FAILED_HI" 13635597 "DTC_CONT_G_FAILED_LO" 13635598 "DTC_LSD_A_FAILED_HI" 13635599 "DTC_LSD_A_FAILED_LO" 13635600 "DTC_LSD_B_FAILED_HI" 13635601 "DTC_LSD_B_FAILED_LO" 13635602 "DTC_LSD_C_FAILED_HI" 13635603 "DTC_LSD_C_FAILED_LO" 13635606 "DTC_CONT_PWR_FAILED_HI" 13635607 "DTC_CONT_PWR_FAILED_LO" 13635608 "DTC_LSD_PUMP_FAILED_HI" 13635609 "DTC_LSD_PUMP_FAILED_LO" 13635610 "DTC_CHG_A_ENABLE_FAILED_HI" 13635611 "DTC_CHG_A_ENABLE_FAILED_LO" 13635612 "DTC_CHG_B_ENABLE_FAILED_HI" 13635613 "DTC_CHG_B_ENABLE_FAILED_LO" 13635614 "DTC_SW14V_PWR_FAILED_HI" 13635615 "DTC_SW14V_PWR_FAILED_LO" 13635620 "DTC_HSD_A_FAILED_HI" 13635621 "DTC_HSD_A_FAILED_LO" 13635622 "DTC_HSD_B_FAILED_HI" 13635623 "DTC_HSD_B_FAILED_LO" 13692968 "DTC_CONT_HPWR_FAILED_HI" 13692969 "DTC_CONT_HPWR_FAILED_LO" 13692970 "DTC_CONT_HPWR_OOR_HI" 13692971 "DTC_CONT_HPWR_OOR_LO" 13635616 "DTC_5V_PWR_OOR_HI" 13635617 "DTC_5V_PWR_OOR_LO" 14606336 "DTC_NVM_WRITE_TO" 14606337 "DTC_NVM_READ_TO" 14614528 "DTC_SPI_DIG_POT_FAULT" ;
VAL_ 1120 bcm_dtc_091 0 " - " 11276288 "DTC_VEPO" 11276289 "DTC_HSC_MISSING" 11460608 "DTC_NVM_SOC" 11460609 "DTC_NVM_KOT" 11460610 "DTC_NVM_DTC" 11460611 "DTC_NVM_SOC_CORRECTION" 11460612 "DTC_NVM_APP_SCRATCHPAD" 11517962 "DTC_LOOPTIME_TASK_A" 11517963 "DTC_LOOPTIME_TASK_B" 11517964 "DTC_LOOPTIME_TASK_C" 11517965 "DTC_LOOPTIME_TASK_D" 11517966 "DTC_LOOPTIME_TASK_E" 11517967 "DTC_LOOPTIME_TASK_F" 11323904 "DTC_INTERLOCK_A_FAILED_LOW" 11323905 "DTC_INTERLOCK_A_FAILED_HIGH" 11324160 "DTC_INTERLOCK_B_FAILED_LOW" 11324161 "DTC_INTERLOCK_B_FAILED_HIGH" 15728640 "DTC_EPO" 16498688 "DTC_BRUSA_MISSING" 16498689 "DTC_BRUSA_IDC" 16498690 "DTC_BRUSA_REQ_VS_CMD" 16433152 "DTC_AKERWADE_MISSING" 16433153 "DTC_AKERWADE_IDC" 16433154 "DTC_AKERWADE_REQ_VS_CMD" 16564224 "DTC_CHGLEAR_MISSING" 16564225 "DTC_CHGLEAR_IDC" 16564226 "DTC_CHGLEAR_REQ_VS_CMD" 16522240 "DTC_CSM_MISSING" 16522752 "DTC_CSM_VBAT" 16522753 "DTC_CSM_VPOS" 16522754 "DTC_CSM_VNEG" 16522755 "DTC_CSM_CPOS" 16522756 "DTC_CSM_CNEG" 16522757 "DTC_CSM_APOS" 16522758 "DTC_CSM_ANEG" 16522759 "DTC_CSM_FUSE_HI" 16522760 "DTC_CSM_FUSE_LO" 16521728 "DTC_CSM_ASIC" 16521729 "DTC_CSM_AILO" 16521730 "DTC_CSM_AIHI" 16520957 "DTC_LEAKAGE_DETECT_FAULT" 16522444 "DTC_REALTIMECLOCK_FAULT" 16520945 "DTC_CSM_LEAK_FAIL_CALC" 16520946 "DTC_CSM_LEAK_FAIL_HW" 16520947 "DTC_CSM_LEAK_EXT_SHORT" 16520948 "DTC_CSM_LEAK_MID_PACK_SHORT" 16520949 "DTC_CSM_LEAK_ERROR" 16520950 "DTC_CSM_LEAK_UNKNOWN" 16523008 "DTC_CSM_VER_MISMATCH" 16523009 "DTC_CSM_DTC_SET" 16523010 "DTC_CSM_CAL_FAULT" 16560128 "DTC_IBAT_MISMATCH" 16576512 "DTC_DIS_MAX_I2T" 16576513 "DTC_CHG_MAX_I2T" 16576768 "DTC_DIS_WARNING_I2T" 16576769 "DTC_CHG_WARNING_I2T" 11296784 "DTC_SAEJ1772_PROX_DECT_OOR_HI" 11296785 "DTC_SAEJ1772_PROX_DECT_OOR_LO" 11296800 "DTC_SAEJ1772_PILOT_PWM_OOR_HI" 11296801 "DTC_SAEJ1772_PILOT_PWM_OOR_LO" 11296802 "DTC_SAEJ1772_PILOT_PWM_DIG_COMM" 11296803 "DTC_SAEJ1772_PILOT_PWM_IR_ERR" 16175360 "DTC_FGD1_NO_SENSOR" 16175361 "DTC_FGD1_OOR_HI" 16175362 "DTC_FGD1_OOR_LO" 16175363 "DTC_FGD1_FAULT" 16175616 "DTC_FGD2_NO_SENSOR" 16175617 "DTC_FGD2_OOR_HI" 16175618 "DTC_FGD2_OOR_LO" 16175619 "DTC_FGD2_FAULT" 16171008 "DTC_CONT_OPEN" 16171009 "DTC_CONT_CLOSE" 16171010 "DTC_CONT_OPEN_CURRENT" 16171264 "DTC_CONT_CLOSE_ON_RESET" 16171265 "DTC_CONT_CLOSE_SIG_FAILED" 16171520 "DTC_PRECHARGE_TIMEOUT" 16171777 "DTC_CONT_MPOS_WELD_AT_SU" 16171778 "DTC_CONT_MNEG_WELD_AT_SU" 16171780 "DTC_CONT_CPOS_WELD_AT_SU" 16171781 "DTC_CONT_CNEG_WELD_AT_SU" 16171782 "DTC_CONT_ANEG_WELD_AT_SU" 16171783 "DTC_CONT_APOS_WELD_AT_SU" 16172033 "DTC_CONT_MPOS_WELD_AT_SD" 16172034 "DTC_CONT_MNEG_WELD_AT_SD" 16172036 "DTC_CONT_CPOS_WELD_AT_SD" 16172037 "DTC_CONT_CNEG_WELD_AT_SD" 16172038 "DTC_CONT_ANEG_WELD_AT_SD" 16172039 "DTC_CONT_APOS_WELD_AT_SD" 16172289 "DTC_CONT_MPOS_OPEN" 16172290 "DTC_CONT_MNEG_OPEN" 16172291 "DTC_CONT_MPRE_OPEN" 16172292 "DTC_CONT_CPOS_OPEN" 16172293 "DTC_CONT_CNEG_OPEN" 16172294 "DTC_CONT_APOS_OPEN" 16172295 "DTC_CONT_ANEG_OPEN" 16172545 "DTC_CONT_MPOS_VDIF" 16172546 "DTC_CONT_MNEG_VDIF" 16172548 "DTC_CONT_CPOS_VDIF" 16172549 "DTC_CONT_CNEG_VDIF" 16172550 "DTC_CONT_APOS_VDIF" 16172551 "DTC_CONT_ANEG_VDIF" 16174848 "DTC_HVIL" 16174849 "DTC_LVBAT_LO" 16174850 "DTC_LVBAT_HI" 16174851 "DTC_LVBAT_ERR" 16523520 "DTC_LEMLO_OOR_HI" 16523521 "DTC_LEMLO_OOR_LO" 16523522 "DTC_LEMLO_FAULT" 16523776 "DTC_LEMHI_OOR_HI" 16523777 "DTC_LEMHI_OOR_LO" 16523778 "DTC_LEMHI_FAULT" 16496320 "DTC_MBB_TOO_FEW" 16496321 "DTC_MBB_TOO_MANY" 16496352 "DTC_CELL_VMAX_ERR" 16496353 "DTC_CELL_VMIN_ERR" 16496354 "DTC_CELL_VMAX" 16496362 "DTC_CELL_VMAX_SEVERE" 16496355 "DTC_CELL_VMIN" 16496363 "DTC_CELL_VMIN_SEVERE" 16496356 "DTC_MOD_VOLTAGE_COMPARE" 16496336 "DTC_CELL_T_ERR" 16496337 "DTC_CELL_TMAX1" 16496338 "DTC_CELL_TMAX2" 16496339 "DTC_CELL_TMIN" 16497665 "DTC_MBB_01_MISSING" 16497666 "DTC_MBB_02_MISSING" 16497667 "DTC_MBB_03_MISSING" 16497668 "DTC_MBB_04_MISSING" 16497669 "DTC_MBB_05_MISSING" 16497670 "DTC_MBB_06_MISSING" 16497671 "DTC_MBB_07_MISSING" 16497672 "DTC_MBB_08_MISSING" 16497673 "DTC_MBB_09_MISSING" 16497680 "DTC_MBB_10_MISSING" 16497681 "DTC_MBB_11_MISSING" 16497682 "DTC_MBB_12_MISSING" 16497683 "DTC_MBB_13_MISSING" 16497684 "DTC_MBB_14_MISSING" 16497685 "DTC_MBB_15_MISSING" 16497686 "DTC_MBB_16_MISSING" 16497687 "DTC_MBB_17_MISSING" 16497688 "DTC_MBB_18_MISSING" 16497689 "DTC_MBB_19_MISSING" 16497696 "DTC_MBB_20_MISSING" 16497697 "DTC_MBB_21_MISSING" 16497698 "DTC_MBB_22_MISSING" 16497699 "DTC_MBB_23_MISSING" 16497700 "DTC_MBB_24_MISSING" 16498177 "DTC_MBB_01_VFAULT" 16498178 "DTC_MBB_02_VFAULT" 16498179 "DTC_MBB_03_VFAULT" 16498180 "DTC_MBB_04_VFAULT" 16498181 "DTC_MBB_05_VFAULT" 16498182 "DTC_MBB_06_VFAULT" 16498183 "DTC_MBB_07_VFAULT" 16498184 "DTC_MBB_08_VFAULT" 16498185 "DTC_MBB_09_VFAULT" 16498192 "DTC_MBB_10_VFAULT" 16498193 "DTC_MBB_11_VFAULT" 16498194 "DTC_MBB_12_VFAULT" 16498195 "DTC_MBB_13_VFAULT" 16498196 "DTC_MBB_14_VFAULT" 16498197 "DTC_MBB_15_VFAULT" 16498198 "DTC_MBB_16_VFAULT" 16498199 "DTC_MBB_17_VFAULT" 16498200 "DTC_MBB_18_VFAULT" 16498201 "DTC_MBB_19_VFAULT" 16498208 "DTC_MBB_20_VFAULT" 16498209 "DTC_MBB_21_VFAULT" 16498210 "DTC_MBB_22_VFAULT" 16498211 "DTC_MBB_23_VFAULT" 16498212 "DTC_MBB_24_VFAULT" 16497921 "DTC_MBB_01_TFAULT" 16497922 "DTC_MBB_02_TFAULT" 16497923 "DTC_MBB_03_TFAULT" 16497924 "DTC_MBB_04_TFAULT" 16497925 "DTC_MBB_05_TFAULT" 16497926 "DTC_MBB_06_TFAULT" 16497927 "DTC_MBB_07_TFAULT" 16497928 "DTC_MBB_08_TFAULT" 16497929 "DTC_MBB_09_TFAULT" 16497936 "DTC_MBB_10_TFAULT" 16497937 "DTC_MBB_11_TFAULT" 16497938 "DTC_MBB_12_TFAULT" 16497939 "DTC_MBB_13_TFAULT" 16497940 "DTC_MBB_14_TFAULT" 16497941 "DTC_MBB_15_TFAULT" 16497942 "DTC_MBB_16_TFAULT" 16497943 "DTC_MBB_17_TFAULT" 16497944 "DTC_MBB_18_TFAULT" 16497945 "DTC_MBB_19_TFAULT" 16497952 "DTC_MBB_20_TFAULT" 16497953 "DTC_MBB_21_TFAULT" 16497954 "DTC_MBB_22_TFAULT" 16497955 "DTC_MBB_23_TFAULT" 16497956 "DTC_MBB_24_TFAULT" 15785984 "DTC_PRECHARGE_ENERGY" 15785985 "DTC_PRT_FAILED" 15785986 "DTC_PRT_OVERTEMP" 15785987 "DTC_PRT_PROHIBIT" 16556032 "DTC_COOLANT_TEMP_OOR_HI" 16556033 "DTC_COOLANT_TEMP_OOR_LO" 16252928 "DTC_KEY_OFF_TIME_ERROR" 16506880 "DTC_VBAT_MISMATCH" 16506881 "DTC_VBAT_VMAX" 16506882 "DTC_VBAT_VMIN" 16506883 "DTC_PACK_FUSE" 15798544 "DTC_LLS1_OOR_HI" 15798545 "DTC_LLS1_OOR_LO" 15798546 "DTC_LLS1_FAULT" 15798816 "DTC_LLS2_OOR_HI" 15798817 "DTC_LLS2_OOR_LO" 15798818 "DTC_LLS2_FAULT" 14479360 "DTC_CFL_HEARTBEAT" 14479361 "DTC_CFL_FAULT" 14479362 "DTC_CFL_FAULT_LATCH" 13635584 "DTC_CONT_A_FAILED_HI" 13635585 "DTC_CONT_A_FAILED_LO" 13635586 "DTC_CONT_B_FAILED_HI" 13635587 "DTC_CONT_B_FAILED_LO" 13635588 "DTC_CONT_C_FAILED_HI" 13635589 "DTC_CONT_C_FAILED_LO" 13635590 "DTC_CONT_D_FAILED_HI" 13635591 "DTC_CONT_D_FAILED_LO" 13635592 "DTC_CONT_E_FAILED_HI" 13635593 "DTC_CONT_E_FAILED_LO" 13635594 "DTC_CONT_F_FAILED_HI" 13635595 "DTC_CONT_F_FAILED_LO" 13635596 "DTC_CONT_G_FAILED_HI" 13635597 "DTC_CONT_G_FAILED_LO" 13635598 "DTC_LSD_A_FAILED_HI" 13635599 "DTC_LSD_A_FAILED_LO" 13635600 "DTC_LSD_B_FAILED_HI" 13635601 "DTC_LSD_B_FAILED_LO" 13635602 "DTC_LSD_C_FAILED_HI" 13635603 "DTC_LSD_C_FAILED_LO" 13635606 "DTC_CONT_PWR_FAILED_HI" 13635607 "DTC_CONT_PWR_FAILED_LO" 13635608 "DTC_LSD_PUMP_FAILED_HI" 13635609 "DTC_LSD_PUMP_FAILED_LO" 13635610 "DTC_CHG_A_ENABLE_FAILED_HI" 13635611 "DTC_CHG_A_ENABLE_FAILED_LO" 13635612 "DTC_CHG_B_ENABLE_FAILED_HI" 13635613 "DTC_CHG_B_ENABLE_FAILED_LO" 13635614 "DTC_SW14V_PWR_FAILED_HI" 13635615 "DTC_SW14V_PWR_FAILED_LO" 13635620 "DTC_HSD_A_FAILED_HI" 13635621 "DTC_HSD_A_FAILED_LO" 13635622 "DTC_HSD_B_FAILED_HI" 13635623 "DTC_HSD_B_FAILED_LO" 13692968 "DTC_CONT_HPWR_FAILED_HI" 13692969 "DTC_CONT_HPWR_FAILED_LO" 13692970 "DTC_CONT_HPWR_OOR_HI" 13692971 "DTC_CONT_HPWR_OOR_LO" 13635616 "DTC_5V_PWR_OOR_HI" 13635617 "DTC_5V_PWR_OOR_LO" 14606336 "DTC_NVM_WRITE_TO" 14606337 "DTC_NVM_READ_TO" 14614528 "DTC_SPI_DIG_POT_FAULT" ;
VAL_ 1120 bcm_dtc_092 0 " - " 11276288 "DTC_VEPO" 11276289 "DTC_HSC_MISSING" 11460608 "DTC_NVM_SOC" 11460609 "DTC_NVM_KOT" 11460610 "DTC_NVM_DTC" 11460611 "DTC_NVM_SOC_CORRECTION" 11460612 "DTC_NVM_APP_SCRATCHPAD" 11517962 "DTC_LOOPTIME_TASK_A" 11517963 "DTC_LOOPTIME_TASK_B" 11517964 "DTC_LOOPTIME_TASK_C" 11517965 "DTC_LOOPTIME_TASK_D" 11517966 "DTC_LOOPTIME_TASK_E" 11517967 "DTC_LOOPTIME_TASK_F" 11323904 "DTC_INTERLOCK_A_FAILED_LOW" 11323905 "DTC_INTERLOCK_A_FAILED_HIGH" 11324160 "DTC_INTERLOCK_B_FAILED_LOW" 11324161 "DTC_INTERLOCK_B_FAILED_HIGH" 15728640 "DTC_EPO" 16498688 "DTC_BRUSA_MISSING" 16498689 "DTC_BRUSA_IDC" 16498690 "DTC_BRUSA_REQ_VS_CMD" 16433152 "DTC_AKERWADE_MISSING" 16433153 "DTC_AKERWADE_IDC" 16433154 "DTC_AKERWADE_REQ_VS_CMD" 16564224 "DTC_CHGLEAR_MISSING" 16564225 "DTC_CHGLEAR_IDC" 16564226 "DTC_CHGLEAR_REQ_VS_CMD" 16522240 "DTC_CSM_MISSING" 16522752 "DTC_CSM_VBAT" 16522753 "DTC_CSM_VPOS" 16522754 "DTC_CSM_VNEG" 16522755 "DTC_CSM_CPOS" 16522756 "DTC_CSM_CNEG" 16522757 "DTC_CSM_APOS" 16522758 "DTC_CSM_ANEG" 16522759 "DTC_CSM_FUSE_HI" 16522760 "DTC_CSM_FUSE_LO" 16521728 "DTC_CSM_ASIC" 16521729 "DTC_CSM_AILO" 16521730 "DTC_CSM_AIHI" 16520957 "DTC_LEAKAGE_DETECT_FAULT" 16522444 "DTC_REALTIMECLOCK_FAULT" 16520945 "DTC_CSM_LEAK_FAIL_CALC" 16520946 "DTC_CSM_LEAK_FAIL_HW" 16520947 "DTC_CSM_LEAK_EXT_SHORT" 16520948 "DTC_CSM_LEAK_MID_PACK_SHORT" 16520949 "DTC_CSM_LEAK_ERROR" 16520950 "DTC_CSM_LEAK_UNKNOWN" 16523008 "DTC_CSM_VER_MISMATCH" 16523009 "DTC_CSM_DTC_SET" 16523010 "DTC_CSM_CAL_FAULT" 16560128 "DTC_IBAT_MISMATCH" 16576512 "DTC_DIS_MAX_I2T" 16576513 "DTC_CHG_MAX_I2T" 16576768 "DTC_DIS_WARNING_I2T" 16576769 "DTC_CHG_WARNING_I2T" 11296784 "DTC_SAEJ1772_PROX_DECT_OOR_HI" 11296785 "DTC_SAEJ1772_PROX_DECT_OOR_LO" 11296800 "DTC_SAEJ1772_PILOT_PWM_OOR_HI" 11296801 "DTC_SAEJ1772_PILOT_PWM_OOR_LO" 11296802 "DTC_SAEJ1772_PILOT_PWM_DIG_COMM" 11296803 "DTC_SAEJ1772_PILOT_PWM_IR_ERR" 16175360 "DTC_FGD1_NO_SENSOR" 16175361 "DTC_FGD1_OOR_HI" 16175362 "DTC_FGD1_OOR_LO" 16175363 "DTC_FGD1_FAULT" 16175616 "DTC_FGD2_NO_SENSOR" 16175617 "DTC_FGD2_OOR_HI" 16175618 "DTC_FGD2_OOR_LO" 16175619 "DTC_FGD2_FAULT" 16171008 "DTC_CONT_OPEN" 16171009 "DTC_CONT_CLOSE" 16171010 "DTC_CONT_OPEN_CURRENT" 16171264 "DTC_CONT_CLOSE_ON_RESET" 16171265 "DTC_CONT_CLOSE_SIG_FAILED" 16171520 "DTC_PRECHARGE_TIMEOUT" 16171777 "DTC_CONT_MPOS_WELD_AT_SU" 16171778 "DTC_CONT_MNEG_WELD_AT_SU" 16171780 "DTC_CONT_CPOS_WELD_AT_SU" 16171781 "DTC_CONT_CNEG_WELD_AT_SU" 16171782 "DTC_CONT_ANEG_WELD_AT_SU" 16171783 "DTC_CONT_APOS_WELD_AT_SU" 16172033 "DTC_CONT_MPOS_WELD_AT_SD" 16172034 "DTC_CONT_MNEG_WELD_AT_SD" 16172036 "DTC_CONT_CPOS_WELD_AT_SD" 16172037 "DTC_CONT_CNEG_WELD_AT_SD" 16172038 "DTC_CONT_ANEG_WELD_AT_SD" 16172039 "DTC_CONT_APOS_WELD_AT_SD" 16172289 "DTC_CONT_MPOS_OPEN" 16172290 "DTC_CONT_MNEG_OPEN" 16172291 "DTC_CONT_MPRE_OPEN" 16172292 "DTC_CONT_CPOS_OPEN" 16172293 "DTC_CONT_CNEG_OPEN" 16172294 "DTC_CONT_APOS_OPEN" 16172295 "DTC_CONT_ANEG_OPEN" 16172545 "DTC_CONT_MPOS_VDIF" 16172546 "DTC_CONT_MNEG_VDIF" 16172548 "DTC_CONT_CPOS_VDIF" 16172549 "DTC_CONT_CNEG_VDIF" 16172550 "DTC_CONT_APOS_VDIF" 16172551 "DTC_CONT_ANEG_VDIF" 16174848 "DTC_HVIL" 16174849 "DTC_LVBAT_LO" 16174850 "DTC_LVBAT_HI" 16174851 "DTC_LVBAT_ERR" 16523520 "DTC_LEMLO_OOR_HI" 16523521 "DTC_LEMLO_OOR_LO" 16523522 "DTC_LEMLO_FAULT" 16523776 "DTC_LEMHI_OOR_HI" 16523777 "DTC_LEMHI_OOR_LO" 16523778 "DTC_LEMHI_FAULT" 16496320 "DTC_MBB_TOO_FEW" 16496321 "DTC_MBB_TOO_MANY" 16496352 "DTC_CELL_VMAX_ERR" 16496353 "DTC_CELL_VMIN_ERR" 16496354 "DTC_CELL_VMAX" 16496362 "DTC_CELL_VMAX_SEVERE" 16496355 "DTC_CELL_VMIN" 16496363 "DTC_CELL_VMIN_SEVERE" 16496356 "DTC_MOD_VOLTAGE_COMPARE" 16496336 "DTC_CELL_T_ERR" 16496337 "DTC_CELL_TMAX1" 16496338 "DTC_CELL_TMAX2" 16496339 "DTC_CELL_TMIN" 16497665 "DTC_MBB_01_MISSING" 16497666 "DTC_MBB_02_MISSING" 16497667 "DTC_MBB_03_MISSING" 16497668 "DTC_MBB_04_MISSING" 16497669 "DTC_MBB_05_MISSING" 16497670 "DTC_MBB_06_MISSING" 16497671 "DTC_MBB_07_MISSING" 16497672 "DTC_MBB_08_MISSING" 16497673 "DTC_MBB_09_MISSING" 16497680 "DTC_MBB_10_MISSING" 16497681 "DTC_MBB_11_MISSING" 16497682 "DTC_MBB_12_MISSING" 16497683 "DTC_MBB_13_MISSING" 16497684 "DTC_MBB_14_MISSING" 16497685 "DTC_MBB_15_MISSING" 16497686 "DTC_MBB_16_MISSING" 16497687 "DTC_MBB_17_MISSING" 16497688 "DTC_MBB_18_MISSING" 16497689 "DTC_MBB_19_MISSING" 16497696 "DTC_MBB_20_MISSING" 16497697 "DTC_MBB_21_MISSING" 16497698 "DTC_MBB_22_MISSING" 16497699 "DTC_MBB_23_MISSING" 16497700 "DTC_MBB_24_MISSING" 16498177 "DTC_MBB_01_VFAULT" 16498178 "DTC_MBB_02_VFAULT" 16498179 "DTC_MBB_03_VFAULT" 16498180 "DTC_MBB_04_VFAULT" 16498181 "DTC_MBB_05_VFAULT" 16498182 "DTC_MBB_06_VFAULT" 16498183 "DTC_MBB_07_VFAULT" 16498184 "DTC_MBB_08_VFAULT" 16498185 "DTC_MBB_09_VFAULT" 16498192 "DTC_MBB_10_VFAULT" 16498193 "DTC_MBB_11_VFAULT" 16498194 "DTC_MBB_12_VFAULT" 16498195 "DTC_MBB_13_VFAULT" 16498196 "DTC_MBB_14_VFAULT" 16498197 "DTC_MBB_15_VFAULT" 16498198 "DTC_MBB_16_VFAULT" 16498199 "DTC_MBB_17_VFAULT" 16498200 "DTC_MBB_18_VFAULT" 16498201 "DTC_MBB_19_VFAULT" 16498208 "DTC_MBB_20_VFAULT" 16498209 "DTC_MBB_21_VFAULT" 16498210 "DTC_MBB_22_VFAULT" 16498211 "DTC_MBB_23_VFAULT" 16498212 "DTC_MBB_24_VFAULT" 16497921 "DTC_MBB_01_TFAULT" 16497922 "DTC_MBB_02_TFAULT" 16497923 "DTC_MBB_03_TFAULT" 16497924 "DTC_MBB_04_TFAULT" 16497925 "DTC_MBB_05_TFAULT" 16497926 "DTC_MBB_06_TFAULT" 16497927 "DTC_MBB_07_TFAULT" 16497928 "DTC_MBB_08_TFAULT" 16497929 "DTC_MBB_09_TFAULT" 16497936 "DTC_MBB_10_TFAULT" 16497937 "DTC_MBB_11_TFAULT" 16497938 "DTC_MBB_12_TFAULT" 16497939 "DTC_MBB_13_TFAULT" 16497940 "DTC_MBB_14_TFAULT" 16497941 "DTC_MBB_15_TFAULT" 16497942 "DTC_MBB_16_TFAULT" 16497943 "DTC_MBB_17_TFAULT" 16497944 "DTC_MBB_18_TFAULT" 16497945 "DTC_MBB_19_TFAULT" 16497952 "DTC_MBB_20_TFAULT" 16497953 "DTC_MBB_21_TFAULT" 16497954 "DTC_MBB_22_TFAULT" 16497955 "DTC_MBB_23_TFAULT" 16497956 "DTC_MBB_24_TFAULT" 15785984 "DTC_PRECHARGE_ENERGY" 15785985 "DTC_PRT_FAILED" 15785986 "DTC_PRT_OVERTEMP" 15785987 "DTC_PRT_PROHIBIT" 16556032 "DTC_COOLANT_TEMP_OOR_HI" 16556033 "DTC_COOLANT_TEMP_OOR_LO" 16252928 "DTC_KEY_OFF_TIME_ERROR" 16506880 "DTC_VBAT_MISMATCH" 16506881 "DTC_VBAT_VMAX" 16506882 "DTC_VBAT_VMIN" 16506883 "DTC_PACK_FUSE" 15798544 "DTC_LLS1_OOR_HI" 15798545 "DTC_LLS1_OOR_LO" 15798546 "DTC_LLS1_FAULT" 15798816 "DTC_LLS2_OOR_HI" 15798817 "DTC_LLS2_OOR_LO" 15798818 "DTC_LLS2_FAULT" 14479360 "DTC_CFL_HEARTBEAT" 14479361 "DTC_CFL_FAULT" 14479362 "DTC_CFL_FAULT_LATCH" 13635584 "DTC_CONT_A_FAILED_HI" 13635585 "DTC_CONT_A_FAILED_LO" 13635586 "DTC_CONT_B_FAILED_HI" 13635587 "DTC_CONT_B_FAILED_LO" 13635588 "DTC_CONT_C_FAILED_HI" 13635589 "DTC_CONT_C_FAILED_LO" 13635590 "DTC_CONT_D_FAILED_HI" 13635591 "DTC_CONT_D_FAILED_LO" 13635592 "DTC_CONT_E_FAILED_HI" 13635593 "DTC_CONT_E_FAILED_LO" 13635594 "DTC_CONT_F_FAILED_HI" 13635595 "DTC_CONT_F_FAILED_LO" 13635596 "DTC_CONT_G_FAILED_HI" 13635597 "DTC_CONT_G_FAILED_LO" 13635598 "DTC_LSD_A_FAILED_HI" 13635599 "DTC_LSD_A_FAILED_LO" 13635600 "DTC_LSD_B_FAILED_HI" 13635601 "DTC_LSD_B_FAILED_LO" 13635602 "DTC_LSD_C_FAILED_HI" 13635603 "DTC_LSD_C_FAILED_LO" 13635606 "DTC_CONT_PWR_FAILED_HI" 13635607 "DTC_CONT_PWR_FAILED_LO" 13635608 "DTC_LSD_PUMP_FAILED_HI" 13635609 "DTC_LSD_PUMP_FAILED_LO" 13635610 "DTC_CHG_A_ENABLE_FAILED_HI" 13635611 "DTC_CHG_A_ENABLE_FAILED_LO" 13635612 "DTC_CHG_B_ENABLE_FAILED_HI" 13635613 "DTC_CHG_B_ENABLE_FAILED_LO" 13635614 "DTC_SW14V_PWR_FAILED_HI" 13635615 "DTC_SW14V_PWR_FAILED_LO" 13635620 "DTC_HSD_A_FAILED_HI" 13635621 "DTC_HSD_A_FAILED_LO" 13635622 "DTC_HSD_B_FAILED_HI" 13635623 "DTC_HSD_B_FAILED_LO" 13692968 "DTC_CONT_HPWR_FAILED_HI" 13692969 "DTC_CONT_HPWR_FAILED_LO" 13692970 "DTC_CONT_HPWR_OOR_HI" 13692971 "DTC_CONT_HPWR_OOR_LO" 13635616 "DTC_5V_PWR_OOR_HI" 13635617 "DTC_5V_PWR_OOR_LO" 14606336 "DTC_NVM_WRITE_TO" 14606337 "DTC_NVM_READ_TO" 14614528 "DTC_SPI_DIG_POT_FAULT" ;
VAL_ 1120 bcm_dtc_093 0 " - " 11276288 "DTC_VEPO" 11276289 "DTC_HSC_MISSING" 11460608 "DTC_NVM_SOC" 11460609 "DTC_NVM_KOT" 11460610 "DTC_NVM_DTC" 11460611 "DTC_NVM_SOC_CORRECTION" 11460612 "DTC_NVM_APP_SCRATCHPAD" 11517962 "DTC_LOOPTIME_TASK_A" 11517963 "DTC_LOOPTIME_TASK_B" 11517964 "DTC_LOOPTIME_TASK_C" 11517965 "DTC_LOOPTIME_TASK_D" 11517966 "DTC_LOOPTIME_TASK_E" 11517967 "DTC_LOOPTIME_TASK_F" 11323904 "DTC_INTERLOCK_A_FAILED_LOW" 11323905 "DTC_INTERLOCK_A_FAILED_HIGH" 11324160 "DTC_INTERLOCK_B_FAILED_LOW" 11324161 "DTC_INTERLOCK_B_FAILED_HIGH" 15728640 "DTC_EPO" 16498688 "DTC_BRUSA_MISSING" 16498689 "DTC_BRUSA_IDC" 16498690 "DTC_BRUSA_REQ_VS_CMD" 16433152 "DTC_AKERWADE_MISSING" 16433153 "DTC_AKERWADE_IDC" 16433154 "DTC_AKERWADE_REQ_VS_CMD" 16564224 "DTC_CHGLEAR_MISSING" 16564225 "DTC_CHGLEAR_IDC" 16564226 "DTC_CHGLEAR_REQ_VS_CMD" 16522240 "DTC_CSM_MISSING" 16522752 "DTC_CSM_VBAT" 16522753 "DTC_CSM_VPOS" 16522754 "DTC_CSM_VNEG" 16522755 "DTC_CSM_CPOS" 16522756 "DTC_CSM_CNEG" 16522757 "DTC_CSM_APOS" 16522758 "DTC_CSM_ANEG" 16522759 "DTC_CSM_FUSE_HI" 16522760 "DTC_CSM_FUSE_LO" 16521728 "DTC_CSM_ASIC" 16521729 "DTC_CSM_AILO" 16521730 "DTC_CSM_AIHI" 16520957 "DTC_LEAKAGE_DETECT_FAULT" 16522444 "DTC_REALTIMECLOCK_FAULT" 16520945 "DTC_CSM_LEAK_FAIL_CALC" 16520946 "DTC_CSM_LEAK_FAIL_HW" 16520947 "DTC_CSM_LEAK_EXT_SHORT" 16520948 "DTC_CSM_LEAK_MID_PACK_SHORT" 16520949 "DTC_CSM_LEAK_ERROR" 16520950 "DTC_CSM_LEAK_UNKNOWN" 16523008 "DTC_CSM_VER_MISMATCH" 16523009 "DTC_CSM_DTC_SET" 16523010 "DTC_CSM_CAL_FAULT" 16560128 "DTC_IBAT_MISMATCH" 16576512 "DTC_DIS_MAX_I2T" 16576513 "DTC_CHG_MAX_I2T" 16576768 "DTC_DIS_WARNING_I2T" 16576769 "DTC_CHG_WARNING_I2T" 11296784 "DTC_SAEJ1772_PROX_DECT_OOR_HI" 11296785 "DTC_SAEJ1772_PROX_DECT_OOR_LO" 11296800 "DTC_SAEJ1772_PILOT_PWM_OOR_HI" 11296801 "DTC_SAEJ1772_PILOT_PWM_OOR_LO" 11296802 "DTC_SAEJ1772_PILOT_PWM_DIG_COMM" 11296803 "DTC_SAEJ1772_PILOT_PWM_IR_ERR" 16175360 "DTC_FGD1_NO_SENSOR" 16175361 "DTC_FGD1_OOR_HI" 16175362 "DTC_FGD1_OOR_LO" 16175363 "DTC_FGD1_FAULT" 16175616 "DTC_FGD2_NO_SENSOR" 16175617 "DTC_FGD2_OOR_HI" 16175618 "DTC_FGD2_OOR_LO" 16175619 "DTC_FGD2_FAULT" 16171008 "DTC_CONT_OPEN" 16171009 "DTC_CONT_CLOSE" 16171010 "DTC_CONT_OPEN_CURRENT" 16171264 "DTC_CONT_CLOSE_ON_RESET" 16171265 "DTC_CONT_CLOSE_SIG_FAILED" 16171520 "DTC_PRECHARGE_TIMEOUT" 16171777 "DTC_CONT_MPOS_WELD_AT_SU" 16171778 "DTC_CONT_MNEG_WELD_AT_SU" 16171780 "DTC_CONT_CPOS_WELD_AT_SU" 16171781 "DTC_CONT_CNEG_WELD_AT_SU" 16171782 "DTC_CONT_ANEG_WELD_AT_SU" 16171783 "DTC_CONT_APOS_WELD_AT_SU" 16172033 "DTC_CONT_MPOS_WELD_AT_SD" 16172034 "DTC_CONT_MNEG_WELD_AT_SD" 16172036 "DTC_CONT_CPOS_WELD_AT_SD" 16172037 "DTC_CONT_CNEG_WELD_AT_SD" 16172038 "DTC_CONT_ANEG_WELD_AT_SD" 16172039 "DTC_CONT_APOS_WELD_AT_SD" 16172289 "DTC_CONT_MPOS_OPEN" 16172290 "DTC_CONT_MNEG_OPEN" 16172291 "DTC_CONT_MPRE_OPEN" 16172292 "DTC_CONT_CPOS_OPEN" 16172293 "DTC_CONT_CNEG_OPEN" 16172294 "DTC_CONT_APOS_OPEN" 16172295 "DTC_CONT_ANEG_OPEN" 16172545 "DTC_CONT_MPOS_VDIF" 16172546 "DTC_CONT_MNEG_VDIF" 16172548 "DTC_CONT_CPOS_VDIF" 16172549 "DTC_CONT_CNEG_VDIF" 16172550 "DTC_CONT_APOS_VDIF" 16172551 "DTC_CONT_ANEG_VDIF" 16174848 "DTC_HVIL" 16174849 "DTC_LVBAT_LO" 16174850 "DTC_LVBAT_HI" 16174851 "DTC_LVBAT_ERR" 16523520 "DTC_LEMLO_OOR_HI" 16523521 "DTC_LEMLO_OOR_LO" 16523522 "DTC_LEMLO_FAULT" 16523776 "DTC_LEMHI_OOR_HI" 16523777 "DTC_LEMHI_OOR_LO" 16523778 "DTC_LEMHI_FAULT" 16496320 "DTC_MBB_TOO_FEW" 16496321 "DTC_MBB_TOO_MANY" 16496352 "DTC_CELL_VMAX_ERR" 16496353 "DTC_CELL_VMIN_ERR" 16496354 "DTC_CELL_VMAX" 16496362 "DTC_CELL_VMAX_SEVERE" 16496355 "DTC_CELL_VMIN" 16496363 "DTC_CELL_VMIN_SEVERE" 16496356 "DTC_MOD_VOLTAGE_COMPARE" 16496336 "DTC_CELL_T_ERR" 16496337 "DTC_CELL_TMAX1" 16496338 "DTC_CELL_TMAX2" 16496339 "DTC_CELL_TMIN" 16497665 "DTC_MBB_01_MISSING" 16497666 "DTC_MBB_02_MISSING" 16497667 "DTC_MBB_03_MISSING" 16497668 "DTC_MBB_04_MISSING" 16497669 "DTC_MBB_05_MISSING" 16497670 "DTC_MBB_06_MISSING" 16497671 "DTC_MBB_07_MISSING" 16497672 "DTC_MBB_08_MISSING" 16497673 "DTC_MBB_09_MISSING" 16497680 "DTC_MBB_10_MISSING" 16497681 "DTC_MBB_11_MISSING" 16497682 "DTC_MBB_12_MISSING" 16497683 "DTC_MBB_13_MISSING" 16497684 "DTC_MBB_14_MISSING" 16497685 "DTC_MBB_15_MISSING" 16497686 "DTC_MBB_16_MISSING" 16497687 "DTC_MBB_17_MISSING" 16497688 "DTC_MBB_18_MISSING" 16497689 "DTC_MBB_19_MISSING" 16497696 "DTC_MBB_20_MISSING" 16497697 "DTC_MBB_21_MISSING" 16497698 "DTC_MBB_22_MISSING" 16497699 "DTC_MBB_23_MISSING" 16497700 "DTC_MBB_24_MISSING" 16498177 "DTC_MBB_01_VFAULT" 16498178 "DTC_MBB_02_VFAULT" 16498179 "DTC_MBB_03_VFAULT" 16498180 "DTC_MBB_04_VFAULT" 16498181 "DTC_MBB_05_VFAULT" 16498182 "DTC_MBB_06_VFAULT" 16498183 "DTC_MBB_07_VFAULT" 16498184 "DTC_MBB_08_VFAULT" 16498185 "DTC_MBB_09_VFAULT" 16498192 "DTC_MBB_10_VFAULT" 16498193 "DTC_MBB_11_VFAULT" 16498194 "DTC_MBB_12_VFAULT" 16498195 "DTC_MBB_13_VFAULT" 16498196 "DTC_MBB_14_VFAULT" 16498197 "DTC_MBB_15_VFAULT" 16498198 "DTC_MBB_16_VFAULT" 16498199 "DTC_MBB_17_VFAULT" 16498200 "DTC_MBB_18_VFAULT" 16498201 "DTC_MBB_19_VFAULT" 16498208 "DTC_MBB_20_VFAULT" 16498209 "DTC_MBB_21_VFAULT" 16498210 "DTC_MBB_22_VFAULT" 16498211 "DTC_MBB_23_VFAULT" 16498212 "DTC_MBB_24_VFAULT" 16497921 "DTC_MBB_01_TFAULT" 16497922 "DTC_MBB_02_TFAULT" 16497923 "DTC_MBB_03_TFAULT" 16497924 "DTC_MBB_04_TFAULT" 16497925 "DTC_MBB_05_TFAULT" 16497926 "DTC_MBB_06_TFAULT" 16497927 "DTC_MBB_07_TFAULT" 16497928 "DTC_MBB_08_TFAULT" 16497929 "DTC_MBB_09_TFAULT" 16497936 "DTC_MBB_10_TFAULT" 16497937 "DTC_MBB_11_TFAULT" 16497938 "DTC_MBB_12_TFAULT" 16497939 "DTC_MBB_13_TFAULT" 16497940 "DTC_MBB_14_TFAULT" 16497941 "DTC_MBB_15_TFAULT" 16497942 "DTC_MBB_16_TFAULT" 16497943 "DTC_MBB_17_TFAULT" 16497944 "DTC_MBB_18_TFAULT" 16497945 "DTC_MBB_19_TFAULT" 16497952 "DTC_MBB_20_TFAULT" 16497953 "DTC_MBB_21_TFAULT" 16497954 "DTC_MBB_22_TFAULT" 16497955 "DTC_MBB_23_TFAULT" 16497956 "DTC_MBB_24_TFAULT" 15785984 "DTC_PRECHARGE_ENERGY" 15785985 "DTC_PRT_FAILED" 15785986 "DTC_PRT_OVERTEMP" 15785987 "DTC_PRT_PROHIBIT" 16556032 "DTC_COOLANT_TEMP_OOR_HI" 16556033 "DTC_COOLANT_TEMP_OOR_LO" 16252928 "DTC_KEY_OFF_TIME_ERROR" 16506880 "DTC_VBAT_MISMATCH" 16506881 "DTC_VBAT_VMAX" 16506882 "DTC_VBAT_VMIN" 16506883 "DTC_PACK_FUSE" 15798544 "DTC_LLS1_OOR_HI" 15798545 "DTC_LLS1_OOR_LO" 15798546 "DTC_LLS1_FAULT" 15798816 "DTC_LLS2_OOR_HI" 15798817 "DTC_LLS2_OOR_LO" 15798818 "DTC_LLS2_FAULT" 14479360 "DTC_CFL_HEARTBEAT" 14479361 "DTC_CFL_FAULT" 14479362 "DTC_CFL_FAULT_LATCH" 13635584 "DTC_CONT_A_FAILED_HI" 13635585 "DTC_CONT_A_FAILED_LO" 13635586 "DTC_CONT_B_FAILED_HI" 13635587 "DTC_CONT_B_FAILED_LO" 13635588 "DTC_CONT_C_FAILED_HI" 13635589 "DTC_CONT_C_FAILED_LO" 13635590 "DTC_CONT_D_FAILED_HI" 13635591 "DTC_CONT_D_FAILED_LO" 13635592 "DTC_CONT_E_FAILED_HI" 13635593 "DTC_CONT_E_FAILED_LO" 13635594 "DTC_CONT_F_FAILED_HI" 13635595 "DTC_CONT_F_FAILED_LO" 13635596 "DTC_CONT_G_FAILED_HI" 13635597 "DTC_CONT_G_FAILED_LO" 13635598 "DTC_LSD_A_FAILED_HI" 13635599 "DTC_LSD_A_FAILED_LO" 13635600 "DTC_LSD_B_FAILED_HI" 13635601 "DTC_LSD_B_FAILED_LO" 13635602 "DTC_LSD_C_FAILED_HI" 13635603 "DTC_LSD_C_FAILED_LO" 13635606 "DTC_CONT_PWR_FAILED_HI" 13635607 "DTC_CONT_PWR_FAILED_LO" 13635608 "DTC_LSD_PUMP_FAILED_HI" 13635609 "DTC_LSD_PUMP_FAILED_LO" 13635610 "DTC_CHG_A_ENABLE_FAILED_HI" 13635611 "DTC_CHG_A_ENABLE_FAILED_LO" 13635612 "DTC_CHG_B_ENABLE_FAILED_HI" 13635613 "DTC_CHG_B_ENABLE_FAILED_LO" 13635614 "DTC_SW14V_PWR_FAILED_HI" 13635615 "DTC_SW14V_PWR_FAILED_LO" 13635620 "DTC_HSD_A_FAILED_HI" 13635621 "DTC_HSD_A_FAILED_LO" 13635622 "DTC_HSD_B_FAILED_HI" 13635623 "DTC_HSD_B_FAILED_LO" 13692968 "DTC_CONT_HPWR_FAILED_HI" 13692969 "DTC_CONT_HPWR_FAILED_LO" 13692970 "DTC_CONT_HPWR_OOR_HI" 13692971 "DTC_CONT_HPWR_OOR_LO" 13635616 "DTC_5V_PWR_OOR_HI" 13635617 "DTC_5V_PWR_OOR_LO" 14606336 "DTC_NVM_WRITE_TO" 14606337 "DTC_NVM_READ_TO" 14614528 "DTC_SPI_DIG_POT_FAULT" ;
VAL_ 1120 bcm_dtc_094 0 " - " 11276288 "DTC_VEPO" 11276289 "DTC_HSC_MISSING" 11460608 "DTC_NVM_SOC" 11460609 "DTC_NVM_KOT" 11460610 "DTC_NVM_DTC" 11460611 "DTC_NVM_SOC_CORRECTION" 11460612 "DTC_NVM_APP_SCRATCHPAD" 11517962 "DTC_LOOPTIME_TASK_A" 11517963 "DTC_LOOPTIME_TASK_B" 11517964 "DTC_LOOPTIME_TASK_C" 11517965 "DTC_LOOPTIME_TASK_D" 11517966 "DTC_LOOPTIME_TASK_E" 11517967 "DTC_LOOPTIME_TASK_F" 11323904 "DTC_INTERLOCK_A_FAILED_LOW" 11323905 "DTC_INTERLOCK_A_FAILED_HIGH" 11324160 "DTC_INTERLOCK_B_FAILED_LOW" 11324161 "DTC_INTERLOCK_B_FAILED_HIGH" 15728640 "DTC_EPO" 16498688 "DTC_BRUSA_MISSING" 16498689 "DTC_BRUSA_IDC" 16498690 "DTC_BRUSA_REQ_VS_CMD" 16433152 "DTC_AKERWADE_MISSING" 16433153 "DTC_AKERWADE_IDC" 16433154 "DTC_AKERWADE_REQ_VS_CMD" 16564224 "DTC_CHGLEAR_MISSING" 16564225 "DTC_CHGLEAR_IDC" 16564226 "DTC_CHGLEAR_REQ_VS_CMD" 16522240 "DTC_CSM_MISSING" 16522752 "DTC_CSM_VBAT" 16522753 "DTC_CSM_VPOS" 16522754 "DTC_CSM_VNEG" 16522755 "DTC_CSM_CPOS" 16522756 "DTC_CSM_CNEG" 16522757 "DTC_CSM_APOS" 16522758 "DTC_CSM_ANEG" 16522759 "DTC_CSM_FUSE_HI" 16522760 "DTC_CSM_FUSE_LO" 16521728 "DTC_CSM_ASIC" 16521729 "DTC_CSM_AILO" 16521730 "DTC_CSM_AIHI" 16520957 "DTC_LEAKAGE_DETECT_FAULT" 16522444 "DTC_REALTIMECLOCK_FAULT" 16520945 "DTC_CSM_LEAK_FAIL_CALC" 16520946 "DTC_CSM_LEAK_FAIL_HW" 16520947 "DTC_CSM_LEAK_EXT_SHORT" 16520948 "DTC_CSM_LEAK_MID_PACK_SHORT" 16520949 "DTC_CSM_LEAK_ERROR" 16520950 "DTC_CSM_LEAK_UNKNOWN" 16523008 "DTC_CSM_VER_MISMATCH" 16523009 "DTC_CSM_DTC_SET" 16523010 "DTC_CSM_CAL_FAULT" 16560128 "DTC_IBAT_MISMATCH" 16576512 "DTC_DIS_MAX_I2T" 16576513 "DTC_CHG_MAX_I2T" 16576768 "DTC_DIS_WARNING_I2T" 16576769 "DTC_CHG_WARNING_I2T" 11296784 "DTC_SAEJ1772_PROX_DECT_OOR_HI" 11296785 "DTC_SAEJ1772_PROX_DECT_OOR_LO" 11296800 "DTC_SAEJ1772_PILOT_PWM_OOR_HI" 11296801 "DTC_SAEJ1772_PILOT_PWM_OOR_LO" 11296802 "DTC_SAEJ1772_PILOT_PWM_DIG_COMM" 11296803 "DTC_SAEJ1772_PILOT_PWM_IR_ERR" 16175360 "DTC_FGD1_NO_SENSOR" 16175361 "DTC_FGD1_OOR_HI" 16175362 "DTC_FGD1_OOR_LO" 16175363 "DTC_FGD1_FAULT" 16175616 "DTC_FGD2_NO_SENSOR" 16175617 "DTC_FGD2_OOR_HI" 16175618 "DTC_FGD2_OOR_LO" 16175619 "DTC_FGD2_FAULT" 16171008 "DTC_CONT_OPEN" 16171009 "DTC_CONT_CLOSE" 16171010 "DTC_CONT_OPEN_CURRENT" 16171264 "DTC_CONT_CLOSE_ON_RESET" 16171265 "DTC_CONT_CLOSE_SIG_FAILED" 16171520 "DTC_PRECHARGE_TIMEOUT" 16171777 "DTC_CONT_MPOS_WELD_AT_SU" 16171778 "DTC_CONT_MNEG_WELD_AT_SU" 16171780 "DTC_CONT_CPOS_WELD_AT_SU" 16171781 "DTC_CONT_CNEG_WELD_AT_SU" 16171782 "DTC_CONT_ANEG_WELD_AT_SU" 16171783 "DTC_CONT_APOS_WELD_AT_SU" 16172033 "DTC_CONT_MPOS_WELD_AT_SD" 16172034 "DTC_CONT_MNEG_WELD_AT_SD" 16172036 "DTC_CONT_CPOS_WELD_AT_SD" 16172037 "DTC_CONT_CNEG_WELD_AT_SD" 16172038 "DTC_CONT_ANEG_WELD_AT_SD" 16172039 "DTC_CONT_APOS_WELD_AT_SD" 16172289 "DTC_CONT_MPOS_OPEN" 16172290 "DTC_CONT_MNEG_OPEN" 16172291 "DTC_CONT_MPRE_OPEN" 16172292 "DTC_CONT_CPOS_OPEN" 16172293 "DTC_CONT_CNEG_OPEN" 16172294 "DTC_CONT_APOS_OPEN" 16172295 "DTC_CONT_ANEG_OPEN" 16172545 "DTC_CONT_MPOS_VDIF" 16172546 "DTC_CONT_MNEG_VDIF" 16172548 "DTC_CONT_CPOS_VDIF" 16172549 "DTC_CONT_CNEG_VDIF" 16172550 "DTC_CONT_APOS_VDIF" 16172551 "DTC_CONT_ANEG_VDIF" 16174848 "DTC_HVIL" 16174849 "DTC_LVBAT_LO" 16174850 "DTC_LVBAT_HI" 16174851 "DTC_LVBAT_ERR" 16523520 "DTC_LEMLO_OOR_HI" 16523521 "DTC_LEMLO_OOR_LO" 16523522 "DTC_LEMLO_FAULT" 16523776 "DTC_LEMHI_OOR_HI" 16523777 "DTC_LEMHI_OOR_LO" 16523778 "DTC_LEMHI_FAULT" 16496320 "DTC_MBB_TOO_FEW" 16496321 "DTC_MBB_TOO_MANY" 16496352 "DTC_CELL_VMAX_ERR" 16496353 "DTC_CELL_VMIN_ERR" 16496354 "DTC_CELL_VMAX" 16496362 "DTC_CELL_VMAX_SEVERE" 16496355 "DTC_CELL_VMIN" 16496363 "DTC_CELL_VMIN_SEVERE" 16496356 "DTC_MOD_VOLTAGE_COMPARE" 16496336 "DTC_CELL_T_ERR" 16496337 "DTC_CELL_TMAX1" 16496338 "DTC_CELL_TMAX2" 16496339 "DTC_CELL_TMIN" 16497665 "DTC_MBB_01_MISSING" 16497666 "DTC_MBB_02_MISSING" 16497667 "DTC_MBB_03_MISSING" 16497668 "DTC_MBB_04_MISSING" 16497669 "DTC_MBB_05_MISSING" 16497670 "DTC_MBB_06_MISSING" 16497671 "DTC_MBB_07_MISSING" 16497672 "DTC_MBB_08_MISSING" 16497673 "DTC_MBB_09_MISSING" 16497680 "DTC_MBB_10_MISSING" 16497681 "DTC_MBB_11_MISSING" 16497682 "DTC_MBB_12_MISSING" 16497683 "DTC_MBB_13_MISSING" 16497684 "DTC_MBB_14_MISSING" 16497685 "DTC_MBB_15_MISSING" 16497686 "DTC_MBB_16_MISSING" 16497687 "DTC_MBB_17_MISSING" 16497688 "DTC_MBB_18_MISSING" 16497689 "DTC_MBB_19_MISSING" 16497696 "DTC_MBB_20_MISSING" 16497697 "DTC_MBB_21_MISSING" 16497698 "DTC_MBB_22_MISSING" 16497699 "DTC_MBB_23_MISSING" 16497700 "DTC_MBB_24_MISSING" 16498177 "DTC_MBB_01_VFAULT" 16498178 "DTC_MBB_02_VFAULT" 16498179 "DTC_MBB_03_VFAULT" 16498180 "DTC_MBB_04_VFAULT" 16498181 "DTC_MBB_05_VFAULT" 16498182 "DTC_MBB_06_VFAULT" 16498183 "DTC_MBB_07_VFAULT" 16498184 "DTC_MBB_08_VFAULT" 16498185 "DTC_MBB_09_VFAULT" 16498192 "DTC_MBB_10_VFAULT" 16498193 "DTC_MBB_11_VFAULT" 16498194 "DTC_MBB_12_VFAULT" 16498195 "DTC_MBB_13_VFAULT" 16498196 "DTC_MBB_14_VFAULT" 16498197 "DTC_MBB_15_VFAULT" 16498198 "DTC_MBB_16_VFAULT" 16498199 "DTC_MBB_17_VFAULT" 16498200 "DTC_MBB_18_VFAULT" 16498201 "DTC_MBB_19_VFAULT" 16498208 "DTC_MBB_20_VFAULT" 16498209 "DTC_MBB_21_VFAULT" 16498210 "DTC_MBB_22_VFAULT" 16498211 "DTC_MBB_23_VFAULT" 16498212 "DTC_MBB_24_VFAULT" 16497921 "DTC_MBB_01_TFAULT" 16497922 "DTC_MBB_02_TFAULT" 16497923 "DTC_MBB_03_TFAULT" 16497924 "DTC_MBB_04_TFAULT" 16497925 "DTC_MBB_05_TFAULT" 16497926 "DTC_MBB_06_TFAULT" 16497927 "DTC_MBB_07_TFAULT" 16497928 "DTC_MBB_08_TFAULT" 16497929 "DTC_MBB_09_TFAULT" 16497936 "DTC_MBB_10_TFAULT" 16497937 "DTC_MBB_11_TFAULT" 16497938 "DTC_MBB_12_TFAULT" 16497939 "DTC_MBB_13_TFAULT" 16497940 "DTC_MBB_14_TFAULT" 16497941 "DTC_MBB_15_TFAULT" 16497942 "DTC_MBB_16_TFAULT" 16497943 "DTC_MBB_17_TFAULT" 16497944 "DTC_MBB_18_TFAULT" 16497945 "DTC_MBB_19_TFAULT" 16497952 "DTC_MBB_20_TFAULT" 16497953 "DTC_MBB_21_TFAULT" 16497954 "DTC_MBB_22_TFAULT" 16497955 "DTC_MBB_23_TFAULT" 16497956 "DTC_MBB_24_TFAULT" 15785984 "DTC_PRECHARGE_ENERGY" 15785985 "DTC_PRT_FAILED" 15785986 "DTC_PRT_OVERTEMP" 15785987 "DTC_PRT_PROHIBIT" 16556032 "DTC_COOLANT_TEMP_OOR_HI" 16556033 "DTC_COOLANT_TEMP_OOR_LO" 16252928 "DTC_KEY_OFF_TIME_ERROR" 16506880 "DTC_VBAT_MISMATCH" 16506881 "DTC_VBAT_VMAX" 16506882 "DTC_VBAT_VMIN" 16506883 "DTC_PACK_FUSE" 15798544 "DTC_LLS1_OOR_HI" 15798545 "DTC_LLS1_OOR_LO" 15798546 "DTC_LLS1_FAULT" 15798816 "DTC_LLS2_OOR_HI" 15798817 "DTC_LLS2_OOR_LO" 15798818 "DTC_LLS2_FAULT" 14479360 "DTC_CFL_HEARTBEAT" 14479361 "DTC_CFL_FAULT" 14479362 "DTC_CFL_FAULT_LATCH" 13635584 "DTC_CONT_A_FAILED_HI" 13635585 "DTC_CONT_A_FAILED_LO" 13635586 "DTC_CONT_B_FAILED_HI" 13635587 "DTC_CONT_B_FAILED_LO" 13635588 "DTC_CONT_C_FAILED_HI" 13635589 "DTC_CONT_C_FAILED_LO" 13635590 "DTC_CONT_D_FAILED_HI" 13635591 "DTC_CONT_D_FAILED_LO" 13635592 "DTC_CONT_E_FAILED_HI" 13635593 "DTC_CONT_E_FAILED_LO" 13635594 "DTC_CONT_F_FAILED_HI" 13635595 "DTC_CONT_F_FAILED_LO" 13635596 "DTC_CONT_G_FAILED_HI" 13635597 "DTC_CONT_G_FAILED_LO" 13635598 "DTC_LSD_A_FAILED_HI" 13635599 "DTC_LSD_A_FAILED_LO" 13635600 "DTC_LSD_B_FAILED_HI" 13635601 "DTC_LSD_B_FAILED_LO" 13635602 "DTC_LSD_C_FAILED_HI" 13635603 "DTC_LSD_C_FAILED_LO" 13635606 "DTC_CONT_PWR_FAILED_HI" 13635607 "DTC_CONT_PWR_FAILED_LO" 13635608 "DTC_LSD_PUMP_FAILED_HI" 13635609 "DTC_LSD_PUMP_FAILED_LO" 13635610 "DTC_CHG_A_ENABLE_FAILED_HI" 13635611 "DTC_CHG_A_ENABLE_FAILED_LO" 13635612 "DTC_CHG_B_ENABLE_FAILED_HI" 13635613 "DTC_CHG_B_ENABLE_FAILED_LO" 13635614 "DTC_SW14V_PWR_FAILED_HI" 13635615 "DTC_SW14V_PWR_FAILED_LO" 13635620 "DTC_HSD_A_FAILED_HI" 13635621 "DTC_HSD_A_FAILED_LO" 13635622 "DTC_HSD_B_FAILED_HI" 13635623 "DTC_HSD_B_FAILED_LO" 13692968 "DTC_CONT_HPWR_FAILED_HI" 13692969 "DTC_CONT_HPWR_FAILED_LO" 13692970 "DTC_CONT_HPWR_OOR_HI" 13692971 "DTC_CONT_HPWR_OOR_LO" 13635616 "DTC_5V_PWR_OOR_HI" 13635617 "DTC_5V_PWR_OOR_LO" 14606336 "DTC_NVM_WRITE_TO" 14606337 "DTC_NVM_READ_TO" 14614528 "DTC_SPI_DIG_POT_FAULT" ;
VAL_ 1120 bcm_dtc_095 0 " - " 11276288 "DTC_VEPO" 11276289 "DTC_HSC_MISSING" 11460608 "DTC_NVM_SOC" 11460609 "DTC_NVM_KOT" 11460610 "DTC_NVM_DTC" 11460611 "DTC_NVM_SOC_CORRECTION" 11460612 "DTC_NVM_APP_SCRATCHPAD" 11517962 "DTC_LOOPTIME_TASK_A" 11517963 "DTC_LOOPTIME_TASK_B" 11517964 "DTC_LOOPTIME_TASK_C" 11517965 "DTC_LOOPTIME_TASK_D" 11517966 "DTC_LOOPTIME_TASK_E" 11517967 "DTC_LOOPTIME_TASK_F" 11323904 "DTC_INTERLOCK_A_FAILED_LOW" 11323905 "DTC_INTERLOCK_A_FAILED_HIGH" 11324160 "DTC_INTERLOCK_B_FAILED_LOW" 11324161 "DTC_INTERLOCK_B_FAILED_HIGH" 15728640 "DTC_EPO" 16498688 "DTC_BRUSA_MISSING" 16498689 "DTC_BRUSA_IDC" 16498690 "DTC_BRUSA_REQ_VS_CMD" 16433152 "DTC_AKERWADE_MISSING" 16433153 "DTC_AKERWADE_IDC" 16433154 "DTC_AKERWADE_REQ_VS_CMD" 16564224 "DTC_CHGLEAR_MISSING" 16564225 "DTC_CHGLEAR_IDC" 16564226 "DTC_CHGLEAR_REQ_VS_CMD" 16522240 "DTC_CSM_MISSING" 16522752 "DTC_CSM_VBAT" 16522753 "DTC_CSM_VPOS" 16522754 "DTC_CSM_VNEG" 16522755 "DTC_CSM_CPOS" 16522756 "DTC_CSM_CNEG" 16522757 "DTC_CSM_APOS" 16522758 "DTC_CSM_ANEG" 16522759 "DTC_CSM_FUSE_HI" 16522760 "DTC_CSM_FUSE_LO" 16521728 "DTC_CSM_ASIC" 16521729 "DTC_CSM_AILO" 16521730 "DTC_CSM_AIHI" 16520957 "DTC_LEAKAGE_DETECT_FAULT" 16522444 "DTC_REALTIMECLOCK_FAULT" 16520945 "DTC_CSM_LEAK_FAIL_CALC" 16520946 "DTC_CSM_LEAK_FAIL_HW" 16520947 "DTC_CSM_LEAK_EXT_SHORT" 16520948 "DTC_CSM_LEAK_MID_PACK_SHORT" 16520949 "DTC_CSM_LEAK_ERROR" 16520950 "DTC_CSM_LEAK_UNKNOWN" 16523008 "DTC_CSM_VER_MISMATCH" 16523009 "DTC_CSM_DTC_SET" 16523010 "DTC_CSM_CAL_FAULT" 16560128 "DTC_IBAT_MISMATCH" 16576512 "DTC_DIS_MAX_I2T" 16576513 "DTC_CHG_MAX_I2T" 16576768 "DTC_DIS_WARNING_I2T" 16576769 "DTC_CHG_WARNING_I2T" 11296784 "DTC_SAEJ1772_PROX_DECT_OOR_HI" 11296785 "DTC_SAEJ1772_PROX_DECT_OOR_LO" 11296800 "DTC_SAEJ1772_PILOT_PWM_OOR_HI" 11296801 "DTC_SAEJ1772_PILOT_PWM_OOR_LO" 11296802 "DTC_SAEJ1772_PILOT_PWM_DIG_COMM" 11296803 "DTC_SAEJ1772_PILOT_PWM_IR_ERR" 16175360 "DTC_FGD1_NO_SENSOR" 16175361 "DTC_FGD1_OOR_HI" 16175362 "DTC_FGD1_OOR_LO" 16175363 "DTC_FGD1_FAULT" 16175616 "DTC_FGD2_NO_SENSOR" 16175617 "DTC_FGD2_OOR_HI" 16175618 "DTC_FGD2_OOR_LO" 16175619 "DTC_FGD2_FAULT" 16171008 "DTC_CONT_OPEN" 16171009 "DTC_CONT_CLOSE" 16171010 "DTC_CONT_OPEN_CURRENT" 16171264 "DTC_CONT_CLOSE_ON_RESET" 16171265 "DTC_CONT_CLOSE_SIG_FAILED" 16171520 "DTC_PRECHARGE_TIMEOUT" 16171777 "DTC_CONT_MPOS_WELD_AT_SU" 16171778 "DTC_CONT_MNEG_WELD_AT_SU" 16171780 "DTC_CONT_CPOS_WELD_AT_SU" 16171781 "DTC_CONT_CNEG_WELD_AT_SU" 16171782 "DTC_CONT_ANEG_WELD_AT_SU" 16171783 "DTC_CONT_APOS_WELD_AT_SU" 16172033 "DTC_CONT_MPOS_WELD_AT_SD" 16172034 "DTC_CONT_MNEG_WELD_AT_SD" 16172036 "DTC_CONT_CPOS_WELD_AT_SD" 16172037 "DTC_CONT_CNEG_WELD_AT_SD" 16172038 "DTC_CONT_ANEG_WELD_AT_SD" 16172039 "DTC_CONT_APOS_WELD_AT_SD" 16172289 "DTC_CONT_MPOS_OPEN" 16172290 "DTC_CONT_MNEG_OPEN" 16172291 "DTC_CONT_MPRE_OPEN" 16172292 "DTC_CONT_CPOS_OPEN" 16172293 "DTC_CONT_CNEG_OPEN" 16172294 "DTC_CONT_APOS_OPEN" 16172295 "DTC_CONT_ANEG_OPEN" 16172545 "DTC_CONT_MPOS_VDIF" 16172546 "DTC_CONT_MNEG_VDIF" 16172548 "DTC_CONT_CPOS_VDIF" 16172549 "DTC_CONT_CNEG_VDIF" 16172550 "DTC_CONT_APOS_VDIF" 16172551 "DTC_CONT_ANEG_VDIF" 16174848 "DTC_HVIL" 16174849 "DTC_LVBAT_LO" 16174850 "DTC_LVBAT_HI" 16174851 "DTC_LVBAT_ERR" 16523520 "DTC_LEMLO_OOR_HI" 16523521 "DTC_LEMLO_OOR_LO" 16523522 "DTC_LEMLO_FAULT" 16523776 "DTC_LEMHI_OOR_HI" 16523777 "DTC_LEMHI_OOR_LO" 16523778 "DTC_LEMHI_FAULT" 16496320 "DTC_MBB_TOO_FEW" 16496321 "DTC_MBB_TOO_MANY" 16496352 "DTC_CELL_VMAX_ERR" 16496353 "DTC_CELL_VMIN_ERR" 16496354 "DTC_CELL_VMAX" 16496362 "DTC_CELL_VMAX_SEVERE" 16496355 "DTC_CELL_VMIN" 16496363 "DTC_CELL_VMIN_SEVERE" 16496356 "DTC_MOD_VOLTAGE_COMPARE" 16496336 "DTC_CELL_T_ERR" 16496337 "DTC_CELL_TMAX1" 16496338 "DTC_CELL_TMAX2" 16496339 "DTC_CELL_TMIN" 16497665 "DTC_MBB_01_MISSING" 16497666 "DTC_MBB_02_MISSING" 16497667 "DTC_MBB_03_MISSING" 16497668 "DTC_MBB_04_MISSING" 16497669 "DTC_MBB_05_MISSING" 16497670 "DTC_MBB_06_MISSING" 16497671 "DTC_MBB_07_MISSING" 16497672 "DTC_MBB_08_MISSING" 16497673 "DTC_MBB_09_MISSING" 16497680 "DTC_MBB_10_MISSING" 16497681 "DTC_MBB_11_MISSING" 16497682 "DTC_MBB_12_MISSING" 16497683 "DTC_MBB_13_MISSING" 16497684 "DTC_MBB_14_MISSING" 16497685 "DTC_MBB_15_MISSING" 16497686 "DTC_MBB_16_MISSING" 16497687 "DTC_MBB_17_MISSING" 16497688 "DTC_MBB_18_MISSING" 16497689 "DTC_MBB_19_MISSING" 16497696 "DTC_MBB_20_MISSING" 16497697 "DTC_MBB_21_MISSING" 16497698 "DTC_MBB_22_MISSING" 16497699 "DTC_MBB_23_MISSING" 16497700 "DTC_MBB_24_MISSING" 16498177 "DTC_MBB_01_VFAULT" 16498178 "DTC_MBB_02_VFAULT" 16498179 "DTC_MBB_03_VFAULT" 16498180 "DTC_MBB_04_VFAULT" 16498181 "DTC_MBB_05_VFAULT" 16498182 "DTC_MBB_06_VFAULT" 16498183 "DTC_MBB_07_VFAULT" 16498184 "DTC_MBB_08_VFAULT" 16498185 "DTC_MBB_09_VFAULT" 16498192 "DTC_MBB_10_VFAULT" 16498193 "DTC_MBB_11_VFAULT" 16498194 "DTC_MBB_12_VFAULT" 16498195 "DTC_MBB_13_VFAULT" 16498196 "DTC_MBB_14_VFAULT" 16498197 "DTC_MBB_15_VFAULT" 16498198 "DTC_MBB_16_VFAULT" 16498199 "DTC_MBB_17_VFAULT" 16498200 "DTC_MBB_18_VFAULT" 16498201 "DTC_MBB_19_VFAULT" 16498208 "DTC_MBB_20_VFAULT" 16498209 "DTC_MBB_21_VFAULT" 16498210 "DTC_MBB_22_VFAULT" 16498211 "DTC_MBB_23_VFAULT" 16498212 "DTC_MBB_24_VFAULT" 16497921 "DTC_MBB_01_TFAULT" 16497922 "DTC_MBB_02_TFAULT" 16497923 "DTC_MBB_03_TFAULT" 16497924 "DTC_MBB_04_TFAULT" 16497925 "DTC_MBB_05_TFAULT" 16497926 "DTC_MBB_06_TFAULT" 16497927 "DTC_MBB_07_TFAULT" 16497928 "DTC_MBB_08_TFAULT" 16497929 "DTC_MBB_09_TFAULT" 16497936 "DTC_MBB_10_TFAULT" 16497937 "DTC_MBB_11_TFAULT" 16497938 "DTC_MBB_12_TFAULT" 16497939 "DTC_MBB_13_TFAULT" 16497940 "DTC_MBB_14_TFAULT" 16497941 "DTC_MBB_15_TFAULT" 16497942 "DTC_MBB_16_TFAULT" 16497943 "DTC_MBB_17_TFAULT" 16497944 "DTC_MBB_18_TFAULT" 16497945 "DTC_MBB_19_TFAULT" 16497952 "DTC_MBB_20_TFAULT" 16497953 "DTC_MBB_21_TFAULT" 16497954 "DTC_MBB_22_TFAULT" 16497955 "DTC_MBB_23_TFAULT" 16497956 "DTC_MBB_24_TFAULT" 15785984 "DTC_PRECHARGE_ENERGY" 15785985 "DTC_PRT_FAILED" 15785986 "DTC_PRT_OVERTEMP" 15785987 "DTC_PRT_PROHIBIT" 16556032 "DTC_COOLANT_TEMP_OOR_HI" 16556033 "DTC_COOLANT_TEMP_OOR_LO" 16252928 "DTC_KEY_OFF_TIME_ERROR" 16506880 "DTC_VBAT_MISMATCH" 16506881 "DTC_VBAT_VMAX" 16506882 "DTC_VBAT_VMIN" 16506883 "DTC_PACK_FUSE" 15798544 "DTC_LLS1_OOR_HI" 15798545 "DTC_LLS1_OOR_LO" 15798546 "DTC_LLS1_FAULT" 15798816 "DTC_LLS2_OOR_HI" 15798817 "DTC_LLS2_OOR_LO" 15798818 "DTC_LLS2_FAULT" 14479360 "DTC_CFL_HEARTBEAT" 14479361 "DTC_CFL_FAULT" 14479362 "DTC_CFL_FAULT_LATCH" 13635584 "DTC_CONT_A_FAILED_HI" 13635585 "DTC_CONT_A_FAILED_LO" 13635586 "DTC_CONT_B_FAILED_HI" 13635587 "DTC_CONT_B_FAILED_LO" 13635588 "DTC_CONT_C_FAILED_HI" 13635589 "DTC_CONT_C_FAILED_LO" 13635590 "DTC_CONT_D_FAILED_HI" 13635591 "DTC_CONT_D_FAILED_LO" 13635592 "DTC_CONT_E_FAILED_HI" 13635593 "DTC_CONT_E_FAILED_LO" 13635594 "DTC_CONT_F_FAILED_HI" 13635595 "DTC_CONT_F_FAILED_LO" 13635596 "DTC_CONT_G_FAILED_HI" 13635597 "DTC_CONT_G_FAILED_LO" 13635598 "DTC_LSD_A_FAILED_HI" 13635599 "DTC_LSD_A_FAILED_LO" 13635600 "DTC_LSD_B_FAILED_HI" 13635601 "DTC_LSD_B_FAILED_LO" 13635602 "DTC_LSD_C_FAILED_HI" 13635603 "DTC_LSD_C_FAILED_LO" 13635606 "DTC_CONT_PWR_FAILED_HI" 13635607 "DTC_CONT_PWR_FAILED_LO" 13635608 "DTC_LSD_PUMP_FAILED_HI" 13635609 "DTC_LSD_PUMP_FAILED_LO" 13635610 "DTC_CHG_A_ENABLE_FAILED_HI" 13635611 "DTC_CHG_A_ENABLE_FAILED_LO" 13635612 "DTC_CHG_B_ENABLE_FAILED_HI" 13635613 "DTC_CHG_B_ENABLE_FAILED_LO" 13635614 "DTC_SW14V_PWR_FAILED_HI" 13635615 "DTC_SW14V_PWR_FAILED_LO" 13635620 "DTC_HSD_A_FAILED_HI" 13635621 "DTC_HSD_A_FAILED_LO" 13635622 "DTC_HSD_B_FAILED_HI" 13635623 "DTC_HSD_B_FAILED_LO" 13692968 "DTC_CONT_HPWR_FAILED_HI" 13692969 "DTC_CONT_HPWR_FAILED_LO" 13692970 "DTC_CONT_HPWR_OOR_HI" 13692971 "DTC_CONT_HPWR_OOR_LO" 13635616 "DTC_5V_PWR_OOR_HI" 13635617 "DTC_5V_PWR_OOR_LO" 14606336 "DTC_NVM_WRITE_TO" 14606337 "DTC_NVM_READ_TO" 14614528 "DTC_SPI_DIG_POT_FAULT" ;
VAL_ 1120 bcm_dtc_096 0 " - " 11276288 "DTC_VEPO" 11276289 "DTC_HSC_MISSING" 11460608 "DTC_NVM_SOC" 11460609 "DTC_NVM_KOT" 11460610 "DTC_NVM_DTC" 11460611 "DTC_NVM_SOC_CORRECTION" 11460612 "DTC_NVM_APP_SCRATCHPAD" 11517962 "DTC_LOOPTIME_TASK_A" 11517963 "DTC_LOOPTIME_TASK_B" 11517964 "DTC_LOOPTIME_TASK_C" 11517965 "DTC_LOOPTIME_TASK_D" 11517966 "DTC_LOOPTIME_TASK_E" 11517967 "DTC_LOOPTIME_TASK_F" 11323904 "DTC_INTERLOCK_A_FAILED_LOW" 11323905 "DTC_INTERLOCK_A_FAILED_HIGH" 11324160 "DTC_INTERLOCK_B_FAILED_LOW" 11324161 "DTC_INTERLOCK_B_FAILED_HIGH" 15728640 "DTC_EPO" 16498688 "DTC_BRUSA_MISSING" 16498689 "DTC_BRUSA_IDC" 16498690 "DTC_BRUSA_REQ_VS_CMD" 16433152 "DTC_AKERWADE_MISSING" 16433153 "DTC_AKERWADE_IDC" 16433154 "DTC_AKERWADE_REQ_VS_CMD" 16564224 "DTC_CHGLEAR_MISSING" 16564225 "DTC_CHGLEAR_IDC" 16564226 "DTC_CHGLEAR_REQ_VS_CMD" 16522240 "DTC_CSM_MISSING" 16522752 "DTC_CSM_VBAT" 16522753 "DTC_CSM_VPOS" 16522754 "DTC_CSM_VNEG" 16522755 "DTC_CSM_CPOS" 16522756 "DTC_CSM_CNEG" 16522757 "DTC_CSM_APOS" 16522758 "DTC_CSM_ANEG" 16522759 "DTC_CSM_FUSE_HI" 16522760 "DTC_CSM_FUSE_LO" 16521728 "DTC_CSM_ASIC" 16521729 "DTC_CSM_AILO" 16521730 "DTC_CSM_AIHI" 16520957 "DTC_LEAKAGE_DETECT_FAULT" 16522444 "DTC_REALTIMECLOCK_FAULT" 16520945 "DTC_CSM_LEAK_FAIL_CALC" 16520946 "DTC_CSM_LEAK_FAIL_HW" 16520947 "DTC_CSM_LEAK_EXT_SHORT" 16520948 "DTC_CSM_LEAK_MID_PACK_SHORT" 16520949 "DTC_CSM_LEAK_ERROR" 16520950 "DTC_CSM_LEAK_UNKNOWN" 16523008 "DTC_CSM_VER_MISMATCH" 16523009 "DTC_CSM_DTC_SET" 16523010 "DTC_CSM_CAL_FAULT" 16560128 "DTC_IBAT_MISMATCH" 16576512 "DTC_DIS_MAX_I2T" 16576513 "DTC_CHG_MAX_I2T" 16576768 "DTC_DIS_WARNING_I2T" 16576769 "DTC_CHG_WARNING_I2T" 11296784 "DTC_SAEJ1772_PROX_DECT_OOR_HI" 11296785 "DTC_SAEJ1772_PROX_DECT_OOR_LO" 11296800 "DTC_SAEJ1772_PILOT_PWM_OOR_HI" 11296801 "DTC_SAEJ1772_PILOT_PWM_OOR_LO" 11296802 "DTC_SAEJ1772_PILOT_PWM_DIG_COMM" 11296803 "DTC_SAEJ1772_PILOT_PWM_IR_ERR" 16175360 "DTC_FGD1_NO_SENSOR" 16175361 "DTC_FGD1_OOR_HI" 16175362 "DTC_FGD1_OOR_LO" 16175363 "DTC_FGD1_FAULT" 16175616 "DTC_FGD2_NO_SENSOR" 16175617 "DTC_FGD2_OOR_HI" 16175618 "DTC_FGD2_OOR_LO" 16175619 "DTC_FGD2_FAULT" 16171008 "DTC_CONT_OPEN" 16171009 "DTC_CONT_CLOSE" 16171010 "DTC_CONT_OPEN_CURRENT" 16171264 "DTC_CONT_CLOSE_ON_RESET" 16171265 "DTC_CONT_CLOSE_SIG_FAILED" 16171520 "DTC_PRECHARGE_TIMEOUT" 16171777 "DTC_CONT_MPOS_WELD_AT_SU" 16171778 "DTC_CONT_MNEG_WELD_AT_SU" 16171780 "DTC_CONT_CPOS_WELD_AT_SU" 16171781 "DTC_CONT_CNEG_WELD_AT_SU" 16171782 "DTC_CONT_ANEG_WELD_AT_SU" 16171783 "DTC_CONT_APOS_WELD_AT_SU" 16172033 "DTC_CONT_MPOS_WELD_AT_SD" 16172034 "DTC_CONT_MNEG_WELD_AT_SD" 16172036 "DTC_CONT_CPOS_WELD_AT_SD" 16172037 "DTC_CONT_CNEG_WELD_AT_SD" 16172038 "DTC_CONT_ANEG_WELD_AT_SD" 16172039 "DTC_CONT_APOS_WELD_AT_SD" 16172289 "DTC_CONT_MPOS_OPEN" 16172290 "DTC_CONT_MNEG_OPEN" 16172291 "DTC_CONT_MPRE_OPEN" 16172292 "DTC_CONT_CPOS_OPEN" 16172293 "DTC_CONT_CNEG_OPEN" 16172294 "DTC_CONT_APOS_OPEN" 16172295 "DTC_CONT_ANEG_OPEN" 16172545 "DTC_CONT_MPOS_VDIF" 16172546 "DTC_CONT_MNEG_VDIF" 16172548 "DTC_CONT_CPOS_VDIF" 16172549 "DTC_CONT_CNEG_VDIF" 16172550 "DTC_CONT_APOS_VDIF" 16172551 "DTC_CONT_ANEG_VDIF" 16174848 "DTC_HVIL" 16174849 "DTC_LVBAT_LO" 16174850 "DTC_LVBAT_HI" 16174851 "DTC_LVBAT_ERR" 16523520 "DTC_LEMLO_OOR_HI" 16523521 "DTC_LEMLO_OOR_LO" 16523522 "DTC_LEMLO_FAULT" 16523776 "DTC_LEMHI_OOR_HI" 16523777 "DTC_LEMHI_OOR_LO" 16523778 "DTC_LEMHI_FAULT" 16496320 "DTC_MBB_TOO_FEW" 16496321 "DTC_MBB_TOO_MANY" 16496352 "DTC_CELL_VMAX_ERR" 16496353 "DTC_CELL_VMIN_ERR" 16496354 "DTC_CELL_VMAX" 16496362 "DTC_CELL_VMAX_SEVERE" 16496355 "DTC_CELL_VMIN" 16496363 "DTC_CELL_VMIN_SEVERE" 16496356 "DTC_MOD_VOLTAGE_COMPARE" 16496336 "DTC_CELL_T_ERR" 16496337 "DTC_CELL_TMAX1" 16496338 "DTC_CELL_TMAX2" 16496339 "DTC_CELL_TMIN" 16497665 "DTC_MBB_01_MISSING" 16497666 "DTC_MBB_02_MISSING" 16497667 "DTC_MBB_03_MISSING" 16497668 "DTC_MBB_04_MISSING" 16497669 "DTC_MBB_05_MISSING" 16497670 "DTC_MBB_06_MISSING" 16497671 "DTC_MBB_07_MISSING" 16497672 "DTC_MBB_08_MISSING" 16497673 "DTC_MBB_09_MISSING" 16497680 "DTC_MBB_10_MISSING" 16497681 "DTC_MBB_11_MISSING" 16497682 "DTC_MBB_12_MISSING" 16497683 "DTC_MBB_13_MISSING" 16497684 "DTC_MBB_14_MISSING" 16497685 "DTC_MBB_15_MISSING" 16497686 "DTC_MBB_16_MISSING" 16497687 "DTC_MBB_17_MISSING" 16497688 "DTC_MBB_18_MISSING" 16497689 "DTC_MBB_19_MISSING" 16497696 "DTC_MBB_20_MISSING" 16497697 "DTC_MBB_21_MISSING" 16497698 "DTC_MBB_22_MISSING" 16497699 "DTC_MBB_23_MISSING" 16497700 "DTC_MBB_24_MISSING" 16498177 "DTC_MBB_01_VFAULT" 16498178 "DTC_MBB_02_VFAULT" 16498179 "DTC_MBB_03_VFAULT" 16498180 "DTC_MBB_04_VFAULT" 16498181 "DTC_MBB_05_VFAULT" 16498182 "DTC_MBB_06_VFAULT" 16498183 "DTC_MBB_07_VFAULT" 16498184 "DTC_MBB_08_VFAULT" 16498185 "DTC_MBB_09_VFAULT" 16498192 "DTC_MBB_10_VFAULT" 16498193 "DTC_MBB_11_VFAULT" 16498194 "DTC_MBB_12_VFAULT" 16498195 "DTC_MBB_13_VFAULT" 16498196 "DTC_MBB_14_VFAULT" 16498197 "DTC_MBB_15_VFAULT" 16498198 "DTC_MBB_16_VFAULT" 16498199 "DTC_MBB_17_VFAULT" 16498200 "DTC_MBB_18_VFAULT" 16498201 "DTC_MBB_19_VFAULT" 16498208 "DTC_MBB_20_VFAULT" 16498209 "DTC_MBB_21_VFAULT" 16498210 "DTC_MBB_22_VFAULT" 16498211 "DTC_MBB_23_VFAULT" 16498212 "DTC_MBB_24_VFAULT" 16497921 "DTC_MBB_01_TFAULT" 16497922 "DTC_MBB_02_TFAULT" 16497923 "DTC_MBB_03_TFAULT" 16497924 "DTC_MBB_04_TFAULT" 16497925 "DTC_MBB_05_TFAULT" 16497926 "DTC_MBB_06_TFAULT" 16497927 "DTC_MBB_07_TFAULT" 16497928 "DTC_MBB_08_TFAULT" 16497929 "DTC_MBB_09_TFAULT" 16497936 "DTC_MBB_10_TFAULT" 16497937 "DTC_MBB_11_TFAULT" 16497938 "DTC_MBB_12_TFAULT" 16497939 "DTC_MBB_13_TFAULT" 16497940 "DTC_MBB_14_TFAULT" 16497941 "DTC_MBB_15_TFAULT" 16497942 "DTC_MBB_16_TFAULT" 16497943 "DTC_MBB_17_TFAULT" 16497944 "DTC_MBB_18_TFAULT" 16497945 "DTC_MBB_19_TFAULT" 16497952 "DTC_MBB_20_TFAULT" 16497953 "DTC_MBB_21_TFAULT" 16497954 "DTC_MBB_22_TFAULT" 16497955 "DTC_MBB_23_TFAULT" 16497956 "DTC_MBB_24_TFAULT" 15785984 "DTC_PRECHARGE_ENERGY" 15785985 "DTC_PRT_FAILED" 15785986 "DTC_PRT_OVERTEMP" 15785987 "DTC_PRT_PROHIBIT" 16556032 "DTC_COOLANT_TEMP_OOR_HI" 16556033 "DTC_COOLANT_TEMP_OOR_LO" 16252928 "DTC_KEY_OFF_TIME_ERROR" 16506880 "DTC_VBAT_MISMATCH" 16506881 "DTC_VBAT_VMAX" 16506882 "DTC_VBAT_VMIN" 16506883 "DTC_PACK_FUSE" 15798544 "DTC_LLS1_OOR_HI" 15798545 "DTC_LLS1_OOR_LO" 15798546 "DTC_LLS1_FAULT" 15798816 "DTC_LLS2_OOR_HI" 15798817 "DTC_LLS2_OOR_LO" 15798818 "DTC_LLS2_FAULT" 14479360 "DTC_CFL_HEARTBEAT" 14479361 "DTC_CFL_FAULT" 14479362 "DTC_CFL_FAULT_LATCH" 13635584 "DTC_CONT_A_FAILED_HI" 13635585 "DTC_CONT_A_FAILED_LO" 13635586 "DTC_CONT_B_FAILED_HI" 13635587 "DTC_CONT_B_FAILED_LO" 13635588 "DTC_CONT_C_FAILED_HI" 13635589 "DTC_CONT_C_FAILED_LO" 13635590 "DTC_CONT_D_FAILED_HI" 13635591 "DTC_CONT_D_FAILED_LO" 13635592 "DTC_CONT_E_FAILED_HI" 13635593 "DTC_CONT_E_FAILED_LO" 13635594 "DTC_CONT_F_FAILED_HI" 13635595 "DTC_CONT_F_FAILED_LO" 13635596 "DTC_CONT_G_FAILED_HI" 13635597 "DTC_CONT_G_FAILED_LO" 13635598 "DTC_LSD_A_FAILED_HI" 13635599 "DTC_LSD_A_FAILED_LO" 13635600 "DTC_LSD_B_FAILED_HI" 13635601 "DTC_LSD_B_FAILED_LO" 13635602 "DTC_LSD_C_FAILED_HI" 13635603 "DTC_LSD_C_FAILED_LO" 13635606 "DTC_CONT_PWR_FAILED_HI" 13635607 "DTC_CONT_PWR_FAILED_LO" 13635608 "DTC_LSD_PUMP_FAILED_HI" 13635609 "DTC_LSD_PUMP_FAILED_LO" 13635610 "DTC_CHG_A_ENABLE_FAILED_HI" 13635611 "DTC_CHG_A_ENABLE_FAILED_LO" 13635612 "DTC_CHG_B_ENABLE_FAILED_HI" 13635613 "DTC_CHG_B_ENABLE_FAILED_LO" 13635614 "DTC_SW14V_PWR_FAILED_HI" 13635615 "DTC_SW14V_PWR_FAILED_LO" 13635620 "DTC_HSD_A_FAILED_HI" 13635621 "DTC_HSD_A_FAILED_LO" 13635622 "DTC_HSD_B_FAILED_HI" 13635623 "DTC_HSD_B_FAILED_LO" 13692968 "DTC_CONT_HPWR_FAILED_HI" 13692969 "DTC_CONT_HPWR_FAILED_LO" 13692970 "DTC_CONT_HPWR_OOR_HI" 13692971 "DTC_CONT_HPWR_OOR_LO" 13635616 "DTC_5V_PWR_OOR_HI" 13635617 "DTC_5V_PWR_OOR_LO" 14606336 "DTC_NVM_WRITE_TO" 14606337 "DTC_NVM_READ_TO" 14614528 "DTC_SPI_DIG_POT_FAULT" ;
VAL_ 1120 bcm_dtc_097 0 " - " 11276288 "DTC_VEPO" 11276289 "DTC_HSC_MISSING" 11460608 "DTC_NVM_SOC" 11460609 "DTC_NVM_KOT" 11460610 "DTC_NVM_DTC" 11460611 "DTC_NVM_SOC_CORRECTION" 11460612 "DTC_NVM_APP_SCRATCHPAD" 11517962 "DTC_LOOPTIME_TASK_A" 11517963 "DTC_LOOPTIME_TASK_B" 11517964 "DTC_LOOPTIME_TASK_C" 11517965 "DTC_LOOPTIME_TASK_D" 11517966 "DTC_LOOPTIME_TASK_E" 11517967 "DTC_LOOPTIME_TASK_F" 11323904 "DTC_INTERLOCK_A_FAILED_LOW" 11323905 "DTC_INTERLOCK_A_FAILED_HIGH" 11324160 "DTC_INTERLOCK_B_FAILED_LOW" 11324161 "DTC_INTERLOCK_B_FAILED_HIGH" 15728640 "DTC_EPO" 16498688 "DTC_BRUSA_MISSING" 16498689 "DTC_BRUSA_IDC" 16498690 "DTC_BRUSA_REQ_VS_CMD" 16433152 "DTC_AKERWADE_MISSING" 16433153 "DTC_AKERWADE_IDC" 16433154 "DTC_AKERWADE_REQ_VS_CMD" 16564224 "DTC_CHGLEAR_MISSING" 16564225 "DTC_CHGLEAR_IDC" 16564226 "DTC_CHGLEAR_REQ_VS_CMD" 16522240 "DTC_CSM_MISSING" 16522752 "DTC_CSM_VBAT" 16522753 "DTC_CSM_VPOS" 16522754 "DTC_CSM_VNEG" 16522755 "DTC_CSM_CPOS" 16522756 "DTC_CSM_CNEG" 16522757 "DTC_CSM_APOS" 16522758 "DTC_CSM_ANEG" 16522759 "DTC_CSM_FUSE_HI" 16522760 "DTC_CSM_FUSE_LO" 16521728 "DTC_CSM_ASIC" 16521729 "DTC_CSM_AILO" 16521730 "DTC_CSM_AIHI" 16520957 "DTC_LEAKAGE_DETECT_FAULT" 16522444 "DTC_REALTIMECLOCK_FAULT" 16520945 "DTC_CSM_LEAK_FAIL_CALC" 16520946 "DTC_CSM_LEAK_FAIL_HW" 16520947 "DTC_CSM_LEAK_EXT_SHORT" 16520948 "DTC_CSM_LEAK_MID_PACK_SHORT" 16520949 "DTC_CSM_LEAK_ERROR" 16520950 "DTC_CSM_LEAK_UNKNOWN" 16523008 "DTC_CSM_VER_MISMATCH" 16523009 "DTC_CSM_DTC_SET" 16523010 "DTC_CSM_CAL_FAULT" 16560128 "DTC_IBAT_MISMATCH" 16576512 "DTC_DIS_MAX_I2T" 16576513 "DTC_CHG_MAX_I2T" 16576768 "DTC_DIS_WARNING_I2T" 16576769 "DTC_CHG_WARNING_I2T" 11296784 "DTC_SAEJ1772_PROX_DECT_OOR_HI" 11296785 "DTC_SAEJ1772_PROX_DECT_OOR_LO" 11296800 "DTC_SAEJ1772_PILOT_PWM_OOR_HI" 11296801 "DTC_SAEJ1772_PILOT_PWM_OOR_LO" 11296802 "DTC_SAEJ1772_PILOT_PWM_DIG_COMM" 11296803 "DTC_SAEJ1772_PILOT_PWM_IR_ERR" 16175360 "DTC_FGD1_NO_SENSOR" 16175361 "DTC_FGD1_OOR_HI" 16175362 "DTC_FGD1_OOR_LO" 16175363 "DTC_FGD1_FAULT" 16175616 "DTC_FGD2_NO_SENSOR" 16175617 "DTC_FGD2_OOR_HI" 16175618 "DTC_FGD2_OOR_LO" 16175619 "DTC_FGD2_FAULT" 16171008 "DTC_CONT_OPEN" 16171009 "DTC_CONT_CLOSE" 16171010 "DTC_CONT_OPEN_CURRENT" 16171264 "DTC_CONT_CLOSE_ON_RESET" 16171265 "DTC_CONT_CLOSE_SIG_FAILED" 16171520 "DTC_PRECHARGE_TIMEOUT" 16171777 "DTC_CONT_MPOS_WELD_AT_SU" 16171778 "DTC_CONT_MNEG_WELD_AT_SU" 16171780 "DTC_CONT_CPOS_WELD_AT_SU" 16171781 "DTC_CONT_CNEG_WELD_AT_SU" 16171782 "DTC_CONT_ANEG_WELD_AT_SU" 16171783 "DTC_CONT_APOS_WELD_AT_SU" 16172033 "DTC_CONT_MPOS_WELD_AT_SD" 16172034 "DTC_CONT_MNEG_WELD_AT_SD" 16172036 "DTC_CONT_CPOS_WELD_AT_SD" 16172037 "DTC_CONT_CNEG_WELD_AT_SD" 16172038 "DTC_CONT_ANEG_WELD_AT_SD" 16172039 "DTC_CONT_APOS_WELD_AT_SD" 16172289 "DTC_CONT_MPOS_OPEN" 16172290 "DTC_CONT_MNEG_OPEN" 16172291 "DTC_CONT_MPRE_OPEN" 16172292 "DTC_CONT_CPOS_OPEN" 16172293 "DTC_CONT_CNEG_OPEN" 16172294 "DTC_CONT_APOS_OPEN" 16172295 "DTC_CONT_ANEG_OPEN" 16172545 "DTC_CONT_MPOS_VDIF" 16172546 "DTC_CONT_MNEG_VDIF" 16172548 "DTC_CONT_CPOS_VDIF" 16172549 "DTC_CONT_CNEG_VDIF" 16172550 "DTC_CONT_APOS_VDIF" 16172551 "DTC_CONT_ANEG_VDIF" 16174848 "DTC_HVIL" 16174849 "DTC_LVBAT_LO" 16174850 "DTC_LVBAT_HI" 16174851 "DTC_LVBAT_ERR" 16523520 "DTC_LEMLO_OOR_HI" 16523521 "DTC_LEMLO_OOR_LO" 16523522 "DTC_LEMLO_FAULT" 16523776 "DTC_LEMHI_OOR_HI" 16523777 "DTC_LEMHI_OOR_LO" 16523778 "DTC_LEMHI_FAULT" 16496320 "DTC_MBB_TOO_FEW" 16496321 "DTC_MBB_TOO_MANY" 16496352 "DTC_CELL_VMAX_ERR" 16496353 "DTC_CELL_VMIN_ERR" 16496354 "DTC_CELL_VMAX" 16496362 "DTC_CELL_VMAX_SEVERE" 16496355 "DTC_CELL_VMIN" 16496363 "DTC_CELL_VMIN_SEVERE" 16496356 "DTC_MOD_VOLTAGE_COMPARE" 16496336 "DTC_CELL_T_ERR" 16496337 "DTC_CELL_TMAX1" 16496338 "DTC_CELL_TMAX2" 16496339 "DTC_CELL_TMIN" 16497665 "DTC_MBB_01_MISSING" 16497666 "DTC_MBB_02_MISSING" 16497667 "DTC_MBB_03_MISSING" 16497668 "DTC_MBB_04_MISSING" 16497669 "DTC_MBB_05_MISSING" 16497670 "DTC_MBB_06_MISSING" 16497671 "DTC_MBB_07_MISSING" 16497672 "DTC_MBB_08_MISSING" 16497673 "DTC_MBB_09_MISSING" 16497680 "DTC_MBB_10_MISSING" 16497681 "DTC_MBB_11_MISSING" 16497682 "DTC_MBB_12_MISSING" 16497683 "DTC_MBB_13_MISSING" 16497684 "DTC_MBB_14_MISSING" 16497685 "DTC_MBB_15_MISSING" 16497686 "DTC_MBB_16_MISSING" 16497687 "DTC_MBB_17_MISSING" 16497688 "DTC_MBB_18_MISSING" 16497689 "DTC_MBB_19_MISSING" 16497696 "DTC_MBB_20_MISSING" 16497697 "DTC_MBB_21_MISSING" 16497698 "DTC_MBB_22_MISSING" 16497699 "DTC_MBB_23_MISSING" 16497700 "DTC_MBB_24_MISSING" 16498177 "DTC_MBB_01_VFAULT" 16498178 "DTC_MBB_02_VFAULT" 16498179 "DTC_MBB_03_VFAULT" 16498180 "DTC_MBB_04_VFAULT" 16498181 "DTC_MBB_05_VFAULT" 16498182 "DTC_MBB_06_VFAULT" 16498183 "DTC_MBB_07_VFAULT" 16498184 "DTC_MBB_08_VFAULT" 16498185 "DTC_MBB_09_VFAULT" 16498192 "DTC_MBB_10_VFAULT" 16498193 "DTC_MBB_11_VFAULT" 16498194 "DTC_MBB_12_VFAULT" 16498195 "DTC_MBB_13_VFAULT" 16498196 "DTC_MBB_14_VFAULT" 16498197 "DTC_MBB_15_VFAULT" 16498198 "DTC_MBB_16_VFAULT" 16498199 "DTC_MBB_17_VFAULT" 16498200 "DTC_MBB_18_VFAULT" 16498201 "DTC_MBB_19_VFAULT" 16498208 "DTC_MBB_20_VFAULT" 16498209 "DTC_MBB_21_VFAULT" 16498210 "DTC_MBB_22_VFAULT" 16498211 "DTC_MBB_23_VFAULT" 16498212 "DTC_MBB_24_VFAULT" 16497921 "DTC_MBB_01_TFAULT" 16497922 "DTC_MBB_02_TFAULT" 16497923 "DTC_MBB_03_TFAULT" 16497924 "DTC_MBB_04_TFAULT" 16497925 "DTC_MBB_05_TFAULT" 16497926 "DTC_MBB_06_TFAULT" 16497927 "DTC_MBB_07_TFAULT" 16497928 "DTC_MBB_08_TFAULT" 16497929 "DTC_MBB_09_TFAULT" 16497936 "DTC_MBB_10_TFAULT" 16497937 "DTC_MBB_11_TFAULT" 16497938 "DTC_MBB_12_TFAULT" 16497939 "DTC_MBB_13_TFAULT" 16497940 "DTC_MBB_14_TFAULT" 16497941 "DTC_MBB_15_TFAULT" 16497942 "DTC_MBB_16_TFAULT" 16497943 "DTC_MBB_17_TFAULT" 16497944 "DTC_MBB_18_TFAULT" 16497945 "DTC_MBB_19_TFAULT" 16497952 "DTC_MBB_20_TFAULT" 16497953 "DTC_MBB_21_TFAULT" 16497954 "DTC_MBB_22_TFAULT" 16497955 "DTC_MBB_23_TFAULT" 16497956 "DTC_MBB_24_TFAULT" 15785984 "DTC_PRECHARGE_ENERGY" 15785985 "DTC_PRT_FAILED" 15785986 "DTC_PRT_OVERTEMP" 15785987 "DTC_PRT_PROHIBIT" 16556032 "DTC_COOLANT_TEMP_OOR_HI" 16556033 "DTC_COOLANT_TEMP_OOR_LO" 16252928 "DTC_KEY_OFF_TIME_ERROR" 16506880 "DTC_VBAT_MISMATCH" 16506881 "DTC_VBAT_VMAX" 16506882 "DTC_VBAT_VMIN" 16506883 "DTC_PACK_FUSE" 15798544 "DTC_LLS1_OOR_HI" 15798545 "DTC_LLS1_OOR_LO" 15798546 "DTC_LLS1_FAULT" 15798816 "DTC_LLS2_OOR_HI" 15798817 "DTC_LLS2_OOR_LO" 15798818 "DTC_LLS2_FAULT" 14479360 "DTC_CFL_HEARTBEAT" 14479361 "DTC_CFL_FAULT" 14479362 "DTC_CFL_FAULT_LATCH" 13635584 "DTC_CONT_A_FAILED_HI" 13635585 "DTC_CONT_A_FAILED_LO" 13635586 "DTC_CONT_B_FAILED_HI" 13635587 "DTC_CONT_B_FAILED_LO" 13635588 "DTC_CONT_C_FAILED_HI" 13635589 "DTC_CONT_C_FAILED_LO" 13635590 "DTC_CONT_D_FAILED_HI" 13635591 "DTC_CONT_D_FAILED_LO" 13635592 "DTC_CONT_E_FAILED_HI" 13635593 "DTC_CONT_E_FAILED_LO" 13635594 "DTC_CONT_F_FAILED_HI" 13635595 "DTC_CONT_F_FAILED_LO" 13635596 "DTC_CONT_G_FAILED_HI" 13635597 "DTC_CONT_G_FAILED_LO" 13635598 "DTC_LSD_A_FAILED_HI" 13635599 "DTC_LSD_A_FAILED_LO" 13635600 "DTC_LSD_B_FAILED_HI" 13635601 "DTC_LSD_B_FAILED_LO" 13635602 "DTC_LSD_C_FAILED_HI" 13635603 "DTC_LSD_C_FAILED_LO" 13635606 "DTC_CONT_PWR_FAILED_HI" 13635607 "DTC_CONT_PWR_FAILED_LO" 13635608 "DTC_LSD_PUMP_FAILED_HI" 13635609 "DTC_LSD_PUMP_FAILED_LO" 13635610 "DTC_CHG_A_ENABLE_FAILED_HI" 13635611 "DTC_CHG_A_ENABLE_FAILED_LO" 13635612 "DTC_CHG_B_ENABLE_FAILED_HI" 13635613 "DTC_CHG_B_ENABLE_FAILED_LO" 13635614 "DTC_SW14V_PWR_FAILED_HI" 13635615 "DTC_SW14V_PWR_FAILED_LO" 13635620 "DTC_HSD_A_FAILED_HI" 13635621 "DTC_HSD_A_FAILED_LO" 13635622 "DTC_HSD_B_FAILED_HI" 13635623 "DTC_HSD_B_FAILED_LO" 13692968 "DTC_CONT_HPWR_FAILED_HI" 13692969 "DTC_CONT_HPWR_FAILED_LO" 13692970 "DTC_CONT_HPWR_OOR_HI" 13692971 "DTC_CONT_HPWR_OOR_LO" 13635616 "DTC_5V_PWR_OOR_HI" 13635617 "DTC_5V_PWR_OOR_LO" 14606336 "DTC_NVM_WRITE_TO" 14606337 "DTC_NVM_READ_TO" 14614528 "DTC_SPI_DIG_POT_FAULT" ;
VAL_ 1120 bcm_dtc_098 0 " - " 11276288 "DTC_VEPO" 11276289 "DTC_HSC_MISSING" 11460608 "DTC_NVM_SOC" 11460609 "DTC_NVM_KOT" 11460610 "DTC_NVM_DTC" 11460611 "DTC_NVM_SOC_CORRECTION" 11460612 "DTC_NVM_APP_SCRATCHPAD" 11517962 "DTC_LOOPTIME_TASK_A" 11517963 "DTC_LOOPTIME_TASK_B" 11517964 "DTC_LOOPTIME_TASK_C" 11517965 "DTC_LOOPTIME_TASK_D" 11517966 "DTC_LOOPTIME_TASK_E" 11517967 "DTC_LOOPTIME_TASK_F" 11323904 "DTC_INTERLOCK_A_FAILED_LOW" 11323905 "DTC_INTERLOCK_A_FAILED_HIGH" 11324160 "DTC_INTERLOCK_B_FAILED_LOW" 11324161 "DTC_INTERLOCK_B_FAILED_HIGH" 15728640 "DTC_EPO" 16498688 "DTC_BRUSA_MISSING" 16498689 "DTC_BRUSA_IDC" 16498690 "DTC_BRUSA_REQ_VS_CMD" 16433152 "DTC_AKERWADE_MISSING" 16433153 "DTC_AKERWADE_IDC" 16433154 "DTC_AKERWADE_REQ_VS_CMD" 16564224 "DTC_CHGLEAR_MISSING" 16564225 "DTC_CHGLEAR_IDC" 16564226 "DTC_CHGLEAR_REQ_VS_CMD" 16522240 "DTC_CSM_MISSING" 16522752 "DTC_CSM_VBAT" 16522753 "DTC_CSM_VPOS" 16522754 "DTC_CSM_VNEG" 16522755 "DTC_CSM_CPOS" 16522756 "DTC_CSM_CNEG" 16522757 "DTC_CSM_APOS" 16522758 "DTC_CSM_ANEG" 16522759 "DTC_CSM_FUSE_HI" 16522760 "DTC_CSM_FUSE_LO" 16521728 "DTC_CSM_ASIC" 16521729 "DTC_CSM_AILO" 16521730 "DTC_CSM_AIHI" 16520957 "DTC_LEAKAGE_DETECT_FAULT" 16522444 "DTC_REALTIMECLOCK_FAULT" 16520945 "DTC_CSM_LEAK_FAIL_CALC" 16520946 "DTC_CSM_LEAK_FAIL_HW" 16520947 "DTC_CSM_LEAK_EXT_SHORT" 16520948 "DTC_CSM_LEAK_MID_PACK_SHORT" 16520949 "DTC_CSM_LEAK_ERROR" 16520950 "DTC_CSM_LEAK_UNKNOWN" 16523008 "DTC_CSM_VER_MISMATCH" 16523009 "DTC_CSM_DTC_SET" 16523010 "DTC_CSM_CAL_FAULT" 16560128 "DTC_IBAT_MISMATCH" 16576512 "DTC_DIS_MAX_I2T" 16576513 "DTC_CHG_MAX_I2T" 16576768 "DTC_DIS_WARNING_I2T" 16576769 "DTC_CHG_WARNING_I2T" 11296784 "DTC_SAEJ1772_PROX_DECT_OOR_HI" 11296785 "DTC_SAEJ1772_PROX_DECT_OOR_LO" 11296800 "DTC_SAEJ1772_PILOT_PWM_OOR_HI" 11296801 "DTC_SAEJ1772_PILOT_PWM_OOR_LO" 11296802 "DTC_SAEJ1772_PILOT_PWM_DIG_COMM" 11296803 "DTC_SAEJ1772_PILOT_PWM_IR_ERR" 16175360 "DTC_FGD1_NO_SENSOR" 16175361 "DTC_FGD1_OOR_HI" 16175362 "DTC_FGD1_OOR_LO" 16175363 "DTC_FGD1_FAULT" 16175616 "DTC_FGD2_NO_SENSOR" 16175617 "DTC_FGD2_OOR_HI" 16175618 "DTC_FGD2_OOR_LO" 16175619 "DTC_FGD2_FAULT" 16171008 "DTC_CONT_OPEN" 16171009 "DTC_CONT_CLOSE" 16171010 "DTC_CONT_OPEN_CURRENT" 16171264 "DTC_CONT_CLOSE_ON_RESET" 16171265 "DTC_CONT_CLOSE_SIG_FAILED" 16171520 "DTC_PRECHARGE_TIMEOUT" 16171777 "DTC_CONT_MPOS_WELD_AT_SU" 16171778 "DTC_CONT_MNEG_WELD_AT_SU" 16171780 "DTC_CONT_CPOS_WELD_AT_SU" 16171781 "DTC_CONT_CNEG_WELD_AT_SU" 16171782 "DTC_CONT_ANEG_WELD_AT_SU" 16171783 "DTC_CONT_APOS_WELD_AT_SU" 16172033 "DTC_CONT_MPOS_WELD_AT_SD" 16172034 "DTC_CONT_MNEG_WELD_AT_SD" 16172036 "DTC_CONT_CPOS_WELD_AT_SD" 16172037 "DTC_CONT_CNEG_WELD_AT_SD" 16172038 "DTC_CONT_ANEG_WELD_AT_SD" 16172039 "DTC_CONT_APOS_WELD_AT_SD" 16172289 "DTC_CONT_MPOS_OPEN" 16172290 "DTC_CONT_MNEG_OPEN" 16172291 "DTC_CONT_MPRE_OPEN" 16172292 "DTC_CONT_CPOS_OPEN" 16172293 "DTC_CONT_CNEG_OPEN" 16172294 "DTC_CONT_APOS_OPEN" 16172295 "DTC_CONT_ANEG_OPEN" 16172545 "DTC_CONT_MPOS_VDIF" 16172546 "DTC_CONT_MNEG_VDIF" 16172548 "DTC_CONT_CPOS_VDIF" 16172549 "DTC_CONT_CNEG_VDIF" 16172550 "DTC_CONT_APOS_VDIF" 16172551 "DTC_CONT_ANEG_VDIF" 16174848 "DTC_HVIL" 16174849 "DTC_LVBAT_LO" 16174850 "DTC_LVBAT_HI" 16174851 "DTC_LVBAT_ERR" 16523520 "DTC_LEMLO_OOR_HI" 16523521 "DTC_LEMLO_OOR_LO" 16523522 "DTC_LEMLO_FAULT" 16523776 "DTC_LEMHI_OOR_HI" 16523777 "DTC_LEMHI_OOR_LO" 16523778 "DTC_LEMHI_FAULT" 16496320 "DTC_MBB_TOO_FEW" 16496321 "DTC_MBB_TOO_MANY" 16496352 "DTC_CELL_VMAX_ERR" 16496353 "DTC_CELL_VMIN_ERR" 16496354 "DTC_CELL_VMAX" 16496362 "DTC_CELL_VMAX_SEVERE" 16496355 "DTC_CELL_VMIN" 16496363 "DTC_CELL_VMIN_SEVERE" 16496356 "DTC_MOD_VOLTAGE_COMPARE" 16496336 "DTC_CELL_T_ERR" 16496337 "DTC_CELL_TMAX1" 16496338 "DTC_CELL_TMAX2" 16496339 "DTC_CELL_TMIN" 16497665 "DTC_MBB_01_MISSING" 16497666 "DTC_MBB_02_MISSING" 16497667 "DTC_MBB_03_MISSING" 16497668 "DTC_MBB_04_MISSING" 16497669 "DTC_MBB_05_MISSING" 16497670 "DTC_MBB_06_MISSING" 16497671 "DTC_MBB_07_MISSING" 16497672 "DTC_MBB_08_MISSING" 16497673 "DTC_MBB_09_MISSING" 16497680 "DTC_MBB_10_MISSING" 16497681 "DTC_MBB_11_MISSING" 16497682 "DTC_MBB_12_MISSING" 16497683 "DTC_MBB_13_MISSING" 16497684 "DTC_MBB_14_MISSING" 16497685 "DTC_MBB_15_MISSING" 16497686 "DTC_MBB_16_MISSING" 16497687 "DTC_MBB_17_MISSING" 16497688 "DTC_MBB_18_MISSING" 16497689 "DTC_MBB_19_MISSING" 16497696 "DTC_MBB_20_MISSING" 16497697 "DTC_MBB_21_MISSING" 16497698 "DTC_MBB_22_MISSING" 16497699 "DTC_MBB_23_MISSING" 16497700 "DTC_MBB_24_MISSING" 16498177 "DTC_MBB_01_VFAULT" 16498178 "DTC_MBB_02_VFAULT" 16498179 "DTC_MBB_03_VFAULT" 16498180 "DTC_MBB_04_VFAULT" 16498181 "DTC_MBB_05_VFAULT" 16498182 "DTC_MBB_06_VFAULT" 16498183 "DTC_MBB_07_VFAULT" 16498184 "DTC_MBB_08_VFAULT" 16498185 "DTC_MBB_09_VFAULT" 16498192 "DTC_MBB_10_VFAULT" 16498193 "DTC_MBB_11_VFAULT" 16498194 "DTC_MBB_12_VFAULT" 16498195 "DTC_MBB_13_VFAULT" 16498196 "DTC_MBB_14_VFAULT" 16498197 "DTC_MBB_15_VFAULT" 16498198 "DTC_MBB_16_VFAULT" 16498199 "DTC_MBB_17_VFAULT" 16498200 "DTC_MBB_18_VFAULT" 16498201 "DTC_MBB_19_VFAULT" 16498208 "DTC_MBB_20_VFAULT" 16498209 "DTC_MBB_21_VFAULT" 16498210 "DTC_MBB_22_VFAULT" 16498211 "DTC_MBB_23_VFAULT" 16498212 "DTC_MBB_24_VFAULT" 16497921 "DTC_MBB_01_TFAULT" 16497922 "DTC_MBB_02_TFAULT" 16497923 "DTC_MBB_03_TFAULT" 16497924 "DTC_MBB_04_TFAULT" 16497925 "DTC_MBB_05_TFAULT" 16497926 "DTC_MBB_06_TFAULT" 16497927 "DTC_MBB_07_TFAULT" 16497928 "DTC_MBB_08_TFAULT" 16497929 "DTC_MBB_09_TFAULT" 16497936 "DTC_MBB_10_TFAULT" 16497937 "DTC_MBB_11_TFAULT" 16497938 "DTC_MBB_12_TFAULT" 16497939 "DTC_MBB_13_TFAULT" 16497940 "DTC_MBB_14_TFAULT" 16497941 "DTC_MBB_15_TFAULT" 16497942 "DTC_MBB_16_TFAULT" 16497943 "DTC_MBB_17_TFAULT" 16497944 "DTC_MBB_18_TFAULT" 16497945 "DTC_MBB_19_TFAULT" 16497952 "DTC_MBB_20_TFAULT" 16497953 "DTC_MBB_21_TFAULT" 16497954 "DTC_MBB_22_TFAULT" 16497955 "DTC_MBB_23_TFAULT" 16497956 "DTC_MBB_24_TFAULT" 15785984 "DTC_PRECHARGE_ENERGY" 15785985 "DTC_PRT_FAILED" 15785986 "DTC_PRT_OVERTEMP" 15785987 "DTC_PRT_PROHIBIT" 16556032 "DTC_COOLANT_TEMP_OOR_HI" 16556033 "DTC_COOLANT_TEMP_OOR_LO" 16252928 "DTC_KEY_OFF_TIME_ERROR" 16506880 "DTC_VBAT_MISMATCH" 16506881 "DTC_VBAT_VMAX" 16506882 "DTC_VBAT_VMIN" 16506883 "DTC_PACK_FUSE" 15798544 "DTC_LLS1_OOR_HI" 15798545 "DTC_LLS1_OOR_LO" 15798546 "DTC_LLS1_FAULT" 15798816 "DTC_LLS2_OOR_HI" 15798817 "DTC_LLS2_OOR_LO" 15798818 "DTC_LLS2_FAULT" 14479360 "DTC_CFL_HEARTBEAT" 14479361 "DTC_CFL_FAULT" 14479362 "DTC_CFL_FAULT_LATCH" 13635584 "DTC_CONT_A_FAILED_HI" 13635585 "DTC_CONT_A_FAILED_LO" 13635586 "DTC_CONT_B_FAILED_HI" 13635587 "DTC_CONT_B_FAILED_LO" 13635588 "DTC_CONT_C_FAILED_HI" 13635589 "DTC_CONT_C_FAILED_LO" 13635590 "DTC_CONT_D_FAILED_HI" 13635591 "DTC_CONT_D_FAILED_LO" 13635592 "DTC_CONT_E_FAILED_HI" 13635593 "DTC_CONT_E_FAILED_LO" 13635594 "DTC_CONT_F_FAILED_HI" 13635595 "DTC_CONT_F_FAILED_LO" 13635596 "DTC_CONT_G_FAILED_HI" 13635597 "DTC_CONT_G_FAILED_LO" 13635598 "DTC_LSD_A_FAILED_HI" 13635599 "DTC_LSD_A_FAILED_LO" 13635600 "DTC_LSD_B_FAILED_HI" 13635601 "DTC_LSD_B_FAILED_LO" 13635602 "DTC_LSD_C_FAILED_HI" 13635603 "DTC_LSD_C_FAILED_LO" 13635606 "DTC_CONT_PWR_FAILED_HI" 13635607 "DTC_CONT_PWR_FAILED_LO" 13635608 "DTC_LSD_PUMP_FAILED_HI" 13635609 "DTC_LSD_PUMP_FAILED_LO" 13635610 "DTC_CHG_A_ENABLE_FAILED_HI" 13635611 "DTC_CHG_A_ENABLE_FAILED_LO" 13635612 "DTC_CHG_B_ENABLE_FAILED_HI" 13635613 "DTC_CHG_B_ENABLE_FAILED_LO" 13635614 "DTC_SW14V_PWR_FAILED_HI" 13635615 "DTC_SW14V_PWR_FAILED_LO" 13635620 "DTC_HSD_A_FAILED_HI" 13635621 "DTC_HSD_A_FAILED_LO" 13635622 "DTC_HSD_B_FAILED_HI" 13635623 "DTC_HSD_B_FAILED_LO" 13692968 "DTC_CONT_HPWR_FAILED_HI" 13692969 "DTC_CONT_HPWR_FAILED_LO" 13692970 "DTC_CONT_HPWR_OOR_HI" 13692971 "DTC_CONT_HPWR_OOR_LO" 13635616 "DTC_5V_PWR_OOR_HI" 13635617 "DTC_5V_PWR_OOR_LO" 14606336 "DTC_NVM_WRITE_TO" 14606337 "DTC_NVM_READ_TO" 14614528 "DTC_SPI_DIG_POT_FAULT" ;
VAL_ 1120 bcm_dtc_099 0 " - " 11276288 "DTC_VEPO" 11276289 "DTC_HSC_MISSING" 11460608 "DTC_NVM_SOC" 11460609 "DTC_NVM_KOT" 11460610 "DTC_NVM_DTC" 11460611 "DTC_NVM_SOC_CORRECTION" 11460612 "DTC_NVM_APP_SCRATCHPAD" 11517962 "DTC_LOOPTIME_TASK_A" 11517963 "DTC_LOOPTIME_TASK_B" 11517964 "DTC_LOOPTIME_TASK_C" 11517965 "DTC_LOOPTIME_TASK_D" 11517966 "DTC_LOOPTIME_TASK_E" 11517967 "DTC_LOOPTIME_TASK_F" 11323904 "DTC_INTERLOCK_A_FAILED_LOW" 11323905 "DTC_INTERLOCK_A_FAILED_HIGH" 11324160 "DTC_INTERLOCK_B_FAILED_LOW" 11324161 "DTC_INTERLOCK_B_FAILED_HIGH" 15728640 "DTC_EPO" 16498688 "DTC_BRUSA_MISSING" 16498689 "DTC_BRUSA_IDC" 16498690 "DTC_BRUSA_REQ_VS_CMD" 16433152 "DTC_AKERWADE_MISSING" 16433153 "DTC_AKERWADE_IDC" 16433154 "DTC_AKERWADE_REQ_VS_CMD" 16564224 "DTC_CHGLEAR_MISSING" 16564225 "DTC_CHGLEAR_IDC" 16564226 "DTC_CHGLEAR_REQ_VS_CMD" 16522240 "DTC_CSM_MISSING" 16522752 "DTC_CSM_VBAT" 16522753 "DTC_CSM_VPOS" 16522754 "DTC_CSM_VNEG" 16522755 "DTC_CSM_CPOS" 16522756 "DTC_CSM_CNEG" 16522757 "DTC_CSM_APOS" 16522758 "DTC_CSM_ANEG" 16522759 "DTC_CSM_FUSE_HI" 16522760 "DTC_CSM_FUSE_LO" 16521728 "DTC_CSM_ASIC" 16521729 "DTC_CSM_AILO" 16521730 "DTC_CSM_AIHI" 16520957 "DTC_LEAKAGE_DETECT_FAULT" 16522444 "DTC_REALTIMECLOCK_FAULT" 16520945 "DTC_CSM_LEAK_FAIL_CALC" 16520946 "DTC_CSM_LEAK_FAIL_HW" 16520947 "DTC_CSM_LEAK_EXT_SHORT" 16520948 "DTC_CSM_LEAK_MID_PACK_SHORT" 16520949 "DTC_CSM_LEAK_ERROR" 16520950 "DTC_CSM_LEAK_UNKNOWN" 16523008 "DTC_CSM_VER_MISMATCH" 16523009 "DTC_CSM_DTC_SET" 16523010 "DTC_CSM_CAL_FAULT" 16560128 "DTC_IBAT_MISMATCH" 16576512 "DTC_DIS_MAX_I2T" 16576513 "DTC_CHG_MAX_I2T" 16576768 "DTC_DIS_WARNING_I2T" 16576769 "DTC_CHG_WARNING_I2T" 11296784 "DTC_SAEJ1772_PROX_DECT_OOR_HI" 11296785 "DTC_SAEJ1772_PROX_DECT_OOR_LO" 11296800 "DTC_SAEJ1772_PILOT_PWM_OOR_HI" 11296801 "DTC_SAEJ1772_PILOT_PWM_OOR_LO" 11296802 "DTC_SAEJ1772_PILOT_PWM_DIG_COMM" 11296803 "DTC_SAEJ1772_PILOT_PWM_IR_ERR" 16175360 "DTC_FGD1_NO_SENSOR" 16175361 "DTC_FGD1_OOR_HI" 16175362 "DTC_FGD1_OOR_LO" 16175363 "DTC_FGD1_FAULT" 16175616 "DTC_FGD2_NO_SENSOR" 16175617 "DTC_FGD2_OOR_HI" 16175618 "DTC_FGD2_OOR_LO" 16175619 "DTC_FGD2_FAULT" 16171008 "DTC_CONT_OPEN" 16171009 "DTC_CONT_CLOSE" 16171010 "DTC_CONT_OPEN_CURRENT" 16171264 "DTC_CONT_CLOSE_ON_RESET" 16171265 "DTC_CONT_CLOSE_SIG_FAILED" 16171520 "DTC_PRECHARGE_TIMEOUT" 16171777 "DTC_CONT_MPOS_WELD_AT_SU" 16171778 "DTC_CONT_MNEG_WELD_AT_SU" 16171780 "DTC_CONT_CPOS_WELD_AT_SU" 16171781 "DTC_CONT_CNEG_WELD_AT_SU" 16171782 "DTC_CONT_ANEG_WELD_AT_SU" 16171783 "DTC_CONT_APOS_WELD_AT_SU" 16172033 "DTC_CONT_MPOS_WELD_AT_SD" 16172034 "DTC_CONT_MNEG_WELD_AT_SD" 16172036 "DTC_CONT_CPOS_WELD_AT_SD" 16172037 "DTC_CONT_CNEG_WELD_AT_SD" 16172038 "DTC_CONT_ANEG_WELD_AT_SD" 16172039 "DTC_CONT_APOS_WELD_AT_SD" 16172289 "DTC_CONT_MPOS_OPEN" 16172290 "DTC_CONT_MNEG_OPEN" 16172291 "DTC_CONT_MPRE_OPEN" 16172292 "DTC_CONT_CPOS_OPEN" 16172293 "DTC_CONT_CNEG_OPEN" 16172294 "DTC_CONT_APOS_OPEN" 16172295 "DTC_CONT_ANEG_OPEN" 16172545 "DTC_CONT_MPOS_VDIF" 16172546 "DTC_CONT_MNEG_VDIF" 16172548 "DTC_CONT_CPOS_VDIF" 16172549 "DTC_CONT_CNEG_VDIF" 16172550 "DTC_CONT_APOS_VDIF" 16172551 "DTC_CONT_ANEG_VDIF" 16174848 "DTC_HVIL" 16174849 "DTC_LVBAT_LO" 16174850 "DTC_LVBAT_HI" 16174851 "DTC_LVBAT_ERR" 16523520 "DTC_LEMLO_OOR_HI" 16523521 "DTC_LEMLO_OOR_LO" 16523522 "DTC_LEMLO_FAULT" 16523776 "DTC_LEMHI_OOR_HI" 16523777 "DTC_LEMHI_OOR_LO" 16523778 "DTC_LEMHI_FAULT" 16496320 "DTC_MBB_TOO_FEW" 16496321 "DTC_MBB_TOO_MANY" 16496352 "DTC_CELL_VMAX_ERR" 16496353 "DTC_CELL_VMIN_ERR" 16496354 "DTC_CELL_VMAX" 16496362 "DTC_CELL_VMAX_SEVERE" 16496355 "DTC_CELL_VMIN" 16496363 "DTC_CELL_VMIN_SEVERE" 16496356 "DTC_MOD_VOLTAGE_COMPARE" 16496336 "DTC_CELL_T_ERR" 16496337 "DTC_CELL_TMAX1" 16496338 "DTC_CELL_TMAX2" 16496339 "DTC_CELL_TMIN" 16497665 "DTC_MBB_01_MISSING" 16497666 "DTC_MBB_02_MISSING" 16497667 "DTC_MBB_03_MISSING" 16497668 "DTC_MBB_04_MISSING" 16497669 "DTC_MBB_05_MISSING" 16497670 "DTC_MBB_06_MISSING" 16497671 "DTC_MBB_07_MISSING" 16497672 "DTC_MBB_08_MISSING" 16497673 "DTC_MBB_09_MISSING" 16497680 "DTC_MBB_10_MISSING" 16497681 "DTC_MBB_11_MISSING" 16497682 "DTC_MBB_12_MISSING" 16497683 "DTC_MBB_13_MISSING" 16497684 "DTC_MBB_14_MISSING" 16497685 "DTC_MBB_15_MISSING" 16497686 "DTC_MBB_16_MISSING" 16497687 "DTC_MBB_17_MISSING" 16497688 "DTC_MBB_18_MISSING" 16497689 "DTC_MBB_19_MISSING" 16497696 "DTC_MBB_20_MISSING" 16497697 "DTC_MBB_21_MISSING" 16497698 "DTC_MBB_22_MISSING" 16497699 "DTC_MBB_23_MISSING" 16497700 "DTC_MBB_24_MISSING" 16498177 "DTC_MBB_01_VFAULT" 16498178 "DTC_MBB_02_VFAULT" 16498179 "DTC_MBB_03_VFAULT" 16498180 "DTC_MBB_04_VFAULT" 16498181 "DTC_MBB_05_VFAULT" 16498182 "DTC_MBB_06_VFAULT" 16498183 "DTC_MBB_07_VFAULT" 16498184 "DTC_MBB_08_VFAULT" 16498185 "DTC_MBB_09_VFAULT" 16498192 "DTC_MBB_10_VFAULT" 16498193 "DTC_MBB_11_VFAULT" 16498194 "DTC_MBB_12_VFAULT" 16498195 "DTC_MBB_13_VFAULT" 16498196 "DTC_MBB_14_VFAULT" 16498197 "DTC_MBB_15_VFAULT" 16498198 "DTC_MBB_16_VFAULT" 16498199 "DTC_MBB_17_VFAULT" 16498200 "DTC_MBB_18_VFAULT" 16498201 "DTC_MBB_19_VFAULT" 16498208 "DTC_MBB_20_VFAULT" 16498209 "DTC_MBB_21_VFAULT" 16498210 "DTC_MBB_22_VFAULT" 16498211 "DTC_MBB_23_VFAULT" 16498212 "DTC_MBB_24_VFAULT" 16497921 "DTC_MBB_01_TFAULT" 16497922 "DTC_MBB_02_TFAULT" 16497923 "DTC_MBB_03_TFAULT" 16497924 "DTC_MBB_04_TFAULT" 16497925 "DTC_MBB_05_TFAULT" 16497926 "DTC_MBB_06_TFAULT" 16497927 "DTC_MBB_07_TFAULT" 16497928 "DTC_MBB_08_TFAULT" 16497929 "DTC_MBB_09_TFAULT" 16497936 "DTC_MBB_10_TFAULT" 16497937 "DTC_MBB_11_TFAULT" 16497938 "DTC_MBB_12_TFAULT" 16497939 "DTC_MBB_13_TFAULT" 16497940 "DTC_MBB_14_TFAULT" 16497941 "DTC_MBB_15_TFAULT" 16497942 "DTC_MBB_16_TFAULT" 16497943 "DTC_MBB_17_TFAULT" 16497944 "DTC_MBB_18_TFAULT" 16497945 "DTC_MBB_19_TFAULT" 16497952 "DTC_MBB_20_TFAULT" 16497953 "DTC_MBB_21_TFAULT" 16497954 "DTC_MBB_22_TFAULT" 16497955 "DTC_MBB_23_TFAULT" 16497956 "DTC_MBB_24_TFAULT" 15785984 "DTC_PRECHARGE_ENERGY" 15785985 "DTC_PRT_FAILED" 15785986 "DTC_PRT_OVERTEMP" 15785987 "DTC_PRT_PROHIBIT" 16556032 "DTC_COOLANT_TEMP_OOR_HI" 16556033 "DTC_COOLANT_TEMP_OOR_LO" 16252928 "DTC_KEY_OFF_TIME_ERROR" 16506880 "DTC_VBAT_MISMATCH" 16506881 "DTC_VBAT_VMAX" 16506882 "DTC_VBAT_VMIN" 16506883 "DTC_PACK_FUSE" 15798544 "DTC_LLS1_OOR_HI" 15798545 "DTC_LLS1_OOR_LO" 15798546 "DTC_LLS1_FAULT" 15798816 "DTC_LLS2_OOR_HI" 15798817 "DTC_LLS2_OOR_LO" 15798818 "DTC_LLS2_FAULT" 14479360 "DTC_CFL_HEARTBEAT" 14479361 "DTC_CFL_FAULT" 14479362 "DTC_CFL_FAULT_LATCH" 13635584 "DTC_CONT_A_FAILED_HI" 13635585 "DTC_CONT_A_FAILED_LO" 13635586 "DTC_CONT_B_FAILED_HI" 13635587 "DTC_CONT_B_FAILED_LO" 13635588 "DTC_CONT_C_FAILED_HI" 13635589 "DTC_CONT_C_FAILED_LO" 13635590 "DTC_CONT_D_FAILED_HI" 13635591 "DTC_CONT_D_FAILED_LO" 13635592 "DTC_CONT_E_FAILED_HI" 13635593 "DTC_CONT_E_FAILED_LO" 13635594 "DTC_CONT_F_FAILED_HI" 13635595 "DTC_CONT_F_FAILED_LO" 13635596 "DTC_CONT_G_FAILED_HI" 13635597 "DTC_CONT_G_FAILED_LO" 13635598 "DTC_LSD_A_FAILED_HI" 13635599 "DTC_LSD_A_FAILED_LO" 13635600 "DTC_LSD_B_FAILED_HI" 13635601 "DTC_LSD_B_FAILED_LO" 13635602 "DTC_LSD_C_FAILED_HI" 13635603 "DTC_LSD_C_FAILED_LO" 13635606 "DTC_CONT_PWR_FAILED_HI" 13635607 "DTC_CONT_PWR_FAILED_LO" 13635608 "DTC_LSD_PUMP_FAILED_HI" 13635609 "DTC_LSD_PUMP_FAILED_LO" 13635610 "DTC_CHG_A_ENABLE_FAILED_HI" 13635611 "DTC_CHG_A_ENABLE_FAILED_LO" 13635612 "DTC_CHG_B_ENABLE_FAILED_HI" 13635613 "DTC_CHG_B_ENABLE_FAILED_LO" 13635614 "DTC_SW14V_PWR_FAILED_HI" 13635615 "DTC_SW14V_PWR_FAILED_LO" 13635620 "DTC_HSD_A_FAILED_HI" 13635621 "DTC_HSD_A_FAILED_LO" 13635622 "DTC_HSD_B_FAILED_HI" 13635623 "DTC_HSD_B_FAILED_LO" 13692968 "DTC_CONT_HPWR_FAILED_HI" 13692969 "DTC_CONT_HPWR_FAILED_LO" 13692970 "DTC_CONT_HPWR_OOR_HI" 13692971 "DTC_CONT_HPWR_OOR_LO" 13635616 "DTC_5V_PWR_OOR_HI" 13635617 "DTC_5V_PWR_OOR_LO" 14606336 "DTC_NVM_WRITE_TO" 14606337 "DTC_NVM_READ_TO" 14614528 "DTC_SPI_DIG_POT_FAULT" ;
VAL_ 192 Inverter_Enable 0 "Turn the inverter OFF" 1 "Turn the Inverter ON" ;
VAL_ 192 Direction_Command 0 "CW" 1 "CCW" ;
VAL_ 192 Inverter_Discharge 0 "Discharge Disable" 1 "Discharge Enable (if EEPROM parameter is set)" ;
VAL_ 171 D4_Run_Fault_Hi 8000 "Inverter Discharge Active" ;
VAL_ 171 D1_Post_Fault_Lo 1000 "5 V Sense Low" ;
VAL_ 170 D2_Inverter_State 0 "Power up" 1 "Stop" 2 "Open Loop" 3 "Closed Loop" 4 "Internal State" 5 "Internal State" 6 "Internal State" 7 "Internal State" 8 "Idle Run" 9 "Idle Stop" 10 "Internal State" 11 "Intern State" 12 "Internal State" ;
VAL_ 170 D1_VSM_State 0 "VSM Start State" 1 "Pre-Charge Init state" 2 "pre-charge active state" 3 "pre-charge complete state" 4 "VSM wait state" 5 "VSM ready state" 6 "Motor Running State" 7 "blink fault code state" 14 "Shutdown state for Key Switch Mode 1" 15 "Reset the inverter" ;
